VERSION ""

NS_ :

BS_:

BU_: ETH

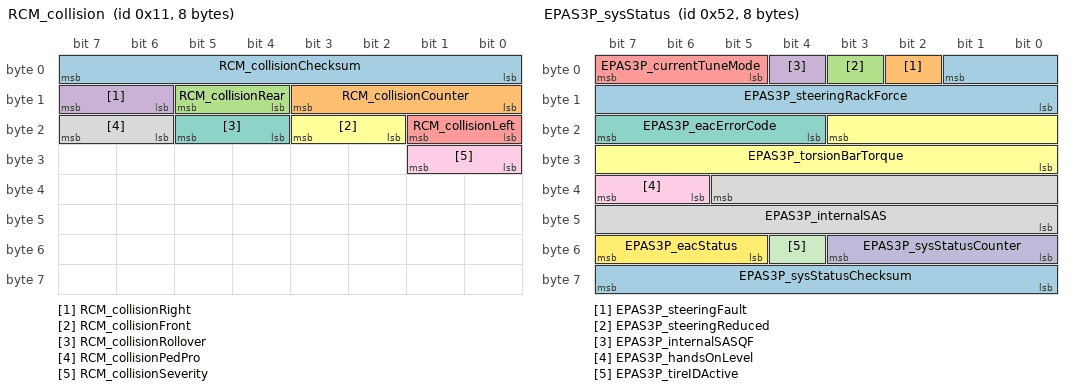
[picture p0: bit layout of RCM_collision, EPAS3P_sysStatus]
BO_ 17 RCM_collision: 8 Vector__XXX
 SG_ RCM_collisionChecksum : 0|8@1+ (1,0) [0|0] "" Vector__XXX
 SG_ RCM_collisionCounter : 8|4@1+ (1,0) [0|0] "" Vector__XXX
 SG_ RCM_collisionRear : 12|2@1+ (1,0) [0|0] "" Vector__XXX
 SG_ RCM_collisionRight : 14|2@1+ (1,0) [0|0] "" Vector__XXX
 SG_ RCM_collisionLeft : 16|2@1+ (1,0) [0|0] "" Vector__XXX
 SG_ RCM_collisionFront : 18|2@1+ (1,0) [0|0] "" Vector__XXX
 SG_ RCM_collisionRollover : 20|2@1+ (1,0) [0|0] "" Vector__XXX
 SG_ RCM_collisionPedPro : 22|2@1+ (1,0) [0|0] "" Vector__XXX
 SG_ RCM_collisionSeverity : 24|2@1+ (1,0) [0|0] "" Vector__XXX

BO_ 49 EPAS3P_status: 8 Vector__XXX
 SG_ EPAS3P_statusCrc : 0|8@1+ (1,0) [0|0] "" Vector__XXX
 SG_ EPAS3P_statusCounter : 8|4@1+ (1,0) [0|0] "" Vector__XXX
 SG_ EPAS3P_state : 12|4@1+ (1,0) [0|0] "" Vector__XXX
 SG_ EPAS3P_powerMode : 16|3@1+ (1,0) [0|0] "" Vector__XXX
 SG_ EPAS3P_role : 19|2@1+ (1,0) [0|0] "" Vector__XXX

BO_ 79 UI_locationStatus: 8 Vector__XXX
 SG_ UI_latitude : 0|28@1- (1e-06,0) [0|0] "" Vector__XXX
 SG_ UI_longitude : 28|29@1- (1e-06,0) [0|0] "" Vector__XXX
 SG_ UI_gpsAccuracy : 57|7@1+ (0.2,0) [0|0] "" Vector__XXX

BO_ 81 EPAS3S_status: 8 Vector__XXX
 SG_ EPAS3S_statusCrc : 0|8@1+ (1,0) [0|0] "" Vector__XXX
 SG_ EPAS3S_statusCounter : 8|4@1+ (1,0) [0|0] "" Vector__XXX
 SG_ EPAS3S_state : 12|4@1+ (1,0) [0|0] "" Vector__XXX
 SG_ EPAS3S_powerMode : 16|3@1+ (1,0) [0|0] "" Vector__XXX
 SG_ EPAS3S_role : 19|2@1+ (1,0) [0|0] "" Vector__XXX

BO_ 82 EPAS3P_sysStatus: 8 Vector__XXX
 SG_ EPAS3P_steeringRackForce : 1|10@0+ (50,-25575) [0|0] "" Vector__XXX
 SG_ EPAS3P_steeringFault : 2|1@0+ (1,0) [0|0] "" Vector__XXX
 SG_ EPAS3P_steeringReduced : 3|1@0+ (1,0) [0|0] "" Vector__XXX
 SG_ EPAS3P_internalSASQF : 4|1@0+ (1,0) [0|0] "" Vector__XXX
 SG_ EPAS3P_currentTuneMode : 7|3@0+ (1,0) [0|0] "" Vector__XXX
 SG_ EPAS3P_torsionBarTorque : 19|12@0+ (0.01,-20.5) [0|0] "" Vector__XXX
 SG_ EPAS3P_eacErrorCode : 23|4@0+ (1,0) [0|0] "" Vector__XXX
 SG_ EPAS3P_internalSAS : 37|14@0+ (0.1,-819.2) [0|0] "" Vector__XXX
 SG_ EPAS3P_handsOnLevel : 39|2@0+ (1,0) [0|0] "" Vector__XXX
 SG_ EPAS3P_sysStatusCounter : 51|4@0+ (1,0) [0|0] "" Vector__XXX
 SG_ EPAS3P_tireIDActive : 52|1@1+ (1,0) [0|0] "" Vector__XXX
 SG_ EPAS3P_eacStatus : 55|3@0+ (1,0) [0|0] "" Vector__XXX
 SG_ EPAS3P_sysStatusChecksum : 63|8@0+ (1,0) [0|0] "" Vector__XXX

BO_ 257 RCM_inertial1: 8 Vector__XXX
 SG_ RCM_yawRate : 0|16@1- (0.0001,0) [0|0] "" Vector__XXX
 SG_ RCM_pitchRate : 16|15@1- (0.00025,0) [0|0] "" Vector__XXX
 SG_ RCM_rollRate : 31|15@1- (0.00025,0) [0|0] "" Vector__XXX
 SG_ RCM_rollRateQF : 46|2@1+ (1,0) [0|0] "" Vector__XXX
 SG_ RCM_yawRateQF : 48|1@1+ (1,0) [0|0] "" Vector__XXX
 SG_ RCM_pitchRateQF : 50|2@1+ (1,0) [0|0] "" Vector__XXX
 SG_ RCM_inertial1Counter : 52|4@1+ (1,0) [0|0] "" Vector__XXX
 SG_ RCM_inertial1Checksum : 56|8@1+ (1,0) [0|0] "" Vector__XXX

BO_ 258 VCLEFT_doorStatus: 8 Vector__XXX
 SG_ VCLEFT_doorClosureStatusFront : 0|4@1+ (1,0) [0|0] "" Vector__XXX
 SG_ VCLEFT_doorClosureStatusRear : 4|4@1+ (1,0) [0|0] "" Vector__XXX
 SG_ VCLEFT_frontLatchSwitch : 8|1@1+ (1,0) [0|0] "" Vector__XXX
 SG_ VCLEFT_rearLatchSwitch : 9|1@1+ (1,0) [0|0] "" Vector__XXX
 SG_ VCLEFT_frontHandlePulled : 10|1@1+ (1,0) [0|0] "" Vector__XXX
 SG_ VCLEFT_rearHandlePulled : 11|1@1+ (1,0) [0|0] "" Vector__XXX
 SG_ VCLEFT_frontRelActuatorSwitch : 12|1@1+ (1,0) [0|0] "" Vector__XXX
 SG_ VCLEFT_rearRelActuatorSwitch : 13|1@1+ (1,0) [0|0] "" Vector__XXX
 SG_ VCLEFT_frontLatchStatus : 14|4@1+ (1,0) [0|0] "" Vector__XXX
 SG_ VCLEFT_rearLatchStatus : 18|4@1+ (1,0) [0|0] "" Vector__XXX
 SG_ VCLEFT_lastDoorReqSourceFront : 22|3@1+ (1,0) [0|0] "" Vector__XXX
 SG_ VCLEFT_lastDoorReqSourceRear : 25|3@1+ (1,0) [0|0] "" Vector__XXX
 SG_ VCLEFT_frontIntSwitchFaulted : 28|1@1+ (1,0) [0|0] "" Vector__XXX
 SG_ VCLEFT_rearIntSwitchFaulted : 29|1@1+ (1,0) [0|0] "" Vector__XXX
 SG_ VCLEFT_frontIntSwitchPressed : 31|1@1+ (1,0) [0|0] "" Vector__XXX
 SG_ VCLEFT_rearIntSwitchPressed : 32|1@1+ (1,0) [0|0] "" Vector__XXX
 SG_ VCLEFT_mirrorTiltXPosition : 33|8@1+ (0.02,0) [0|0] "" Vector__XXX
 SG_ VCLEFT_mirrorTiltYPosition : 41|8@1+ (0.02,0) [0|0] "" Vector__XXX
 SG_ VCLEFT_mirrorState : 49|3@1+ (1,0) [0|0] "" Vector__XXX
 SG_ VCLEFT_mirrorFoldState : 52|3@1+ (1,0) [0|0] "" Vector__XXX
 SG_ VCLEFT_mirrorRecallState : 55|3@1+ (1,0) [0|0] "" Vector__XXX
 SG_ VCLEFT_mirrorHeatState : 58|3@1+ (1,0) [0|0] "" Vector__XXX
 SG_ VCLEFT_rearHandlePulledPersist : 61|1@1+ (1,0) [0|0] "" Vector__XXX
 SG_ VCLEFT_frontHandlePulledPersist : 62|1@1+ (1,0) [0|0] "" Vector__XXX
 SG_ VCLEFT_mirrorDipped : 63|1@1+ (1,0) [0|0] "" Vector__XXX

BO_ 259 VCRIGHT_doorStatus: 8 Vector__XXX
 SG_ VCRIGHT_doorClosureStatusFront : 0|4@1+ (1,0) [0|0] "" Vector__XXX
 SG_ VCRIGHT_doorClosureStatusRear : 4|4@1+ (1,0) [0|0] "" Vector__XXX
 SG_ VCRIGHT_frontLatchSwitch : 8|1@1+ (1,0) [0|0] "" Vector__XXX
 SG_ VCRIGHT_rearLatchSwitch : 9|1@1+ (1,0) [0|0] "" Vector__XXX
 SG_ VCRIGHT_frontHandlePulled : 10|1@1+ (1,0) [0|0] "" Vector__XXX
 SG_ VCRIGHT_rearHandlePulled : 11|1@1+ (1,0) [0|0] "" Vector__XXX
 SG_ VCRIGHT_frontRelActuatorSwitch : 12|1@1+ (1,0) [0|0] "" Vector__XXX
 SG_ VCRIGHT_rearRelActuatorSwitch : 13|1@1+ (1,0) [0|0] "" Vector__XXX
 SG_ VCRIGHT_frontLatchStatus : 14|4@1+ (1,0) [0|0] "" Vector__XXX
 SG_ VCRIGHT_rearLatchStatus : 18|4@1+ (1,0) [0|0] "" Vector__XXX
 SG_ VCRIGHT_lastDoorReqSourceFront : 22|3@1+ (1,0) [0|0] "" Vector__XXX
 SG_ VCRIGHT_lastDoorReqSourceRear : 25|3@1+ (1,0) [0|0] "" Vector__XXX
 SG_ VCRIGHT_frontIntSwitchFaulted : 28|1@1+ (1,0) [0|0] "" Vector__XXX
 SG_ VCRIGHT_rearIntSwitchFaulted : 29|1@1+ (1,0) [0|0] "" Vector__XXX
 SG_ VCRIGHT_frontHandlePulledPersist : 30|1@1+ (1,0) [0|0] "" Vector__XXX
 SG_ VCRIGHT_frontIntSwitchPressed : 31|1@1+ (1,0) [0|0] "" Vector__XXX
 SG_ VCRIGHT_rearIntSwitchPressed : 32|1@1+ (1,0) [0|0] "" Vector__XXX
 SG_ VCRIGHT_mirrorTiltXPosition : 33|8@1+ (0.02,0) [0|0] "" Vector__XXX
 SG_ VCRIGHT_mirrorTiltYPosition : 41|8@1+ (0.02,0) [0|0] "" Vector__XXX
 SG_ VCRIGHT_mirrorState : 49|3@1+ (1,0) [0|0] "" Vector__XXX
 SG_ VCRIGHT_mirrorFoldState : 52|3@1+ (1,0) [0|0] "" Vector__XXX
 SG_ VCRIGHT_mirrorDipped : 55|1@1+ (1,0) [0|0] "" Vector__XXX
 SG_ VCRIGHT_trunkLatchStatus : 56|4@1+ (1,0) [0|0] "" Vector__XXX
 SG_ VCRIGHT_mirrorRecallState : 60|3@1+ (1,0) [0|0] "" Vector__XXX
 SG_ VCRIGHT_rearHandlePulledPersist : 63|1@1+ (1,0) [0|0] "" Vector__XXX

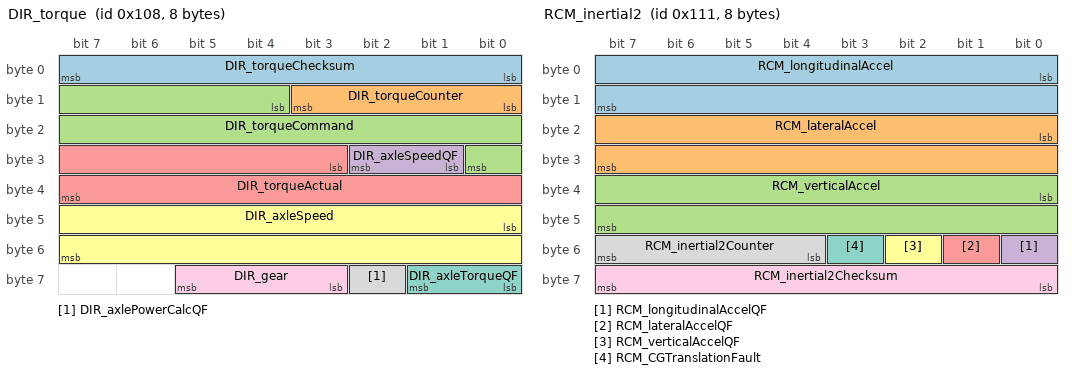
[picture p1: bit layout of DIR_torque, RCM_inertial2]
BO_ 264 DIR_torque: 8 Vector__XXX
 SG_ DIR_torqueChecksum : 0|8@1+ (1,0) [0|0] "" Vector__XXX
 SG_ DIR_torqueCounter : 8|4@1+ (1,0) [0|0] "" Vector__XXX
 SG_ DIR_torqueCommand : 12|13@1- (2,0) [0|0] "" Vector__XXX
 SG_ DIR_axleSpeedQF : 25|2@1+ (1,0) [0|0] "" Vector__XXX
 SG_ DIR_torqueActual : 27|13@1- (2,0) [0|0] "" Vector__XXX
 SG_ DIR_axleSpeed : 40|16@1- (0.1,0) [0|0] "" Vector__XXX
 SG_ DIR_axleTorqueQF : 56|2@1+ (1,0) [0|0] "" Vector__XXX
 SG_ DIR_axlePowerCalcQF : 58|1@1+ (1,0) [0|0] "" Vector__XXX
 SG_ DIR_gear : 59|3@1+ (1,0) [0|0] "" Vector__XXX

BO_ 273 RCM_inertial2: 8 Vector__XXX
 SG_ RCM_longitudinalAccel : 0|16@1- (0.00125,0) [0|0] "" Vector__XXX
 SG_ RCM_lateralAccel : 16|16@1- (0.00125,0) [0|0] "" Vector__XXX
 SG_ RCM_verticalAccel : 32|16@1- (0.00125,0) [0|0] "" Vector__XXX
 SG_ RCM_longitudinalAccelQF : 48|1@1+ (1,0) [0|0] "" Vector__XXX
 SG_ RCM_lateralAccelQF : 49|1@1+ (1,0) [0|0] "" Vector__XXX
 SG_ RCM_verticalAccelQF : 50|1@1+ (1,0) [0|0] "" Vector__XXX
 SG_ RCM_CGTranslationFault : 51|1@1+ (1,0) [0|0] "" Vector__XXX
 SG_ RCM_inertial2Counter : 52|4@1+ (1,0) [0|0] "" Vector__XXX
 SG_ RCM_inertial2Checksum : 56|8@1+ (1,0) [0|0] "" Vector__XXX

BO_ 280 DI_systemStatus: 8 Vector__XXX
 SG_ DI_systemStatusChecksum : 0|8@1+ (1,0) [0|0] "" Vector__XXX
 SG_ DI_systemStatusCounter : 8|4@1+ (1,0) [0|0] "" Vector__XXX
 SG_ DI_immobilizerState : 13|3@1+ (1,0) [0|0] "" Vector__XXX
 SG_ DI_systemState : 16|3@1+ (1,0) [0|0] "" Vector__XXX
 SG_ DI_brakePedalState : 19|2@1+ (1,0) [0|0] "" Vector__XXX
 SG_ DI_gear : 21|3@1+ (1,0) [0|0] "" Vector__XXX
 SG_ DI_driveBlocked : 24|3@1+ (1,0) [0|0] "" Vector__XXX
 SG_ DI_hvilSystemStatus : 27|2@1+ (1,0) [0|0] "" Vector__XXX
 SG_ DI_accelPedalPos : 32|8@1+ (0.4,0) [0|0] "" Vector__XXX
 SG_ DI_tractionControlMode : 40|3@1+ (1,0) [0|0] "" Vector__XXX
 SG_ DI_dynoModeAvailable : 43|1@1+ (1,0) [0|0] "" Vector__XXX
 SG_ DI_epbRequest : 44|2@1+ (1,0) [0|0] "" Vector__XXX
 SG_ DI_eepDeliveryBitStatus : 46|1@1+ (1,0) [0|0] "" Vector__XXX
 SG_ DI_keepDrivePowerStateRequest : 47|1@1+ (1,0) [0|0] "" Vector__XXX
 SG_ DI_trackModeState : 48|2@1+ (1,0) [0|0] "" Vector__XXX
 SG_ DI_manualDrivingProhibited : 50|1@1+ (1,0) [0|0] "" Vector__XXX
 SG_ DI_regenLight : 51|1@1+ (1,0) [0|0] "" Vector__XXX
 SG_ DI_vehicleAcceleration : 52|12@1- (0.01,0) [0|0] "" Vector__XXX

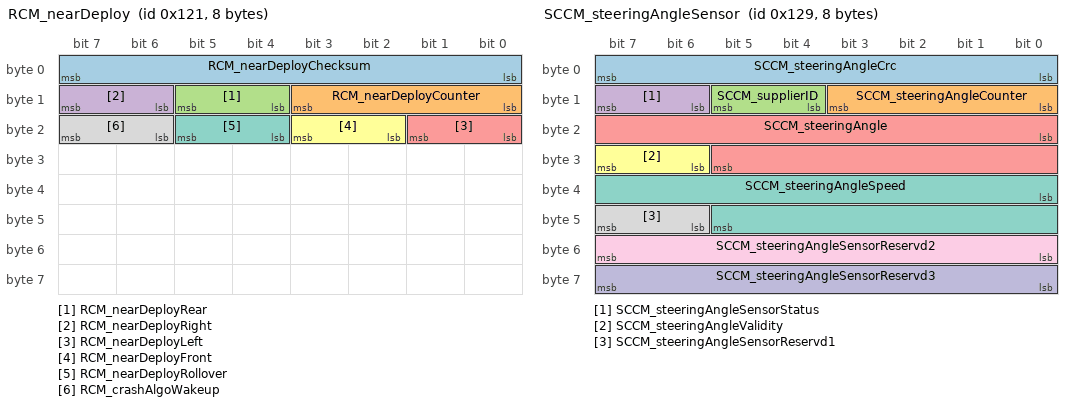
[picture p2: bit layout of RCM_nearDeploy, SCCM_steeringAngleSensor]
BO_ 289 RCM_nearDeploy: 8 Vector__XXX
 SG_ RCM_nearDeployChecksum : 0|8@1+ (1,0) [0|0] "" Vector__XXX
 SG_ RCM_nearDeployCounter : 8|4@1+ (1,0) [0|0] "" Vector__XXX
 SG_ RCM_nearDeployRear : 12|2@1+ (1,0) [0|0] "" Vector__XXX
 SG_ RCM_nearDeployRight : 14|2@1+ (1,0) [0|0] "" Vector__XXX
 SG_ RCM_nearDeployLeft : 16|2@1+ (1,0) [0|0] "" Vector__XXX
 SG_ RCM_nearDeployFront : 18|2@1+ (1,0) [0|0] "" Vector__XXX
 SG_ RCM_nearDeployRollover : 20|2@1+ (1,0) [0|0] "" Vector__XXX
 SG_ RCM_crashAlgoWakeup : 22|2@1+ (1,0) [0|0] "" Vector__XXX

BO_ 297 SCCM_steeringAngleSensor: 8 Vector__XXX
 SG_ SCCM_steeringAngleCrc : 0|8@1+ (1,0) [0|0] "" Vector__XXX
 SG_ SCCM_steeringAngleCounter : 8|4@1+ (1,0) [0|0] "" Vector__XXX
 SG_ SCCM_supplierID : 12|2@1+ (1,0) [0|0] "" Vector__XXX
 SG_ SCCM_steeringAngleSensorStatus : 14|2@1+ (1,0) [0|0] "" Vector__XXX
 SG_ SCCM_steeringAngle : 16|14@1+ (0.1,-819.2) [0|0] "" Vector__XXX
 SG_ SCCM_steeringAngleValidity : 30|2@1+ (1,0) [0|0] "" Vector__XXX
 SG_ SCCM_steeringAngleSpeed : 32|14@1+ (0.5,-4096) [0|0] "" Vector__XXX
 SG_ SCCM_steeringAngleSensorReservd1 : 46|2@1+ (1,0) [0|0] "" Vector__XXX
 SG_ SCCM_steeringAngleSensorReservd2 : 48|8@1+ (1,0) [0|0] "" Vector__XXX
 SG_ SCCM_steeringAngleSensorReservd3 : 56|8@1+ (1,0) [0|0] "" Vector__XXX

BO_ 305 RCM_inertial3: 8 Vector__XXX
 SG_ RCM_yawRateRaw : 0|16@1- (0.0001,0) [0|0] "" Vector__XXX
 SG_ RCM_pitchRateRaw : 16|15@1- (0.00025,0) [0|0] "" Vector__XXX
 SG_ RCM_rollRateRaw : 31|15@1- (0.00025,0) [0|0] "" Vector__XXX
 SG_ RCM_rollRateRawQF : 46|2@1+ (1,0) [0|0] "" Vector__XXX
 SG_ RCM_yawRateRawQF : 48|1@1+ (1,0) [0|0] "" Vector__XXX
 SG_ RCM_pitchRateRawQF : 50|2@1+ (1,0) [0|0] "" Vector__XXX
 SG_ RCM_inertial3Counter : 52|4@1+ (1,0) [0|0] "" Vector__XXX
 SG_ RCM_inertial3Checksum : 56|8@1+ (1,0) [0|0] "" Vector__XXX

BO_ 321 RCM_inertial4: 8 Vector__XXX
 SG_ RCM_longitudinalAccelRaw : 0|16@1- (0.00125,0) [0|0] "" Vector__XXX
 SG_ RCM_lateralAccelRaw : 16|16@1- (0.00125,0) [0|0] "" Vector__XXX
 SG_ RCM_verticalAccelRaw : 32|16@1- (0.00125,0) [0|0] "" Vector__XXX
 SG_ RCM_longitudinalAccelRawQF : 48|1@1+ (1,0) [0|0] "" Vector__XXX
 SG_ RCM_lateralAccelRawQF : 49|1@1+ (1,0) [0|0] "" Vector__XXX
 SG_ RCM_verticalAccelRawQF : 50|1@1+ (1,0) [0|0] "" Vector__XXX
 SG_ RCM_inertial4Counter : 52|4@1+ (1,0) [0|0] "" Vector__XXX
 SG_ RCM_inertial4Checksum : 56|8@1+ (1,0) [0|0] "" Vector__XXX

BO_ 325 ESP_status: 8 Vector__XXX
 SG_ ESP_statusChecksum : 0|8@1+ (1,0) [0|0] "" Vector__XXX
 SG_ ESP_statusCounter : 8|4@1+ (1,0) [0|0] "" Vector__XXX
 SG_ ESP_espModeActive : 12|2@1+ (1,0) [0|0] "" Vector__XXX
 SG_ ESP_stabilityControlSts2 : 14|2@1+ (1,0) [0|0] "" Vector__XXX
 SG_ ESP_ebdFaultLamp : 16|1@1+ (1,0) [0|0] "" Vector__XXX
 SG_ ESP_absFaultLamp : 17|1@1+ (1,0) [0|0] "" Vector__XXX
 SG_ ESP_espFaultLamp : 18|1@1+ (1,0) [0|0] "" Vector__XXX
 SG_ ESP_hydraulicBoostEnabled : 19|1@1+ (1,0) [0|0] "" Vector__XXX
 SG_ ESP_espLampFlash : 20|1@1+ (1,0) [0|0] "" Vector__XXX
 SG_ ESP_brakeLamp : 21|1@1+ (1,0) [0|0] "" Vector__XXX
 SG_ ESP_absBrakeEvent2 : 22|2@1+ (1,0) [0|0] "" Vector__XXX
 SG_ ESP_longitudinalAccelQF : 24|1@1+ (1,0) [0|0] "" Vector__XXX
 SG_ ESP_lateralAccelQF : 25|1@1+ (1,0) [0|0] "" Vector__XXX
 SG_ ESP_yawRateQF : 26|1@1+ (1,0) [0|0] "" Vector__XXX
 SG_ ESP_steeringAngleQF : 27|1@1+ (1,0) [0|0] "" Vector__XXX
 SG_ ESP_brakeDiscWipingActive : 28|1@1+ (1,0) [0|0] "" Vector__XXX
 SG_ ESP_driverBrakeApply : 29|2@1+ (1,0) [0|0] "" Vector__XXX
 SG_ ESP_brakeApply : 31|1@1+ (1,0) [0|0] "" Vector__XXX
 SG_ ESP_aesPrimaryActuatorStatus : 32|2@1+ (1,0) [0|0] "" Vector__XXX
 SG_ ESP_cdpStatus : 34|2@1+ (1,0) [0|0] "" Vector__XXX
 SG_ ESP_ptcTargetState : 36|2@1+ (1,0) [0|0] "" Vector__XXX
 SG_ ESP_btcTargetState : 38|2@1+ (1,0) [0|0] "" Vector__XXX
 SG_ ESP_ebrStandstillSkid : 48|1@1+ (1,0) [0|0] "" Vector__XXX
 SG_ ESP_ebrStatus : 49|2@1+ (1,0) [0|0] "" Vector__XXX
 SG_ ESP_brakeTorqueTarget : 51|13@1+ (3,0) [0|0] "" Vector__XXX

BO_ 331 APP_inertial1: 8 Vector__XXX
 SG_ APP_yawRateRaw : 0|16@1- (0.0001,0) [0|0] "" Vector__XXX
 SG_ APP_pitchRateRaw : 16|15@1- (0.00025,0) [0|0] "" Vector__XXX
 SG_ APP_rollRateRaw : 31|15@1- (0.00025,0) [0|0] "" Vector__XXX
 SG_ APP_gyroscopeBiasCompensationValid : 46|1@1+ (1,0) [0|0] "" Vector__XXX
 SG_ APP_gyroscopeScaleCompensationValid : 47|1@1+ (1,0) [0|0] "" Vector__XXX
 SG_ APP_inertial1Counter : 52|4@1+ (1,0) [0|0] "" Vector__XXX
 SG_ APP_inertial1Checksum : 56|8@1+ (1,0) [0|0] "" Vector__XXX

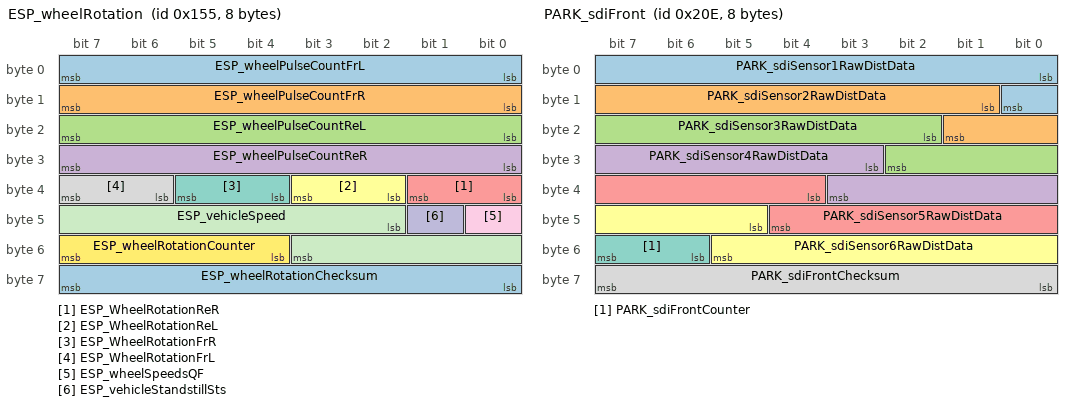
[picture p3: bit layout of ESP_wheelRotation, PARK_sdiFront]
BO_ 341 ESP_wheelRotation: 8 Vector__XXX
 SG_ ESP_wheelPulseCountFrL : 0|8@1+ (1,0) [0|0] "" Vector__XXX
 SG_ ESP_wheelPulseCountFrR : 8|8@1+ (1,0) [0|0] "" Vector__XXX
 SG_ ESP_wheelPulseCountReL : 16|8@1+ (1,0) [0|0] "" Vector__XXX
 SG_ ESP_wheelPulseCountReR : 24|8@1+ (1,0) [0|0] "" Vector__XXX
 SG_ ESP_WheelRotationReR : 32|2@1+ (1,0) [0|0] "" Vector__XXX
 SG_ ESP_WheelRotationReL : 34|2@1+ (1,0) [0|0] "" Vector__XXX
 SG_ ESP_WheelRotationFrR : 36|2@1+ (1,0) [0|0] "" Vector__XXX
 SG_ ESP_WheelRotationFrL : 38|2@1+ (1,0) [0|0] "" Vector__XXX
 SG_ ESP_wheelSpeedsQF : 40|1@1+ (1,0) [0|0] "" Vector__XXX
 SG_ ESP_vehicleStandstillSts : 41|1@1+ (1,0) [0|0] "" Vector__XXX
 SG_ ESP_vehicleSpeed : 42|10@1+ (0.5,0) [0|0] "" Vector__XXX
 SG_ ESP_wheelRotationCounter : 52|4@1+ (1,0) [0|0] "" Vector__XXX
 SG_ ESP_wheelRotationChecksum : 56|8@1+ (1,0) [0|0] "" Vector__XXX

BO_ 373 ESP_wheelSpeeds: 8 Vector__XXX
 SG_ ESP_wheelSpeedFrL : 0|13@1+ (0.042,0) [0|0] "" Vector__XXX
 SG_ ESP_wheelSpeedFrR : 13|13@1+ (0.042,0) [0|0] "" Vector__XXX
 SG_ ESP_wheelSpeedReL : 26|13@1+ (0.042,0) [0|0] "" Vector__XXX
 SG_ ESP_wheelSpeedReR : 39|13@1+ (0.042,0) [0|0] "" Vector__XXX
 SG_ ESP_wheelSpeedsCounter : 52|4@1+ (1,0) [0|0] "" Vector__XXX
 SG_ ESP_wheelSpeedsChecksum : 56|8@1+ (1,0) [0|0] "" Vector__XXX

BO_ 389 ESP_brakeTorque: 8 Vector__XXX
 SG_ ESP_brakeTorqueFrL : 0|12@1+ (3,0) [0|0] "" Vector__XXX
 SG_ ESP_brakeTorqueFrR : 12|12@1+ (3,0) [0|0] "" Vector__XXX
 SG_ ESP_brakeTorqueReL : 24|12@1+ (3,0) [0|0] "" Vector__XXX
 SG_ ESP_brakeTorqueReR : 36|12@1+ (3,0) [0|0] "" Vector__XXX
 SG_ ESP_brakeTorqueQF : 50|1@1+ (1,0) [0|0] "" Vector__XXX
 SG_ ESP_brakeTorqueCounter : 52|4@1+ (1,0) [0|0] "" Vector__XXX
 SG_ ESP_brakeTorqueChecksum : 56|8@1+ (1,0) [0|0] "" Vector__XXX

BO_ 395 APP_inertial2: 8 Vector__XXX
 SG_ APP_longitudinalAccelRaw : 0|16@1- (0.00125,0) [0|0] "" Vector__XXX
 SG_ APP_lateralAccelRaw : 16|16@1- (0.00125,0) [0|0] "" Vector__XXX
 SG_ APP_verticalAccelRaw : 32|16@1- (0.00125,0) [0|0] "" Vector__XXX
 SG_ APP_accelerometerBiasCompensationValid : 48|1@1+ (1,0) [0|0] "" Vector__XXX
 SG_ APP_accelerometerScaleCompensationValid : 49|1@1+ (1,0) [0|0] "" Vector__XXX
 SG_ APP_inertial2Counter : 52|4@1+ (1,0) [0|0] "" Vector__XXX
 SG_ APP_inertial2Checksum : 56|8@1+ (1,0) [0|0] "" Vector__XXX

BO_ 454 GTW_canErrorCounters: 8 Vector__XXX
 SG_ GTW_PARTY_canTxErrCount : 0|8@1+ (1,0) [0|0] "" Vector__XXX
 SG_ GTW_PARTY_canRxErrCount : 8|8@1+ (1,0) [0|0] "" Vector__XXX
 SG_ GTW_VEH_canTxErrCount : 16|8@1+ (1,0) [0|0] "" Vector__XXX
 SG_ GTW_VEH_canRxErrCount : 24|8@1+ (1,0) [0|0] "" Vector__XXX
 SG_ GTW_CH_canTxErrCount : 32|8@1+ (1,0) [0|0] "" Vector__XXX
 SG_ GTW_CH_canRxErrCount : 40|8@1+ (1,0) [0|0] "" Vector__XXX

BO_ 521 DAS_longControl: 8 Vector__XXX
 SG_ DAS_longControlChecksum : 0|8@1+ (1,0) [0|0] "" Vector__XXX
 SG_ DAS_longControlCounter : 8|3@1+ (1,0) [0|0] "" Vector__XXX
 SG_ DAS_gearRequest : 11|2@1+ (1,0) [0|0] "" Vector__XXX
 SG_ DAS_velocityProfile_accelFwd_t0 m3 : 13|11@1- (0.012,-0.216) [0|0] "" Vector__XXX
 SG_ DAS_torqueProfiler_accelMinPed m2 : 14|9@1+ (0.04,-15) [0|0] "" Vector__XXX
 SG_ DAS_aebControl_active m4 : 16|2@1+ (1,0) [0|0] "" Vector__XXX
 SG_ DAS_pedalControl_accelPedalPos m5 : 16|12@1+ (0.025,0) [0|0] "" Vector__XXX
 SG_ DAS_torqueControl_sysTorqueCommandFwd m6 : 16|15@1- (2,0) [0|0] "" Vector__XXX
 SG_ DAS_aebControl_targetAccelDis m4 : 18|11@1- (0.01,-7.5) [0|0] "" Vector__XXX
 SG_ DAS_torqueProfiler_accelMaxPed m2 : 23|9@1+ (0.04,-15) [0|0] "" Vector__XXX
 SG_ DAS_velocityProfile_jerkFwd_t0t1 m3 : 24|8@1- (0.12,0) [0|0] "" Vector__XXX
 SG_ DAS_pedalControl_brakeTorqueCommand m5 : 32|13@1+ (3.5,0) [0|0] "" Vector__XXX
 SG_ DAS_torqueControl_standstillRequest m6 : 32|1@1+ (1,0) [0|0] "" Vector__XXX
 SG_ DAS_torqueProfiler_targetSpeedPed m2 : 32|12@1+ (0.1,0) [0|0] "" Vector__XXX
 SG_ DAS_velocityProfile_futureTargetSpeedFwd m3 : 32|12@1- (0.08,80.08) [0|0] "" Vector__XXX
 SG_ DAS_torqueProfiler_jerkMinPed m2 : 44|9@1+ (0.03,-15.232) [0|0] "" Vector__XXX
 SG_ DAS_velocityProfile_jerkFwd_t1t2 m3 : 44|8@1- (0.12,0) [0|0] "" Vector__XXX
 SG_ DAS_velocityProfile_maxAllowedTargetErrorReg m3 : 52|6@1- (0.1,1.1) [0|0] "" Vector__XXX
 SG_ DAS_torqueProfiler_jerkMaxPed m2 : 53|8@1+ (0.059,0) [0|0] "" Vector__XXX
 SG_ DAS_velocityProfile_calcDelay m3 : 58|3@1+ (0.006666666666666667,0) [0|0] "" Vector__XXX
 SG_ DAS_longControlStack M : 61|3@1+ (1,0) [0|0] "" Vector__XXX

BO_ 522 DAS_longControlTuningParameters: 8 Vector__XXX
 SG_ DAS_longControlTuningParametersChecksum : 0|8@1+ (1,0) [0|0] "" Vector__XXX
 SG_ DAS_longControlTuningParametersCounter : 8|3@1+ (1,0) [0|0] "" Vector__XXX
 SG_ DAS_velocityProfile_delayBeforet0 : 11|7@1+ (0.01,0) [0|0] "" Vector__XXX
 SG_ DAS_velocityProfile_futureTargetSpeedFwdDt : 18|7@1+ (0.01,0) [0|0] "" Vector__XXX
 SG_ DAS_velocityProfile_Dt_t0t1 : 32|7@1+ (0.01,0) [0|0] "" Vector__XXX
 SG_ DAS_velocityProfile_Dt_t1t2 : 39|7@1+ (0.01,0) [0|0] "" Vector__XXX

BO_ 526 PARK_sdiFront: 8 Vector__XXX
 SG_ PARK_sdiSensor1RawDistData : 0|9@1+ (1,0) [0|0] "" Vector__XXX
 SG_ PARK_sdiSensor2RawDistData : 9|9@1+ (1,0) [0|0] "" Vector__XXX
 SG_ PARK_sdiSensor3RawDistData : 18|9@1+ (1,0) [0|0] "" Vector__XXX
 SG_ PARK_sdiSensor4RawDistData : 27|9@1+ (1,0) [0|0] "" Vector__XXX
 SG_ PARK_sdiSensor5RawDistData : 36|9@1+ (1,0) [0|0] "" Vector__XXX
 SG_ PARK_sdiSensor6RawDistData : 45|9@1+ (1,0) [0|0] "" Vector__XXX
 SG_ PARK_sdiFrontCounter : 54|2@1+ (1,0) [0|0] "" Vector__XXX
 SG_ PARK_sdiFrontChecksum : 56|8@1+ (1,0) [0|0] "" Vector__XXX

BO_ 529 RCM_status: 8 Vector__XXX
 SG_ RCM_statusChecksum : 0|8@1+ (1,0) [0|0] "" Vector__XXX
 SG_ RCM_statusCounter : 8|4@1+ (1,0) [0|0] "" Vector__XXX
 SG_ RCM_armStatus : 12|2@1+ (1,0) [0|0] "" Vector__XXX
 SG_ RCM_warningIndicatorState : 14|2@1+ (1,0) [0|0] "" Vector__XXX
 SG_ RCM_passAirbagIndicatorRequest : 16|2@1+ (1,0) [0|0] "" Vector__XXX
 SG_ RCM_airbagCutoffStatus : 18|2@1+ (1,0) [0|0] "" Vector__XXX
 SG_ RCM_alrSwitchStatus : 20|2@1+ (1,0) [0|0] "" Vector__XXX
 SG_ RCM_vinLearnFlag : 22|2@1+ (1,0) [0|0] "" Vector__XXX
 SG_ RCM_seatTrackPositionDrvr : 24|2@1+ (1,0) [0|0] "" Vector__XXX
 SG_ RCM_seatTrackPositionPass : 26|2@1+ (1,0) [0|0] "" Vector__XXX
 SG_ RCM_edr1State : 28|2@1+ (1,0) [0|0] "" Vector__XXX
 SG_ RCM_edr2State : 30|2@1+ (1,0) [0|0] "" Vector__XXX
 SG_ RCM_keepPowerReason : 32|4@1+ (1,0) [0|0] "" Vector__XXX
 SG_ RCM_imuOffsetLearnState : 36|2@1+ (1,0) [0|0] "" Vector__XXX
 SG_ RCM_edr3State : 38|2@1+ (1,0) [0|0] "" Vector__XXX
 SG_ RCM_driverOrientationInitStatus : 40|3@1+ (1,0) [0|0] "" Vector__XXX
 SG_ RCM_occupantClassificationSource : 43|1@1+ (1,0) [0|0] "" Vector__XXX
 SG_ RCM_pedProEDR1State : 44|2@1+ (1,0) [0|0] "" Vector__XXX
 SG_ RCM_pedProEDR2State : 46|2@1+ (1,0) [0|0] "" Vector__XXX

BO_ 536 UI_driverAssistRoadSign: 8 Vector__XXX
 SG_ UI_roadSign M : 0|8@1+ (1,0) [0|0] "" Vector__XXX
 SG_ UI_baseMapSpeedLimitMPS m3 : 8|8@1+ (0.25,0) [0|0] "" Vector__XXX
 SG_ UI_currSplineIdFull m5 : 8|32@1+ (1,0) [0|0] "" Vector__XXX
 SG_ UI_dummyData m0 : 8|1@1+ (1,0) [0|0] "" Vector__XXX
 SG_ UI_meanFleetSplineSpeedMPS m4 : 8|8@1+ (0.25,0) [0|0] "" Vector__XXX
 SG_ UI_stopSignStopLineDist m1 : 8|10@1+ (0.25,-8) [0|0] "" Vector__XXX
 SG_ UI_trafficLightStopLineDist m2 : 8|10@1+ (0.25,-8) [0|0] "" Vector__XXX
 SG_ UI_bottomQrtlFleetSpeedMPS m3 : 16|8@1+ (0.25,0) [0|0] "" Vector__XXX
 SG_ UI_medianFleetSpeedMPS m4 : 16|8@1+ (0.25,0) [0|0] "" Vector__XXX
 SG_ UI_stopSignStopLineConf m1 : 18|7@1+ (1,0) [0|0] "" Vector__XXX
 SG_ UI_trafficLightStopLineConf m2 : 18|7@1+ (1,0) [0|0] "" Vector__XXX
 SG_ UI_meanFleetSplineAccelMPS2 m4 : 24|8@1+ (0.05,-6.35) [0|0] "" Vector__XXX
 SG_ UI_topQrtlFleetSpeedMPS m3 : 24|8@1+ (0.25,0) [0|0] "" Vector__XXX
 SG_ UI_rampType m4 : 32|3@1+ (1,0) [0|0] "" Vector__XXX
 SG_ UI_valhallaRamp m4 : 35|2@1+ (1,0) [0|0] "" Vector__XXX
 SG_ UI_overrideACMFleetSpeed m4 : 38|1@1+ (1,0) [0|0] "" Vector__XXX
 SG_ UI_splineLocConfidence : 40|7@1+ (1,0) [0|0] "" Vector__XXX
 SG_ UI_splineID : 48|4@1+ (1,0) [0|0] "" Vector__XXX
 SG_ UI_roadSignCounter : 52|4@1+ (1,0) [0|0] "" Vector__XXX
 SG_ UI_roadSignChecksum : 56|8@1+ (1,0) [0|0] "" Vector__XXX

BO_ 537 DAS_pscControl: 8 Vector__XXX
 SG_ DAS_pscControlCounter : 0|4@1+ (1,0) [0|0] "" Vector__XXX
 SG_ DAS_pscParkState : 4|4@1+ (1,0) [0|0] "" Vector__XXX
 SG_ DAS_eacState : 8|3@1+ (1,0) [0|0] "" Vector__XXX
 SG_ DAS_wheelType : 11|5@1+ (1,0) [0|0] "" Vector__XXX
 SG_ DAS_pscControlChecksum : 16|8@1+ (1,0) [0|0] "" Vector__XXX

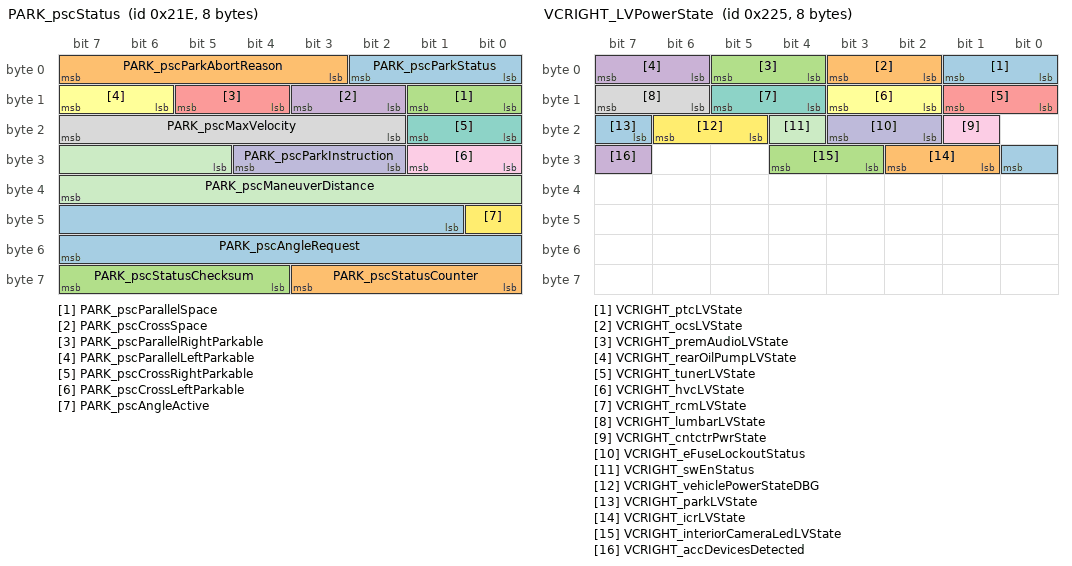
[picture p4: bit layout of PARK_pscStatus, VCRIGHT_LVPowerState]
BO_ 542 PARK_pscStatus: 8 Vector__XXX
 SG_ PARK_pscParkStatus : 0|3@1+ (1,0) [0|0] "" Vector__XXX
 SG_ PARK_pscParkAbortReason : 3|5@1+ (1,0) [0|0] "" Vector__XXX
 SG_ PARK_pscParallelSpace : 8|2@1+ (1,0) [0|0] "" Vector__XXX
 SG_ PARK_pscCrossSpace : 10|2@1+ (1,0) [0|0] "" Vector__XXX
 SG_ PARK_pscParallelRightParkable : 12|2@1+ (1,0) [0|0] "" Vector__XXX
 SG_ PARK_pscParallelLeftParkable : 14|2@1+ (1,0) [0|0] "" Vector__XXX
 SG_ PARK_pscCrossRightParkable : 16|2@1+ (1,0) [0|0] "" Vector__XXX
 SG_ PARK_pscMaxVelocity : 18|6@1+ (0.1,0) [0|0] "" Vector__XXX
 SG_ PARK_pscCrossLeftParkable : 24|2@1+ (1,0) [0|0] "" Vector__XXX
 SG_ PARK_pscParkInstruction : 26|3@1+ (1,0) [0|0] "" Vector__XXX
 SG_ PARK_pscManeuverDistance : 29|11@1+ (1,0) [0|0] "" Vector__XXX
 SG_ PARK_pscAngleActive : 40|1@1+ (1,0) [0|0] "" Vector__XXX
 SG_ PARK_pscAngleRequest : 41|15@1+ (0.1,-1638.4) [0|0] "" Vector__XXX
 SG_ PARK_pscStatusCounter : 56|4@1+ (1,0) [0|0] "" Vector__XXX
 SG_ PARK_pscStatusChecksum : 60|4@1+ (1,0) [0|0] "" Vector__XXX

BO_ 545 VCFRONT_LVPowerState: 8 Vector__XXX
 SG_ VCFRONT_LVPowerStateIndex M : 0|5@1+ (1,0) [0|0] "" Vector__XXX
 SG_ VCFRONT_vehiclePowerState : 5|2@1+ (1,0) [0|0] "" Vector__XXX
 SG_ VCFRONT_cpLVRequest m1 : 8|2@1+ (1,0) [0|0] "" Vector__XXX
 SG_ VCFRONT_parkLVState m0 : 8|2@1+ (1,0) [0|0] "" Vector__XXX
 SG_ VCFRONT_epasLVState m1 : 10|2@1+ (1,0) [0|0] "" Vector__XXX
 SG_ VCFRONT_espLVState m0 : 10|2@1+ (1,0) [0|0] "" Vector__XXX
 SG_ VCFRONT_hvcLVRequest m1 : 12|2@1+ (1,0) [0|0] "" Vector__XXX
 SG_ VCFRONT_radcLVState m0 : 12|2@1+ (1,0) [0|0] "" Vector__XXX
 SG_ VCFRONT_hvacCompLVState m0 : 14|2@1+ (1,0) [0|0] "" Vector__XXX
 SG_ VCFRONT_tasLVState m1 : 14|2@1+ (1,0) [0|0] "" Vector__XXX
 SG_ VCFRONT_pcsLVState m1 : 16|2@1+ (1,0) [0|0] "" Vector__XXX
 SG_ VCFRONT_ptcLVRequest m0 : 16|2@1+ (1,0) [0|0] "" Vector__XXX
 SG_ VCFRONT_CMPDLVState m1 : 18|2@1+ (1,0) [0|0] "" Vector__XXX
 SG_ VCFRONT_sccmLVRequest m0 : 18|2@1+ (1,0) [0|0] "" Vector__XXX
 SG_ VCFRONT_hcmlLVState m1 : 20|2@1+ (1,0) [0|0] "" Vector__XXX
 SG_ VCFRONT_tpmsLVRequest m0 : 20|2@1+ (1,0) [0|0] "" Vector__XXX
 SG_ VCFRONT_hcmrLVState m1 : 22|2@1+ (1,0) [0|0] "" Vector__XXX
 SG_ VCFRONT_rcmLVRequest m0 : 22|2@1+ (1,0) [0|0] "" Vector__XXX
 SG_ VCFRONT_MCUAudioLVState m1 : 24|2@1+ (1,0) [0|0] "" Vector__XXX
 SG_ VCFRONT_iBoosterLVState m0 : 24|2@1+ (1,0) [0|0] "" Vector__XXX
 SG_ VCFRONT_espValveLVState m1 : 26|2@1+ (1,0) [0|0] "" Vector__XXX
 SG_ VCFRONT_tunerLVRequest m0 : 26|2@1+ (1,0) [0|0] "" Vector__XXX
 SG_ VCFRONT_MCUGraphicsLVState m1 : 28|2@1+ (1,0) [0|0] "" Vector__XXX
 SG_ VCFRONT_amplifierLVRequest m0 : 28|2@1+ (1,0) [0|0] "" Vector__XXX
 SG_ VCFRONT_das1HighCurrentLVState m0 : 30|2@1+ (1,0) [0|0] "" Vector__XXX
 SG_ VC_dcdcSupportRequest m1 : 30|1@1+ (1,0) [0|0] "" Vector__XXX
 SG_ VC_hvStateRequest m1 : 31|3@1+ (1,0) [0|0] "" Vector__XXX
 SG_ VCFRONT_das2HighCurrentLVState m0 : 32|2@1+ (1,0) [0|0] "" Vector__XXX
 SG_ VCFRONT_dirLVRequest m0 : 34|2@1+ (1,0) [0|0] "" Vector__XXX
 SG_ VCFRONT_difLVState m0 : 36|2@1+ (1,0) [0|0] "" Vector__XXX
 SG_ VCFRONT_oilPumpFrontLVState m0 : 38|2@1+ (1,0) [0|0] "" Vector__XXX
 SG_ VC_persistAccPowerRequestOverridden m1 : 39|1@1+ (1,0) [0|0] "" Vector__XXX
 SG_ VCFRONT_oilPumpRearLVRequest m0 : 40|2@1+ (1,0) [0|0] "" Vector__XXX
 SG_ VC_accPortPowerRequest m1 : 40|1@1+ (1,0) [0|0] "" Vector__XXX
 SG_ VC_persistAccPortPowerState m1 : 41|3@1+ (1,0) [0|0] "" Vector__XXX
 SG_ VCFRONT_ocsLVRequest m0 : 42|2@1+ (1,0) [0|0] "" Vector__XXX
 SG_ VCFRONT_vcleftHiCurrentLVState m0 : 44|2@1+ (1,0) [0|0] "" Vector__XXX
 SG_ VCFRONT_vcrightHiCurrentLVState m0 : 46|2@1+ (1,0) [0|0] "" Vector__XXX
 SG_ VC_noAccDeviceDetectedWhileIdle m1 : 46|1@1+ (1,0) [0|0] "" Vector__XXX
 SG_ VCFRONT_uiHiCurrentLVState m0 : 48|2@1+ (1,0) [0|0] "" Vector__XXX
 SG_ VCFRONT_inAccessoryPlus : 50|1@1+ (1,0) [0|0] "" Vector__XXX
 SG_ VCFRONT_LVShuttingDown : 51|1@1+ (1,0) [0|0] "" Vector__XXX
 SG_ VCFRONT_LVPowerStateCounter : 52|4@1+ (1,0) [0|0] "" Vector__XXX
 SG_ VCFRONT_LVPowerStateChecksum : 56|8@1+ (1,0) [0|0] "" Vector__XXX

BO_ 549 VCRIGHT_LVPowerState: 8 Vector__XXX
 SG_ VCRIGHT_ptcLVState : 0|2@1+ (1,0) [0|0] "" Vector__XXX
 SG_ VCRIGHT_ocsLVState : 2|2@1+ (1,0) [0|0] "" Vector__XXX
 SG_ VCRIGHT_premAudioLVState : 4|2@1+ (1,0) [0|0] "" Vector__XXX
 SG_ VCRIGHT_rearOilPumpLVState : 6|2@1+ (1,0) [0|0] "" Vector__XXX
 SG_ VCRIGHT_tunerLVState : 8|2@1+ (1,0) [0|0] "" Vector__XXX
 SG_ VCRIGHT_hvcLVState : 10|2@1+ (1,0) [0|0] "" Vector__XXX
 SG_ VCRIGHT_rcmLVState : 12|2@1+ (1,0) [0|0] "" Vector__XXX
 SG_ VCRIGHT_lumbarLVState : 14|2@1+ (1,0) [0|0] "" Vector__XXX
 SG_ VCRIGHT_cntctrPwrState : 17|1@1+ (1,0) [0|0] "" Vector__XXX
 SG_ VCRIGHT_eFuseLockoutStatus : 18|2@1+ (1,0) [0|0] "" Vector__XXX
 SG_ VCRIGHT_swEnStatus : 20|1@1+ (1,0) [0|0] "" Vector__XXX
 SG_ VCRIGHT_vehiclePowerStateDBG : 21|2@1+ (1,0) [0|0] "" Vector__XXX
 SG_ VCRIGHT_parkLVState : 23|2@1+ (1,0) [0|0] "" Vector__XXX
 SG_ VCRIGHT_icrLVState : 25|2@1+ (1,0) [0|0] "" Vector__XXX
 SG_ VCRIGHT_interiorCameraLedLVState : 27|2@1+ (1,0) [0|0] "" Vector__XXX
 SG_ VCRIGHT_accDevicesDetected : 31|1@1+ (1,0) [0|0] "" Vector__XXX

BO_ 551 OCS1P_debugCushionMutCNT: 8 Vector__XXX
 SG_ OCS1P_cushionMutCNTFreq : 0|32@1+ (1,0) [0|0] "" Vector__XXX
 SG_ OCS1P_cushionMutCNTDuty : 32|16@1+ (1,0) [0|0] "" Vector__XXX
 SG_ OCS1P_cushionMutCNTFreqMed : 48|16@1+ (10,0) [0|0] "" Vector__XXX

BO_ 552 GTW_airbagCutoffStatus: 8 Vector__XXX
 SG_ GTW_airbagCutoffSwState : 0|2@1+ (1,0) [0|0] "" Vector__XXX
 SG_ GTW_warningIndicatorStatus : 2|2@1+ (1,0) [0|0] "" Vector__XXX
 SG_ GTW_airbagCutoffStatusCounter : 4|4@1+ (1,0) [0|0] "" Vector__XXX
 SG_ GTW_airbagCutoffStatusChecksum : 8|8@1+ (1,0) [0|0] "" Vector__XXX

BO_ 553 OCS1P_debugCushionSelfCNT: 8 Vector__XXX
 SG_ OCS1P_cushionSelfCNTFreq : 0|32@1+ (1,0) [0|0] "" Vector__XXX
 SG_ OCS1P_cushionSelfCNTDuty : 32|16@1+ (1,0) [0|0] "" Vector__XXX
 SG_ OCS1P_cushionSelfCNTFreqMed : 48|16@1+ (10,0) [0|0] "" Vector__XXX

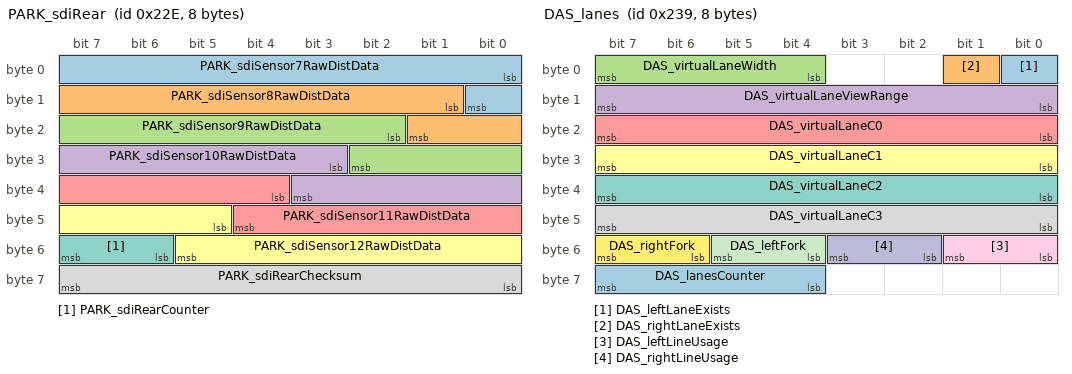
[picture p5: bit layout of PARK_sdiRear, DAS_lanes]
BO_ 558 PARK_sdiRear: 8 Vector__XXX
 SG_ PARK_sdiSensor7RawDistData : 0|9@1+ (1,0) [0|0] "" Vector__XXX
 SG_ PARK_sdiSensor8RawDistData : 9|9@1+ (1,0) [0|0] "" Vector__XXX
 SG_ PARK_sdiSensor9RawDistData : 18|9@1+ (1,0) [0|0] "" Vector__XXX
 SG_ PARK_sdiSensor10RawDistData : 27|9@1+ (1,0) [0|0] "" Vector__XXX
 SG_ PARK_sdiSensor11RawDistData : 36|9@1+ (1,0) [0|0] "" Vector__XXX
 SG_ PARK_sdiSensor12RawDistData : 45|9@1+ (1,0) [0|0] "" Vector__XXX
 SG_ PARK_sdiRearCounter : 54|2@1+ (1,0) [0|0] "" Vector__XXX
 SG_ PARK_sdiRearChecksum : 56|8@1+ (1,0) [0|0] "" Vector__XXX

BO_ 561 OCS1P_debugSeatbackSelfCNT: 8 Vector__XXX
 SG_ OCS1P_seatbackSelfCNTFreq : 0|32@1+ (1,0) [0|0] "" Vector__XXX
 SG_ OCS1P_seatbackSelfCNTDuty : 32|16@1+ (1,0) [0|0] "" Vector__XXX
 SG_ OCS1P_seatbackSelfCNTFreqMed : 48|16@1+ (10,0) [0|0] "" Vector__XXX

BO_ 564 OCS1P_debugCalibration: 8 Vector__XXX
 SG_ OCS1P_debugCalibrationIndex M : 0|2@1+ (1,0) [0|0] "" Vector__XXX
 SG_ OCS1P_cushionMutCalibEmptyFreq m1 : 8|16@1+ (1,0) [0|0] "" Vector__XXX
 SG_ OCS1P_cushionSelfCalibEmptyFreq m0 : 8|16@1+ (1,0) [0|0] "" Vector__XXX
 SG_ OCS1P_cushionSelfOffsetHCB m3 : 8|16@1- (0.005,0) [0|0] "" Vector__XXX
 SG_ OCS1P_temperatureCalib m2 : 8|16@1- (0.1,0) [0|0] "" Vector__XXX
 SG_ OCS1P_cushionMutCalibSmallFreq m1 : 24|16@1+ (1,0) [0|0] "" Vector__XXX
 SG_ OCS1P_humidityCalib m2 : 24|16@1+ (0.1,0) [0|0] "" Vector__XXX
 SG_ OCS1P_seatbackSelfCalibEmptyFreq m0 : 24|16@1+ (1,0) [0|0] "" Vector__XXX
 SG_ OCS1P_seatbackSelfOffsetHCB m3 : 24|16@1- (0.005,0) [0|0] "" Vector__XXX
 SG_ OCS1P_cushionMutCalibLargeFreq m1 : 40|16@1+ (1,0) [0|0] "" Vector__XXX

BO_ 565 OCS1P_debugTHS: 8 Vector__XXX
 SG_ OCS1P_temperature : 0|16@1- (0.1,0) [0|0] "" Vector__XXX
 SG_ OCS1P_humidity : 16|16@1+ (0.1,0) [0|0] "" Vector__XXX

BO_ 568 UI_driverAssistMapData: 8 Vector__XXX
 SG_ UI_mapSpeedLimitDependency : 0|3@1+ (1,0) [0|0] "" Vector__XXX
 SG_ UI_roadClass : 3|3@1+ (1,0) [0|0] "" Vector__XXX
 SG_ UI_inSuperchargerGeofence : 6|1@1+ (1,0) [0|0] "" Vector__XXX
 SG_ UI_mapSpeedUnits : 7|1@1+ (1,0) [0|0] "" Vector__XXX
 SG_ UI_mapSpeedLimit : 8|5@1+ (1,0) [0|0] "" Vector__XXX
 SG_ UI_mapSpeedLimitType : 13|3@1+ (1,0) [0|0] "" Vector__XXX
 SG_ UI_countryCode : 16|10@1+ (1,0) [0|0] "" Vector__XXX
 SG_ UI_streetCount : 26|2@1+ (1,0) [0|0] "" Vector__XXX
 SG_ UI_gpsRoadMatch : 28|1@1+ (1,0) [0|0] "" Vector__XXX
 SG_ UI_navRouteActive : 29|1@1+ (1,0) [0|0] "" Vector__XXX
 SG_ UI_parallelAutoparkEnabled : 30|1@1+ (1,0) [0|0] "" Vector__XXX
 SG_ UI_perpendicularAutoparkEnabled : 31|1@1+ (1,0) [0|0] "" Vector__XXX
 SG_ UI_nextBranchDist : 32|5@1+ (10,0) [0|0] "" Vector__XXX
 SG_ UI_controlledAccess : 37|1@1+ (1,0) [0|0] "" Vector__XXX
 SG_ UI_nextBranchLeftOffRamp : 38|1@1+ (1,0) [0|0] "" Vector__XXX
 SG_ UI_nextBranchRightOffRamp : 39|1@1+ (1,0) [0|0] "" Vector__XXX
 SG_ UI_rejectLeftLane : 40|1@1+ (1,0) [0|0] "" Vector__XXX
 SG_ UI_rejectRightLane : 41|1@1+ (1,0) [0|0] "" Vector__XXX
 SG_ UI_rejectHPP : 42|1@1+ (1,0) [0|0] "" Vector__XXX
 SG_ UI_rejectNav : 43|1@1+ (1,0) [0|0] "" Vector__XXX
 SG_ UI_rejectLeftFreeSpace : 44|1@1+ (1,0) [0|0] "" Vector__XXX
 SG_ UI_rejectRightFreeSpace : 45|1@1+ (1,0) [0|0] "" Vector__XXX
 SG_ UI_rejectAutosteer : 46|1@1+ (1,0) [0|0] "" Vector__XXX
 SG_ UI_rejectHandsOn : 47|1@1+ (1,0) [0|0] "" Vector__XXX
 SG_ UI_acceptBottsDots : 48|1@1+ (1,0) [0|0] "" Vector__XXX
 SG_ UI_autosteerRestricted : 49|1@1+ (1,0) [0|0] "" Vector__XXX
 SG_ UI_pmmEnabled : 50|1@1+ (1,0) [0|0] "" Vector__XXX
 SG_ UI_scaEnabled : 51|1@1+ (1,0) [0|0] "" Vector__XXX
 SG_ UI_mapDataCounter : 52|4@1+ (1,0) [0|0] "" Vector__XXX
 SG_ UI_mapDataChecksum : 56|8@1+ (1,0) [0|0] "" Vector__XXX

BO_ 569 DAS_lanes: 8 Vector__XXX
 SG_ DAS_leftLaneExists : 0|1@1+ (1,0) [0|0] "" Vector__XXX
 SG_ DAS_rightLaneExists : 1|1@1+ (1,0) [0|0] "" Vector__XXX
 SG_ DAS_virtualLaneWidth : 4|4@1+ (0.3125,2) [0|0] "" Vector__XXX
 SG_ DAS_virtualLaneViewRange : 8|8@1+ (1,0) [0|0] "" Vector__XXX
 SG_ DAS_virtualLaneC0 : 16|8@1+ (0.035,-3.5) [0|0] "" Vector__XXX
 SG_ DAS_virtualLaneC1 : 24|8@1+ (0.0016,-0.2) [0|0] "" Vector__XXX
 SG_ DAS_virtualLaneC2 : 32|8@1+ (2e-05,-0.0025) [0|0] "" Vector__XXX
 SG_ DAS_virtualLaneC3 : 40|8@1+ (2.4e-07,-3e-05) [0|0] "" Vector__XXX
 SG_ DAS_leftLineUsage : 48|2@1+ (1,0) [0|0] "" Vector__XXX
 SG_ DAS_rightLineUsage : 50|2@1+ (1,0) [0|0] "" Vector__XXX
 SG_ DAS_leftFork : 52|2@1+ (1,0) [0|0] "" Vector__XXX
 SG_ DAS_rightFork : 54|2@1+ (1,0) [0|0] "" Vector__XXX
 SG_ DAS_lanesCounter : 60|4@1+ (1,0) [0|0] "" Vector__XXX

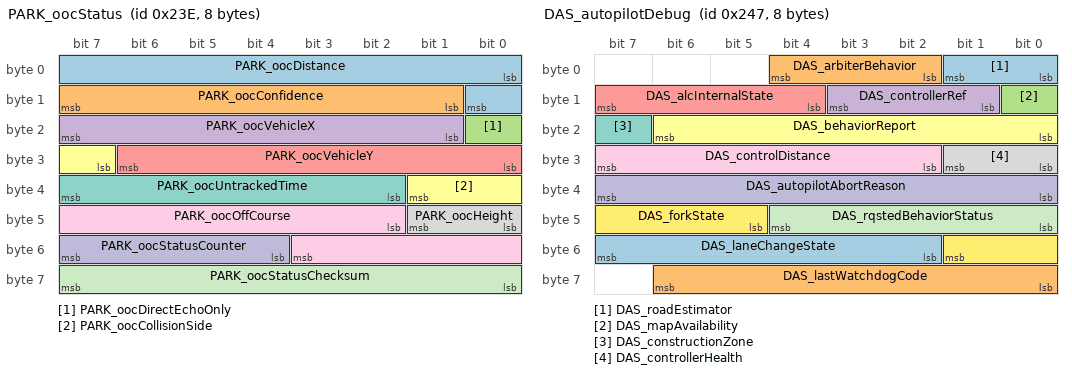
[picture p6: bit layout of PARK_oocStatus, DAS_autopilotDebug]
BO_ 574 PARK_oocStatus: 8 Vector__XXX
 SG_ PARK_oocDistance : 0|9@1+ (1,0) [0|0] "" Vector__XXX
 SG_ PARK_oocConfidence : 9|7@1+ (1,0) [0|0] "" Vector__XXX
 SG_ PARK_oocDirectEchoOnly : 16|1@1+ (1,0) [0|0] "" Vector__XXX
 SG_ PARK_oocVehicleX : 17|7@1+ (4,-114) [0|0] "" Vector__XXX
 SG_ PARK_oocVehicleY : 24|7@1+ (2,-128) [0|0] "" Vector__XXX
 SG_ PARK_oocCollisionSide : 31|3@1+ (1,0) [0|0] "" Vector__XXX
 SG_ PARK_oocUntrackedTime : 34|6@1+ (0.1,0) [0|0] "" Vector__XXX
 SG_ PARK_oocHeight : 40|2@1+ (1,0) [0|0] "" Vector__XXX
 SG_ PARK_oocOffCourse : 42|10@1+ (1,-512) [0|0] "" Vector__XXX
 SG_ PARK_oocStatusCounter : 52|4@1+ (1,0) [0|0] "" Vector__XXX
 SG_ PARK_oocStatusChecksum : 56|8@1+ (1,0) [0|0] "" Vector__XXX

BO_ 576 PM_state2: 8 Vector__XXX
 SG_ PM_state2Checksum : 0|8@1+ (1,0) [0|0] "" Vector__XXX
 SG_ PM_state2Counter : 8|4@1+ (1,0) [0|0] "" Vector__XXX
 SG_ PM_vdcCmdState : 12|1@1+ (1,0) [0|0] "" Vector__XXX
 SG_ PM_ebrCmdState : 13|1@1+ (1,0) [0|0] "" Vector__XXX
 SG_ PM_vehicleSpeedQF : 14|1@1+ (1,0) [0|0] "" Vector__XXX

BO_ 583 DAS_autopilotDebug: 8 Vector__XXX
 SG_ DAS_roadEstimator : 0|2@1+ (1,0) [0|0] "" Vector__XXX
 SG_ DAS_arbiterBehavior : 2|3@1+ (1,0) [0|0] "" Vector__XXX
 SG_ DAS_mapAvailability : 8|1@1+ (1,0) [0|0] "" Vector__XXX
 SG_ DAS_controllerRef : 9|3@1+ (1,0) [0|0] "" Vector__XXX
 SG_ DAS_alcInternalState : 12|4@1+ (1,0) [0|0] "" Vector__XXX
 SG_ DAS_behaviorReport : 16|7@1+ (1,0) [0|0] "" Vector__XXX
 SG_ DAS_constructionZone : 23|1@1+ (1,0) [0|0] "" Vector__XXX
 SG_ DAS_controllerHealth : 24|2@1+ (1,0) [0|0] "" Vector__XXX
 SG_ DAS_controlDistance : 26|6@1+ (2,0) [0|0] "" Vector__XXX
 SG_ DAS_autopilotAbortReason : 32|8@1+ (1,0) [0|0] "" Vector__XXX
 SG_ DAS_rqstedBehaviorStatus : 40|5@1+ (1,0) [0|0] "" Vector__XXX
 SG_ DAS_forkState : 45|5@1+ (1,0) [0|0] "" Vector__XXX
 SG_ DAS_laneChangeState : 50|6@1+ (1,0) [0|0] "" Vector__XXX
 SG_ DAS_lastWatchdogCode : 56|7@1+ (1,0) [0|0] "" Vector__XXX

BO_ 585 SCCM_leftStalk: 8 Vector__XXX
 SG_ SCCM_leftStalkCrc : 0|8@1+ (1,0) [0|0] "" Vector__XXX
 SG_ SCCM_leftStalkCounter : 8|4@1+ (1,0) [0|0] "" Vector__XXX
 SG_ SCCM_highBeamStalkStatus : 12|2@1+ (1,0) [0|0] "" Vector__XXX
 SG_ SCCM_washWipeButtonStatus : 14|2@1+ (1,0) [0|0] "" Vector__XXX
 SG_ SCCM_turnIndicatorStalkStatus : 16|4@1+ (1,0) [0|0] "" Vector__XXX
 SG_ SCCM_turnIndicatorStalkAngle : 20|12@1+ (0.1,-180) [0|0] "" Vector__XXX

BO_ 586 DAS_visualDebug: 8 Vector__XXX
 SG_ DAS_autosteerVehiclesUsage : 4|2@1+ (1,0) [0|0] "" Vector__XXX
 SG_ DAS_autosteerHPPUsage : 6|2@1+ (1,0) [0|0] "" Vector__XXX
 SG_ DAS_autosteerNavigationUsage : 8|2@1+ (1,0) [0|0] "" Vector__XXX
 SG_ DAS_autosteerModelUsage : 10|2@1+ (1,0) [0|0] "" Vector__XXX
 SG_ DAS_autosteerBottsDotsUsage : 12|2@1+ (1,0) [0|0] "" Vector__XXX
 SG_ DAS_offsetSide : 14|2@1+ (1,0) [0|0] "" Vector__XXX
 SG_ DAS_roadSurfaceType : 16|2@1+ (1,0) [0|0] "" Vector__XXX
 SG_ DAS_autosteerHealthAnomalyLevel : 18|3@1+ (1,0) [0|0] "" Vector__XXX
 SG_ DAS_autosteerHealthState : 21|3@1+ (1,0) [0|0] "" Vector__XXX
 SG_ DAS_lastLinePreferenceReason : 24|4@1+ (1,0) [0|0] "" Vector__XXX
 SG_ DAS_plannerState : 28|4@1+ (1,0) [0|0] "" Vector__XXX
 SG_ DAS_lastAutosteerAbortReason : 32|6@1+ (1,0) [0|0] "" Vector__XXX
 SG_ DAS_devAppInterfaceEnabled : 38|1@1+ (1,0) [0|0] "" Vector__XXX
 SG_ DAS_navAvailable : 39|1@1+ (1,0) [0|0] "" Vector__XXX
 SG_ DAS_navDistance : 40|8@1+ (100,0) [0|0] "" Vector__XXX
 SG_ DAS_accSmartSpeedActive : 48|1@1+ (1,0) [0|0] "" Vector__XXX
 SG_ DAS_accSmartSpeedState : 49|3@1+ (1,0) [0|0] "" Vector__XXX
 SG_ DAS_ulcInProgress : 52|1@1+ (1,0) [0|0] "" Vector__XXX
 SG_ DAS_trafficAwareSetSpeedInUse : 53|1@1+ (1,0) [0|0] "" Vector__XXX
 SG_ DAS_isaSystemState : 54|2@1+ (1,0) [0|0] "" Vector__XXX
 SG_ DAS_behaviorType : 56|2@1+ (1,0) [0|0] "" Vector__XXX
 SG_ DAS_ulcType : 58|2@1+ (1,0) [0|0] "" Vector__XXX
 SG_ DAS_rearVehDetectedThisCycle : 60|1@1+ (1,0) [0|0] "" Vector__XXX
 SG_ DAS_rearLeftVehDetectedCurrent : 61|1@1+ (1,0) [0|0] "" Vector__XXX
 SG_ DAS_rearRightVehDetectedTrip : 62|1@1+ (1,0) [0|0] "" Vector__XXX
 SG_ DAS_rearLeftVehDetectedTrip : 63|1@1+ (1,0) [0|0] "" Vector__XXX

BO_ 590 PARK_pscVehSlot: 8 Vector__XXX
 SG_ PARK_pscVehSlotType M : 0|2@1+ (1,0) [0|0] "" Vector__XXX
 SG_ PARK_pscLeftCrossVehX m1 : 5|11@1+ (2,-2048) [0|0] "" Vector__XXX
 SG_ PARK_pscLeftParallelVehX m0 : 5|11@1+ (2,-2048) [0|0] "" Vector__XXX
 SG_ PARK_pscRightCrossVehX m3 : 5|11@1+ (2,-2048) [0|0] "" Vector__XXX
 SG_ PARK_pscRightParallelVehX m2 : 5|11@1+ (2,-2048) [0|0] "" Vector__XXX
 SG_ PARK_pscLeftCrossVehY m1 : 16|11@1+ (2,-2048) [0|0] "" Vector__XXX
 SG_ PARK_pscLeftParallelVehY m0 : 16|11@1+ (2,-2048) [0|0] "" Vector__XXX
 SG_ PARK_pscRightCrossVehY m3 : 16|11@1+ (2,-2048) [0|0] "" Vector__XXX
 SG_ PARK_pscRightParallelVehY m2 : 16|11@1+ (2,-2048) [0|0] "" Vector__XXX
 SG_ PARK_pscLeftCrossPsi m1 : 32|13@1+ (0.0009765625,0) [0|0] "" Vector__XXX
 SG_ PARK_pscLeftParallelPsi m0 : 32|13@1+ (0.0009765625,0) [0|0] "" Vector__XXX
 SG_ PARK_pscRightCrossPsi m3 : 32|13@1+ (0.0009765625,0) [0|0] "" Vector__XXX
 SG_ PARK_pscRightParallelPsi m2 : 32|13@1+ (0.0009765625,0) [0|0] "" Vector__XXX
 SG_ PARK_pscLeftCrossSizeX m1 : 48|8@1+ (4,0) [0|0] "" Vector__XXX
 SG_ PARK_pscLeftParallelSizeX m0 : 48|8@1+ (4,0) [0|0] "" Vector__XXX
 SG_ PARK_pscRightCrossSizeX m3 : 48|8@1+ (4,0) [0|0] "" Vector__XXX
 SG_ PARK_pscRightParallelSizeX m2 : 48|8@1+ (4,0) [0|0] "" Vector__XXX
 SG_ PARK_pscLeftCrossSizeY m1 : 56|8@1+ (4,0) [0|0] "" Vector__XXX
 SG_ PARK_pscLeftParallelSizeY m0 : 56|8@1+ (4,0) [0|0] "" Vector__XXX
 SG_ PARK_pscRightCrossSizeY m3 : 56|8@1+ (4,0) [0|0] "" Vector__XXX
 SG_ PARK_pscRightParallelSizeY m2 : 56|8@1+ (4,0) [0|0] "" Vector__XXX

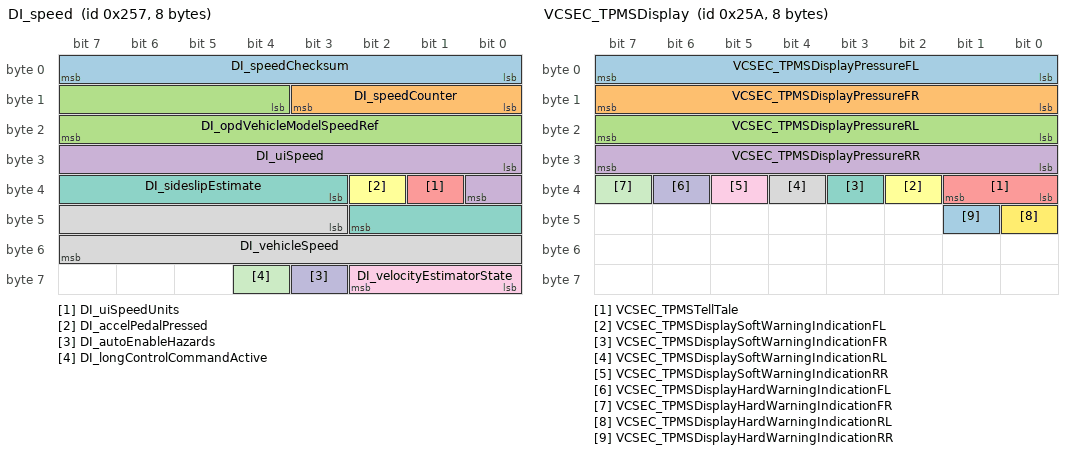
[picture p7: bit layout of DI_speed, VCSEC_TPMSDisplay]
BO_ 599 DI_speed: 8 Vector__XXX
 SG_ DI_speedChecksum : 0|8@1+ (1,0) [0|0] "" Vector__XXX
 SG_ DI_speedCounter : 8|4@1+ (1,0) [0|0] "" Vector__XXX
 SG_ DI_opdVehicleModelSpeedRef : 12|12@1+ (0.08,-40) [0|0] "" Vector__XXX
 SG_ DI_uiSpeed : 24|9@1+ (1,0) [0|0] "" Vector__XXX
 SG_ DI_uiSpeedUnits : 33|1@1+ (1,0) [0|0] "" Vector__XXX
 SG_ DI_accelPedalPressed : 34|1@1+ (1,0) [0|0] "" Vector__XXX
 SG_ DI_sideslipEstimate : 35|8@1- (0.0025,0) [0|0] "" Vector__XXX
 SG_ DI_vehicleSpeed : 43|13@1+ (0.08,-40) [0|0] "" Vector__XXX
 SG_ DI_velocityEstimatorState : 56|3@1+ (1,0) [0|0] "" Vector__XXX
 SG_ DI_autoEnableHazards : 59|1@1+ (1,0) [0|0] "" Vector__XXX
 SG_ DI_longControlCommandActive : 60|1@1+ (1,0) [0|0] "" Vector__XXX

BO_ 600 APB_status: 8 Vector__XXX
 SG_ APB_watchdogState : 0|3@1+ (1,0) [0|0] "" Vector__XXX
 SG_ APB_fusedState : 3|2@1+ (1,0) [0|0] "" Vector__XXX
 SG_ APB_cameraHeaterRequest : 5|1@1+ (1,0) [0|0] "" Vector__XXX
 SG_ APB_factorySummonStatus : 6|4@1+ (1,0) [0|0] "" Vector__XXX
 SG_ APB_clipRecordingStatus : 10|3@1+ (1,0) [0|0] "" Vector__XXX
 SG_ APB_summonUnavailableReason : 14|5@1+ (1,0) [0|0] "" Vector__XXX
 SG_ APB_fsdSuspendState : 19|2@1+ (1,0) [0|0] "" Vector__XXX
 SG_ APB_fsdRevokeStrikeoutCount : 21|3@1+ (1,0) [0|0] "" Vector__XXX
 SG_ APB_teslaVisionSupported : 24|2@1+ (1,0) [0|0] "" Vector__XXX
 SG_ APB_teslaVisionUnsupportedReason : 26|3@1+ (1,0) [0|0] "" Vector__XXX
 SG_ APB_fsdRevokeCount : 29|3@1+ (1,0) [0|0] "" Vector__XXX
 SG_ APB_excessiveAccelPedalWarning : 32|1@1+ (1,0) [0|0] "" Vector__XXX
 SG_ APB_unifiedObjectStackSupported : 33|2@1+ (1,0) [0|0] "" Vector__XXX
 SG_ APB_unifiedObjsUnsupportedReason : 35|3@1+ (1,0) [0|0] "" Vector__XXX
 SG_ APB_DDAWSystemStatus : 38|3@1+ (1,0) [0|0] "" Vector__XXX
 SG_ APB_socOperatingMode : 41|2@1+ (1,0) [0|0] "" Vector__XXX
 SG_ APB_summonVersionIdentifier : 43|1@1+ (1,0) [0|0] "" Vector__XXX
 SG_ APB_sentryState : 44|3@1+ (1,0) [0|0] "" Vector__XXX
 SG_ APB_autoparkVersionIdentifier : 47|2@1+ (1,0) [0|0] "" Vector__XXX
 SG_ APB_suspendResumeAvailable : 51|1@1+ (1,0) [0|0] "" Vector__XXX
 SG_ APB_statusCounter : 52|4@1+ (1,0) [0|0] "" Vector__XXX
 SG_ APB_statusChecksum : 56|8@1+ (1,0) [0|0] "" Vector__XXX

BO_ 601 APP_status: 8 Vector__XXX
 SG_ APP_watchdogState : 0|3@1+ (1,0) [0|0] "" Vector__XXX
 SG_ APP_fusedState : 3|2@1+ (1,0) [0|0] "" Vector__XXX
 SG_ APP_cameraHeaterRequest : 5|1@1+ (1,0) [0|0] "" Vector__XXX
 SG_ APP_factorySummonStatus : 6|4@1+ (1,0) [0|0] "" Vector__XXX
 SG_ APP_clipRecordingStatus : 10|3@1+ (1,0) [0|0] "" Vector__XXX
 SG_ APP_allowApActivationWithBrake : 13|1@1+ (1,0) [0|0] "" Vector__XXX
 SG_ APP_summonUnavailableReason : 14|5@1+ (1,0) [0|0] "" Vector__XXX
 SG_ APP_fsdSuspendState : 19|2@1+ (1,0) [0|0] "" Vector__XXX
 SG_ APP_fsdRevokeStrikeoutCount : 21|3@1+ (1,0) [0|0] "" Vector__XXX
 SG_ APP_teslaVisionSupported : 24|2@1+ (1,0) [0|0] "" Vector__XXX
 SG_ APP_teslaVisionUnsupportedReason : 26|3@1+ (1,0) [0|0] "" Vector__XXX
 SG_ APP_fsdRevokeCount : 29|3@1+ (1,0) [0|0] "" Vector__XXX
 SG_ APP_excessiveAccelPedalWarning : 32|1@1+ (1,0) [0|0] "" Vector__XXX
 SG_ APP_unifiedObjectStackSupported : 33|2@1+ (1,0) [0|0] "" Vector__XXX
 SG_ APP_unifiedObjsUnsupportedReason : 35|3@1+ (1,0) [0|0] "" Vector__XXX
 SG_ APP_DDAWSystemStatus : 38|3@1+ (1,0) [0|0] "" Vector__XXX
 SG_ APP_socOperatingMode : 41|2@1+ (1,0) [0|0] "" Vector__XXX
 SG_ APP_summonVersionIdentifier : 43|1@1+ (1,0) [0|0] "" Vector__XXX
 SG_ APP_sentryState : 44|3@1+ (1,0) [0|0] "" Vector__XXX
 SG_ APP_autoparkVersionIdentifier : 47|2@1+ (1,0) [0|0] "" Vector__XXX
 SG_ APP_setSpeedMode : 49|2@1+ (1,0) [0|0] "" Vector__XXX
 SG_ APP_suspendResumeAvailable : 51|1@1+ (1,0) [0|0] "" Vector__XXX
 SG_ APP_statusCounter : 52|4@1+ (1,0) [0|0] "" Vector__XXX
 SG_ APP_statusChecksum : 56|8@1+ (1,0) [0|0] "" Vector__XXX

BO_ 602 VCSEC_TPMSDisplay: 8 Vector__XXX
 SG_ VCSEC_TPMSDisplayPressureFL : 0|8@1+ (0.025,0) [0|0] "" Vector__XXX
 SG_ VCSEC_TPMSDisplayPressureFR : 8|8@1+ (0.025,0) [0|0] "" Vector__XXX
 SG_ VCSEC_TPMSDisplayPressureRL : 16|8@1+ (0.025,0) [0|0] "" Vector__XXX
 SG_ VCSEC_TPMSDisplayPressureRR : 24|8@1+ (0.025,0) [0|0] "" Vector__XXX
 SG_ VCSEC_TPMSTellTale : 32|2@1+ (1,0) [0|0] "" Vector__XXX
 SG_ VCSEC_TPMSDisplaySoftWarningIndicationFL : 34|1@1+ (1,0) [0|0] "" Vector__XXX
 SG_ VCSEC_TPMSDisplaySoftWarningIndicationFR : 35|1@1+ (1,0) [0|0] "" Vector__XXX
 SG_ VCSEC_TPMSDisplaySoftWarningIndicationRL : 36|1@1+ (1,0) [0|0] "" Vector__XXX
 SG_ VCSEC_TPMSDisplaySoftWarningIndicationRR : 37|1@1+ (1,0) [0|0] "" Vector__XXX
 SG_ VCSEC_TPMSDisplayHardWarningIndicationFL : 38|1@1+ (1,0) [0|0] "" Vector__XXX
 SG_ VCSEC_TPMSDisplayHardWarningIndicationFR : 39|1@1+ (1,0) [0|0] "" Vector__XXX
 SG_ VCSEC_TPMSDisplayHardWarningIndicationRL : 40|1@1+ (1,0) [0|0] "" Vector__XXX
 SG_ VCSEC_TPMSDisplayHardWarningIndicationRR : 41|1@1+ (1,0) [0|0] "" Vector__XXX

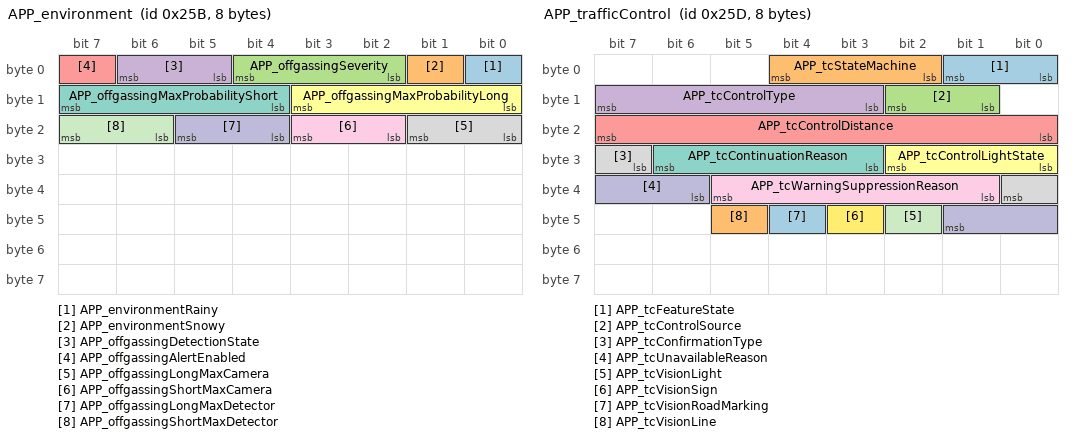
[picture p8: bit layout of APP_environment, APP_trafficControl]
BO_ 603 APP_environment: 8 Vector__XXX
 SG_ APP_environmentRainy : 0|1@1+ (1,0) [0|0] "" Vector__XXX
 SG_ APP_environmentSnowy : 1|1@1+ (1,0) [0|0] "" Vector__XXX
 SG_ APP_offgassingSeverity : 2|3@1+ (1,0) [0|0] "" Vector__XXX
 SG_ APP_offgassingDetectionState : 5|2@1+ (1,0) [0|0] "" Vector__XXX
 SG_ APP_offgassingAlertEnabled : 7|1@1+ (1,0) [0|0] "" Vector__XXX
 SG_ APP_offgassingMaxProbabilityLong : 8|4@1+ (1,0) [0|0] "" Vector__XXX
 SG_ APP_offgassingMaxProbabilityShort : 12|4@1+ (1,0) [0|0] "" Vector__XXX
 SG_ APP_offgassingLongMaxCamera : 16|2@1+ (1,0) [0|0] "" Vector__XXX
 SG_ APP_offgassingShortMaxCamera : 18|2@1+ (1,0) [0|0] "" Vector__XXX
 SG_ APP_offgassingLongMaxDetector : 20|2@1+ (1,0) [0|0] "" Vector__XXX
 SG_ APP_offgassingShortMaxDetector : 22|2@1+ (1,0) [0|0] "" Vector__XXX

BO_ 605 APP_trafficControl: 8 Vector__XXX
 SG_ APP_tcFeatureState : 0|2@1+ (1,0) [0|0] "" Vector__XXX
 SG_ APP_tcStateMachine : 2|3@1+ (1,0) [0|0] "" Vector__XXX
 SG_ APP_tcControlSource : 9|2@1+ (1,0) [0|0] "" Vector__XXX
 SG_ APP_tcControlType : 11|5@1+ (1,0) [0|0] "" Vector__XXX
 SG_ APP_tcControlDistance : 16|8@1+ (1,0) [0|0] "" Vector__XXX
 SG_ APP_tcControlLightState : 24|3@1+ (1,0) [0|0] "" Vector__XXX
 SG_ APP_tcContinuationReason : 27|4@1+ (1,0) [0|0] "" Vector__XXX
 SG_ APP_tcConfirmationType : 31|2@1+ (1,0) [0|0] "" Vector__XXX
 SG_ APP_tcWarningSuppressionReason : 33|5@1+ (1,0) [0|0] "" Vector__XXX
 SG_ APP_tcUnavailableReason : 38|4@1+ (1,0) [0|0] "" Vector__XXX
 SG_ APP_tcVisionLight : 42|1@1+ (1,0) [0|0] "" Vector__XXX
 SG_ APP_tcVisionSign : 43|1@1+ (1,0) [0|0] "" Vector__XXX
 SG_ APP_tcVisionRoadMarking : 44|1@1+ (1,0) [0|0] "" Vector__XXX
 SG_ APP_tcVisionLine : 45|1@1+ (1,0) [0|0] "" Vector__XXX

BO_ 606 PARK_pscEnvSlot: 8 Vector__XXX
 SG_ PARK_pscEnvSlotType M : 0|2@1+ (1,0) [0|0] "" Vector__XXX
 SG_ PARK_pscLeftCrossObj1X m1 : 3|11@1+ (2,-2048) [0|0] "" Vector__XXX
 SG_ PARK_pscLeftParallelObj1X m0 : 3|11@1+ (2,-2048) [0|0] "" Vector__XXX
 SG_ PARK_pscRightCrossObj1X m3 : 3|11@1+ (2,-2048) [0|0] "" Vector__XXX
 SG_ PARK_pscRightParallelObj1X m2 : 3|11@1+ (2,-2048) [0|0] "" Vector__XXX
 SG_ PARK_pscLeftCrossObj1Y m1 : 14|11@1+ (2,-2048) [0|0] "" Vector__XXX
 SG_ PARK_pscLeftParallelObj1Y m0 : 14|11@1+ (2,-2048) [0|0] "" Vector__XXX
 SG_ PARK_pscRightCrossObj1Y m3 : 14|11@1+ (2,-2048) [0|0] "" Vector__XXX
 SG_ PARK_pscRightParallelObj1Y m2 : 14|11@1+ (2,-2048) [0|0] "" Vector__XXX
 SG_ PARK_pscLeftCrossObj1Alpha m1 : 25|7@1+ (2,-128) [0|0] "" Vector__XXX
 SG_ PARK_pscLeftParallelObj1Alpha m0 : 25|7@1+ (2,-128) [0|0] "" Vector__XXX
 SG_ PARK_pscRightCrossObj1Alpha m3 : 25|7@1+ (2,-128) [0|0] "" Vector__XXX
 SG_ PARK_pscRightParallelObj1Alpha m2 : 25|7@1+ (2,-128) [0|0] "" Vector__XXX
 SG_ PARK_pscLeftCrossObj2Y m1 : 35|11@1+ (2,-2048) [0|0] "" Vector__XXX
 SG_ PARK_pscLeftParallelObj2Y m0 : 35|11@1+ (2,-2048) [0|0] "" Vector__XXX
 SG_ PARK_pscRightCrossObj2Y m3 : 35|11@1+ (2,-2048) [0|0] "" Vector__XXX
 SG_ PARK_pscRightParallelObj2Y m2 : 35|11@1+ (2,-2048) [0|0] "" Vector__XXX
 SG_ PARK_pscLeftCrossObj2X m1 : 46|11@1+ (2,-2048) [0|0] "" Vector__XXX
 SG_ PARK_pscLeftParallelObj2X m0 : 46|11@1+ (2,-2048) [0|0] "" Vector__XXX
 SG_ PARK_pscRightCrossObj2X m3 : 46|11@1+ (2,-2048) [0|0] "" Vector__XXX
 SG_ PARK_pscRightParallelObj2X m2 : 46|11@1+ (2,-2048) [0|0] "" Vector__XXX
 SG_ PARK_pscLeftCrossObj2Alpha m1 : 57|7@1+ (2,-128) [0|0] "" Vector__XXX
 SG_ PARK_pscLeftParallelObj2Alpha m0 : 57|7@1+ (2,-128) [0|0] "" Vector__XXX
 SG_ PARK_pscRightCrossObj2Alpha m3 : 57|7@1+ (2,-128) [0|0] "" Vector__XXX
 SG_ PARK_pscRightParallelObj2Alpha m2 : 57|7@1+ (2,-128) [0|0] "" Vector__XXX

BO_ 609 VCFRONT_12VBatteryStatus: 8 Vector__XXX
 SG_ VCFRONT_12VBatteryStatusIndex M : 0|3@1+ (1,0) [0|0] "" Vector__XXX
 SG_ VCFRONT_12VBatteryTargetVoltage m2 : 3|13@1+ (0.01,0) [0|0] "" Vector__XXX
 SG_ VCFRONT_IBSFault m0 : 3|1@1+ (1,0) [0|0] "" Vector__XXX
 SG_ VCFRONT_IBSVoltageFiltered m3 : 3|14@1+ (0.005443676098,0) [0|0] "" Vector__XXX
 SG_ VCFRONT_batterySupportRequest m1 : 3|1@1+ (1,0) [0|0] "" Vector__XXX
 SG_ VCFRONT_targetCurrent m5 : 3|11@1+ (0.125,-127) [0|0] "" Vector__XXX
 SG_ VCFRONT_voltageProfile m4 : 3|2@1+ (1,0) [0|0] "" Vector__XXX
 SG_ VCFRONT_12VOverchargeCounter m0 : 4|4@1+ (1,0) [0|0] "" Vector__XXX
 SG_ VCFRONT_batterySMState m1 : 4|4@1+ (1,0) [0|0] "" Vector__XXX
 SG_ VCFRONT_IBSAmpHours m4 : 5|14@1- (0.005,0) [0|0] "" Vector__XXX
 SG_ VCFRONT_eFuseRecoveryStateDBG m1 : 8|3@1+ (1,0) [0|0] "" Vector__XXX
 SG_ VCFRONT_voltageDropCounter m0 : 8|4@1+ (1,0) [0|0] "" Vector__XXX
 SG_ VCFRONT_batteryLINScheduleDBG m1 : 11|3@1+ (1,0) [0|0] "" Vector__XXX
 SG_ VCFRONT_isVehicleSupported m0 : 12|1@1+ (1,0) [0|0] "" Vector__XXX
 SG_ VCFRONT_shortedCellFaultCounter m0 : 13|3@1+ (1,0) [0|0] "" Vector__XXX
 SG_ VCFRONT_PCSMia m5 : 14|1@1+ (1,0) [0|0] "" Vector__XXX
 SG_ VCFRONT_resistanceEstimationTestCounter m1 : 14|2@1+ (1,0) [0|0] "" Vector__XXX
 SG_ VCFRONT_chargeNeeded m5 : 15|1@1+ (1,0) [0|0] "" Vector__XXX
 SG_ VCFRONT_IBSCurrent m1 : 16|16@1- (0.005,0) [0|0] "" Vector__XXX
 SG_ VCFRONT_IBSCurrentFiltered m0 : 16|16@1- (0.005,0) [0|0] "" Vector__XXX
 SG_ VCFRONT_IBSTemperature m2 : 16|11@1+ (0.1,-24) [0|0] "" Vector__XXX
 SG_ VCFRONT_voltageControlLoopIntegrationVal m5 : 16|14@1+ (0.006,0) [0|0] "" Vector__XXX
 SG_ VCFRONT_LVBMS_LVBusVoltageSourceDBG m3 : 17|2@1+ (1,0) [0|0] "" Vector__XXX
 SG_ VCFRONT_IBSVoltageRawDBG m4 : 19|14@1+ (0.005443676098,0) [0|0] "" Vector__XXX
 SG_ VCFRONT_LVBMS_LVPackCurrentSourceDBG m3 : 19|2@1+ (1,0) [0|0] "" Vector__XXX
 SG_ VCFRONT_LVBatterySupportRqrdTrigger m3 : 24|14@1+ (1,0) [0|0] "" Vector__XXX
 SG_ VCFRONT_currentSensorMismatchLeakyBktPctDBG m2 : 27|7@1+ (2,0) [0|0] "" Vector__XXX
 SG_ VCFRONT_currentControlLoopIntegrationVal m5 : 30|14@1+ (0.006,0) [0|0] "" Vector__XXX
 SG_ VCFRONT_IBSVoltage m1 : 32|14@1+ (0.005443676098,0) [0|0] "" Vector__XXX
 SG_ VCFRONT_silentWakeIBSCurrent m0 : 32|12@1+ (0.125,-511.875) [0|0] "" Vector__XXX
 SG_ VCFRONT_LVBatteryLINCommsDetectedDBG m4 : 33|1@1+ (1,0) [0|0] "" Vector__XXX
 SG_ VCFRONT_voltageSensorMismatchLeakyBktPctDBG m4 : 34|7@1+ (2,0) [0|0] "" Vector__XXX
 SG_ VCFRONT_LVBatteryEnergyRemainingPCT m2 : 37|7@1+ (1,0) [0|0] "" Vector__XXX
 SG_ VCFRONT_goodForPCSPowerCycleLeakyBktDBG m3 : 40|5@1+ (0.0005,0) [0|0] "" Vector__XXX
 SG_ VCFRONT_LVBusControlMode m4 : 41|4@1+ (1,0) [0|0] "" Vector__XXX
 SG_ VCFRONT_LVBatteryStatusForDrive m2 : 44|2@1+ (1,0) [0|0] "" Vector__XXX
 SG_ VCFRONT_firstChargeOTA m0 : 44|1@1+ (1,0) [0|0] "" Vector__XXX
 SG_ VCFRONT_LVBusControlsFutile m3 : 45|1@1+ (1,0) [0|0] "" Vector__XXX
 SG_ VCFRONT_firstChargePOR m0 : 45|1@1+ (1,0) [0|0] "" Vector__XXX
 SG_ VCFRONT_good12VforUpdate : 46|1@1+ (1,0) [0|0] "" Vector__XXX
 SG_ VCFRONT_LVLoadRequest : 47|1@1+ (1,0) [0|0] "" Vector__XXX
 SG_ VCFRONT_LVBatteryType m2 : 48|3@1+ (1,0) [0|0] "" Vector__XXX
 SG_ VCFRONT_resistanceEstimationTestValid m3 : 48|1@1+ (1,0) [0|0] "" Vector__XXX
 SG_ VCFRONT_reverseBatteryFault m1 : 48|1@1+ (1,0) [0|0] "" Vector__XXX
 SG_ VCFRONT_voltageFloorReachedCounter m0 : 48|4@1+ (1,0) [0|0] "" Vector__XXX
 SG_ VCFRONT_LVBatterySupported m1 : 49|1@1+ (1,0) [0|0] "" Vector__XXX
 SG_ VCFRONT_resistanceEstimationTestsExpended m3 : 49|1@1+ (1,0) [0|0] "" Vector__XXX
 SG_ VCFRONT_LVBatteryCannotSupportVehicle m1 : 50|1@1+ (1,0) [0|0] "" Vector__XXX
 SG_ VCFRONT_LVBatteryFctryLimOverrideOk m4 : 50|1@1+ (1,0) [0|0] "" Vector__XXX
 SG_ VCFRONT_goodLVChargeForUpdate m3 : 50|1@1+ (1,0) [0|0] "" Vector__XXX
 SG_ VCFRONT_LVBatterySPICommsDetectedDBG m4 : 51|1@1+ (1,0) [0|0] "" Vector__XXX
 SG_ VCFRONT_goodTemp12VforUpdate m1 : 51|1@1+ (1,0) [0|0] "" Vector__XXX
 SG_ VCFRONT_opportunisticDCRTestNeeded m3 : 51|1@1+ (1,0) [0|0] "" Vector__XXX
 SG_ VCFRONT_resistanceEstimationNeeded m2 : 51|1@1+ (1,0) [0|0] "" Vector__XXX
 SG_ VCFRONT_12VBatteryStatusCounter : 52|4@1+ (1,0) [0|0] "" Vector__XXX
 SG_ VCFRONT_12VBatteryStatusChecksum : 56|8@1+ (1,0) [0|0] "" Vector__XXX

BO_ 622 PARK_oloDict: 8 Vector__XXX
 SG_ PARK_objectIdx : 0|4@1+ (1,0) [0|0] "" Vector__XXX
 SG_ PARK_obj_type : 4|3@1+ (1,0) [0|0] "" Vector__XXX
 SG_ PARK_obj_pt1_x : 16|12@1+ (1,0) [0|0] "" Vector__XXX
 SG_ PARK_obj_pt1_y : 28|12@1+ (1,0) [0|0] "" Vector__XXX
 SG_ PARK_obj_pt2_x : 40|12@1+ (1,0) [0|0] "" Vector__XXX
 SG_ PARK_obj_pt2_y : 52|12@1+ (1,0) [0|0] "" Vector__XXX

BO_ 632 UI_roadCurvature: 8 Vector__XXX
 SG_ UI_roadCurvC0 : 0|11@1- (0.02,0) [0|0] "" Vector__XXX
 SG_ UI_roadCurvC1 : 11|10@1- (0.00075,0) [0|0] "" Vector__XXX
 SG_ UI_roadCurvC2 : 21|14@1- (7.5e-06,0) [0|0] "" Vector__XXX
 SG_ UI_roadCurvC3 : 35|13@1- (3e-08,0) [0|0] "" Vector__XXX
 SG_ UI_roadCurvRange : 48|6@1+ (4,0) [0|0] "" Vector__XXX
 SG_ UI_roadCurvHealth : 54|2@1+ (1,0) [0|0] "" Vector__XXX
 SG_ UI_roadCurvChecksum : 56|8@1+ (1,0) [0|0] "" Vector__XXX

BO_ 637 APS_eacMonitor: 8 Vector__XXX
 SG_ APS_eacAllow : 0|2@1+ (1,0) [0|0] "" Vector__XXX
 SG_ APS_eacMonitorCounter : 8|4@1+ (1,0) [0|0] "" Vector__XXX
 SG_ APS_eacMonitorChecksum : 16|8@1+ (1,0) [0|0] "" Vector__XXX

BO_ 644 UI_vehicleModes: 8 Vector__XXX
 SG_ UI_factoryMode : 0|1@1+ (1,0) [0|0] "" Vector__XXX
 SG_ UI_transportMode : 1|1@1+ (1,0) [0|0] "" Vector__XXX
 SG_ UI_showroomMode : 2|1@1+ (1,0) [0|0] "" Vector__XXX
 SG_ UI_serviceMode : 3|1@1+ (1,0) [0|0] "" Vector__XXX
 SG_ UI_isDelivered : 4|1@1+ (1,0) [0|0] "" Vector__XXX
 SG_ UI_hasEverBeenDelivered : 5|1@1+ (1,0) [0|0] "" Vector__XXX
 SG_ UI_homelinkV2Command0 : 8|8@1+ (1,0) [0|0] "" Vector__XXX
 SG_ UI_homelinkV2Command1 : 16|8@1+ (1,0) [0|0] "" Vector__XXX
 SG_ UI_homelinkV2Command2 : 24|8@1+ (1,0) [0|0] "" Vector__XXX
 SG_ UI_carWashMode : 32|1@1+ (1,0) [0|0] "" Vector__XXX
 SG_ UI_valetMode : 33|1@1+ (1,0) [0|0] "" Vector__XXX
 SG_ UI_gameMode : 34|1@1+ (1,0) [0|0] "" Vector__XXX
 SG_ UI_diagnosticsAllowed : 35|1@1+ (1,0) [0|0] "" Vector__XXX
 SG_ UI_serviceModePlus : 36|1@1+ (1,0) [0|0] "" Vector__XXX
 SG_ UI_premiumAmpPowerOff : 37|1@1+ (1,0) [0|0] "" Vector__XXX
 SG_ UI_signedCmdHardLocked : 38|1@1+ (1,0) [0|0] "" Vector__XXX
 SG_ UI_signedCmdServiceMode : 39|1@1+ (1,0) [0|0] "" Vector__XXX
 SG_ UI_closureEasterEggStatus : 40|2@1+ (1,0) [0|0] "" Vector__XXX
 SG_ UI_lightShowType : 42|3@1+ (1,0) [0|0] "" Vector__XXX
 SG_ UI_sohTestRequest : 45|1@1+ (1,0) [0|0] "" Vector__XXX
 SG_ UI_vehicleModesCounter : 52|4@1+ (1,0) [0|0] "" Vector__XXX
 SG_ UI_vehicleModesChecksum : 56|8@1+ (1,0) [0|0] "" Vector__XXX

BO_ 659 UI_chassisControl: 8 Vector__XXX
 SG_ UI_steeringTuneRequest : 0|2@1+ (1,0) [0|0] "" Vector__XXX
 SG_ UI_tractionControlMode : 2|3@1+ (1,0) [0|0] "" Vector__XXX
 SG_ UI_parkBrakeRequest : 5|2@1+ (1,0) [0|0] "" Vector__XXX
 SG_ UI_narrowGarages : 7|1@1+ (1,0) [0|0] "" Vector__XXX
 SG_ UI_winchModeRequest : 8|2@1+ (1,0) [0|0] "" Vector__XXX
 SG_ UI_zeroSpeedConfirmed : 10|2@1+ (1,0) [0|0] "" Vector__XXX
 SG_ UI_trailerMode : 12|1@1+ (1,0) [0|0] "" Vector__XXX
 SG_ UI_distanceUnits : 13|1@1+ (1,0) [0|0] "" Vector__XXX
 SG_ UI_dasDebugEnable : 14|1@1+ (1,0) [0|0] "" Vector__XXX
 SG_ UI_accOvertakeEnable : 16|2@1+ (1,0) [0|0] "" Vector__XXX
 SG_ UI_aebEnable : 18|2@1+ (1,0) [0|0] "" Vector__XXX
 SG_ UI_aesEnable : 20|2@1+ (1,0) [0|0] "" Vector__XXX
 SG_ UI_ahlbEnable : 22|2@1+ (1,0) [0|0] "" Vector__XXX
 SG_ UI_autoLaneChangeEnable : 24|2@1+ (1,0) [0|0] "" Vector__XXX
 SG_ UI_winchProxUserOverride : 26|1@1+ (1,0) [0|0] "" Vector__XXX
 SG_ UI_rebootAutopilot : 27|1@1+ (1,0) [0|0] "" Vector__XXX
 SG_ UI_autoParkRequest : 28|4@1+ (1,0) [0|0] "" Vector__XXX
 SG_ UI_bsdEnable : 32|2@1+ (1,0) [0|0] "" Vector__XXX
 SG_ UI_fcwEnable : 34|2@1+ (1,0) [0|0] "" Vector__XXX
 SG_ UI_fcwSensitivity : 36|2@1+ (1,0) [0|0] "" Vector__XXX
 SG_ UI_latControlEnable : 38|2@1+ (1,0) [0|0] "" Vector__XXX
 SG_ UI_ldwEnable : 40|2@1+ (1,0) [0|0] "" Vector__XXX
 SG_ UI_pedalSafetyEnable : 42|2@1+ (1,0) [0|0] "" Vector__XXX
 SG_ UI_pedalMap_epas : 44|2@1+ (1,0) [0|0] "" Vector__XXX
 SG_ UI_redLightStopSignEnable : 46|2@1+ (1,0) [0|0] "" Vector__XXX
 SG_ UI_selfParkTune : 48|4@1+ (1,0) [0|0] "" Vector__XXX
 SG_ UI_chassisControlCounter : 52|4@1+ (1,0) [0|0] "" Vector__XXX
 SG_ UI_chassisControlChecksum : 56|8@1+ (1,0) [0|0] "" Vector__XXX

BO_ 664 UI_csaOfframpCurvature: 8 Vector__XXX
 SG_ UI_csaOfframpCurvC2 : 0|16@1- (1e-06,0) [0|0] "" Vector__XXX
 SG_ UI_csaOfframpCurvC3 : 16|16@1- (4e-09,0) [0|0] "" Vector__XXX
 SG_ UI_csaOfframpCurvRange : 32|8@1+ (2,0) [0|0] "" Vector__XXX
 SG_ UI_csaOfframpCurvCounter : 40|8@1+ (1,0) [0|0] "" Vector__XXX
 SG_ UI_csaOfframpCurvUsingTspline : 48|1@1+ (1,0) [0|0] "" Vector__XXX
 SG_ UI_csaOfframpCurvReserved : 49|7@1+ (1,0) [0|0] "" Vector__XXX
 SG_ UI_csaOfframpCurvChecksum : 56|8@1+ (1,0) [0|0] "" Vector__XXX

BO_ 679 UI_csaRoadCurvature: 8 Vector__XXX
 SG_ UI_csaRoadCurvC2 : 0|16@1- (1e-06,0) [0|0] "" Vector__XXX
 SG_ UI_csaRoadCurvC3 : 16|16@1- (4e-09,0) [0|0] "" Vector__XXX
 SG_ UI_csaRoadCurvRange : 32|8@1+ (2,0) [0|0] "" Vector__XXX
 SG_ UI_csaRoadCurvCounter : 40|8@1+ (1,0) [0|0] "" Vector__XXX
 SG_ UI_csaRoadCurvUsingTspline : 48|1@1+ (1,0) [0|0] "" Vector__XXX
 SG_ UI_csaRoadCurvReserved : 49|7@1+ (1,0) [0|0] "" Vector__XXX
 SG_ UI_csaRoadCurvChecksum : 56|8@1+ (1,0) [0|0] "" Vector__XXX

BO_ 680 EPBL_status: 8 Vector__XXX
 SG_ EPBL_systemStatus : 0|4@1+ (1,0) [0|0] "" Vector__XXX
 SG_ EPBL_freeRollModeStatus : 4|2@1+ (1,0) [0|0] "" Vector__XXX
 SG_ EPBL_driverIsLeaving : 6|1@1+ (1,0) [0|0] "" Vector__XXX
 SG_ EPBL_driverIsLeavingAnySpeed : 7|1@1+ (1,0) [0|0] "" Vector__XXX
 SG_ EPBL_systemCdpAvailable : 8|1@1+ (1,0) [0|0] "" Vector__XXX
 SG_ EPBL_chimeRequest : 9|3@1+ (1,0) [0|0] "" Vector__XXX
 SG_ EPBL_telltale : 12|3@1+ (1,0) [0|0] "" Vector__XXX
 SG_ EPBL_contactorCycleNotNeededForWinchEntry : 15|1@1+ (1,0) [0|0] "" Vector__XXX
 SG_ EPBL_redundantBrakingEnabled : 16|1@1+ (1,0) [0|0] "" Vector__XXX
 SG_ EPBL_summonEnabled : 17|1@1+ (1,0) [0|0] "" Vector__XXX
 SG_ EPBL_brakeLight : 18|1@1+ (1,0) [0|0] "" Vector__XXX
 SG_ EPBL_epbConfigMismatch : 19|1@1+ (1,0) [0|0] "" Vector__XXX
 SG_ EPBL_brakeConfirmedPressed : 20|1@1+ (1,0) [0|0] "" Vector__XXX
 SG_ EPBL_requestUserConfirmation : 21|1@1+ (1,0) [0|0] "" Vector__XXX
 SG_ EPBL_uiWinchModeMiscBlocking : 22|1@1+ (1,0) [0|0] "" Vector__XXX
 SG_ EPBL_winchModeActive : 23|1@1+ (1,0) [0|0] "" Vector__XXX
 SG_ EPBL_updateMode : 24|1@1+ (1,0) [0|0] "" Vector__XXX
 SG_ EPBL_winchModePermissive : 25|1@1+ (1,0) [0|0] "" Vector__XXX
 SG_ EPBL_winchModePending : 26|1@1+ (1,0) [0|0] "" Vector__XXX
 SG_ EPBL_cdpRequest : 27|1@1+ (1,0) [0|0] "" Vector__XXX
 SG_ EPBL_uiParkAvailable : 28|2@1+ (1,0) [0|0] "" Vector__XXX
 SG_ EPBL_brakeDiscWipeRequest : 30|2@1+ (1,0) [0|0] "" Vector__XXX
 SG_ EPBL_showUiGearShifter : 32|1@1+ (1,0) [0|0] "" Vector__XXX
 SG_ EPBL_uiWinchModeLvStatus : 33|2@1+ (1,0) [0|0] "" Vector__XXX
 SG_ EPBL_showStalkFaultedOnUi : 45|1@1+ (1,0) [0|0] "" Vector__XXX
 SG_ EPBL_espPowerRequest : 46|1@1+ (1,0) [0|0] "" Vector__XXX
 SG_ EPBL_okToPark : 47|1@1+ (1,0) [0|0] "" Vector__XXX
 SG_ EPBL_hornRequest : 48|1@1+ (1,0) [0|0] "" Vector__XXX
 SG_ EPBL_winchModeAvailable : 49|1@1+ (1,0) [0|0] "" Vector__XXX
 SG_ EPBL_bothDisconnected : 50|1@1+ (1,0) [0|0] "" Vector__XXX
 SG_ EPBL_blockDrive : 51|1@1+ (1,0) [0|0] "" Vector__XXX
 SG_ EPBL_statusCounter : 52|4@1+ (1,0) [0|0] "" Vector__XXX
 SG_ EPBL_statusChecksum : 56|8@1+ (1,0) [0|0] "" Vector__XXX

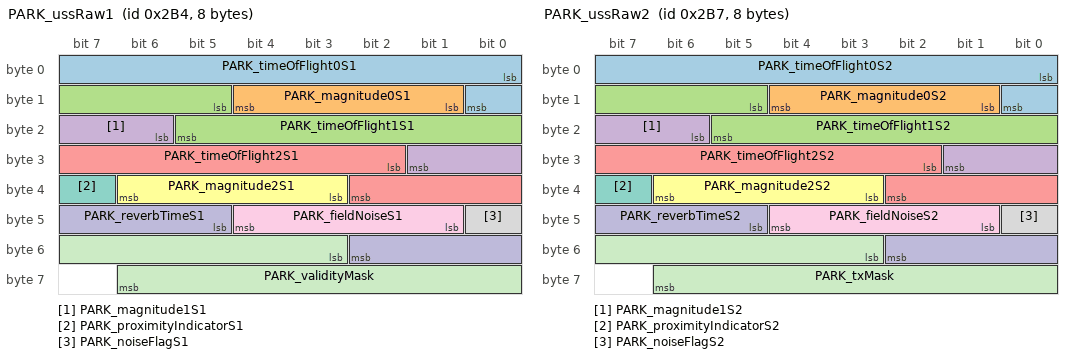
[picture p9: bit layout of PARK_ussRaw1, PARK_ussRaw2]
BO_ 692 PARK_ussRaw1: 8 Vector__XXX
 SG_ PARK_timeOfFlight0S1 : 0|9@1+ (0.0512,0) [0|0] "" Vector__XXX
 SG_ PARK_magnitude0S1 : 9|4@1+ (2,0) [0|0] "" Vector__XXX
 SG_ PARK_timeOfFlight1S1 : 13|9@1+ (0.0512,0) [0|0] "" Vector__XXX
 SG_ PARK_magnitude1S1 : 22|4@1+ (2,0) [0|0] "" Vector__XXX
 SG_ PARK_timeOfFlight2S1 : 26|9@1+ (0.0512,0) [0|0] "" Vector__XXX
 SG_ PARK_magnitude2S1 : 35|4@1+ (2,0) [0|0] "" Vector__XXX
 SG_ PARK_proximityIndicatorS1 : 39|1@1+ (1,0) [0|0] "" Vector__XXX
 SG_ PARK_noiseFlagS1 : 40|1@1+ (1,0) [0|0] "" Vector__XXX
 SG_ PARK_fieldNoiseS1 : 41|4@1+ (1,0) [0|0] "" Vector__XXX
 SG_ PARK_reverbTimeS1 : 45|6@1+ (0.0512,0) [0|0] "" Vector__XXX
 SG_ PARK_validityMask : 51|12@1+ (1,0) [0|0] "" Vector__XXX

BO_ 693 PCS_dcdcRailStatus: 8 Vector__XXX
 SG_ PCS_dcdcLvBusVolt : 0|13@1+ (0.01,0) [0|0] "" Vector__XXX
 SG_ PCS_dcdcHvBusVolt : 16|14@1+ (0.1,0) [0|0] "" Vector__XXX
 SG_ PCS_dcdcLvOutputCurrent : 32|13@1- (0.1,0) [0|0] "" Vector__XXX

BO_ 695 PARK_ussRaw2: 8 Vector__XXX
 SG_ PARK_timeOfFlight0S2 : 0|9@1+ (0.0512,0) [0|0] "" Vector__XXX
 SG_ PARK_magnitude0S2 : 9|4@1+ (2,0) [0|0] "" Vector__XXX
 SG_ PARK_timeOfFlight1S2 : 13|9@1+ (0.0512,0) [0|0] "" Vector__XXX
 SG_ PARK_magnitude1S2 : 22|4@1+ (2,0) [0|0] "" Vector__XXX
 SG_ PARK_timeOfFlight2S2 : 26|9@1+ (0.0512,0) [0|0] "" Vector__XXX
 SG_ PARK_magnitude2S2 : 35|4@1+ (2,0) [0|0] "" Vector__XXX
 SG_ PARK_proximityIndicatorS2 : 39|1@1+ (1,0) [0|0] "" Vector__XXX
 SG_ PARK_noiseFlagS2 : 40|1@1+ (1,0) [0|0] "" Vector__XXX
 SG_ PARK_fieldNoiseS2 : 41|4@1+ (1,0) [0|0] "" Vector__XXX
 SG_ PARK_reverbTimeS2 : 45|6@1+ (0.0512,0) [0|0] "" Vector__XXX
 SG_ PARK_txMask : 51|12@1+ (1,0) [0|0] "" Vector__XXX

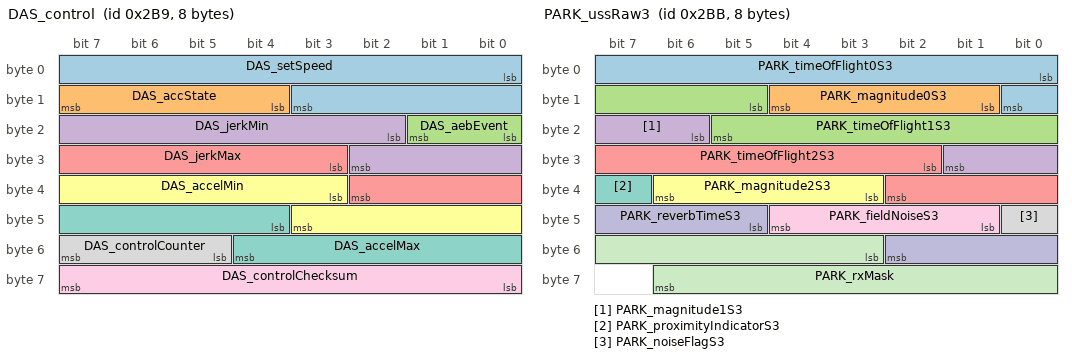
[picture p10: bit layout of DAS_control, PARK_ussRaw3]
BO_ 697 DAS_control: 8 Vector__XXX
 SG_ DAS_setSpeed : 0|12@1+ (0.1,0) [0|0] "" Vector__XXX
 SG_ DAS_accState : 12|4@1+ (1,0) [0|0] "" Vector__XXX
 SG_ DAS_aebEvent : 16|2@1+ (1,0) [0|0] "" Vector__XXX
 SG_ DAS_jerkMin : 18|9@1+ (0.03,-15.232) [0|0] "" Vector__XXX
 SG_ DAS_jerkMax : 27|8@1+ (0.059,0) [0|0] "" Vector__XXX
 SG_ DAS_accelMin : 35|9@1+ (0.04,-15) [0|0] "" Vector__XXX
 SG_ DAS_accelMax : 44|9@1+ (0.04,-15) [0|0] "" Vector__XXX
 SG_ DAS_controlCounter : 53|3@1+ (1,0) [0|0] "" Vector__XXX
 SG_ DAS_controlChecksum : 56|8@1+ (1,0) [0|0] "" Vector__XXX

BO_ 698 UI_radarMapData: 8 Vector__XXX
 SG_ UI_radarTargetDx : 0|8@1+ (1,-95) [0|0] "" Vector__XXX
 SG_ UI_radarTargetDxEnd : 8|8@1+ (1,0) [0|0] "" Vector__XXX
 SG_ UI_radarTargetTrustMap : 16|1@1+ (1,0) [0|0] "" Vector__XXX
 SG_ UI_radarEnableBraking : 17|1@1+ (1,0) [0|0] "" Vector__XXX
 SG_ UI_radarMapDataCounter : 52|4@1+ (1,0) [0|0] "" Vector__XXX
 SG_ UI_radarMapDataChecksum : 56|8@1+ (1,0) [0|0] "" Vector__XXX

BO_ 699 PARK_ussRaw3: 8 Vector__XXX
 SG_ PARK_timeOfFlight0S3 : 0|9@1+ (0.0512,0) [0|0] "" Vector__XXX
 SG_ PARK_magnitude0S3 : 9|4@1+ (2,0) [0|0] "" Vector__XXX
 SG_ PARK_timeOfFlight1S3 : 13|9@1+ (0.0512,0) [0|0] "" Vector__XXX
 SG_ PARK_magnitude1S3 : 22|4@1+ (2,0) [0|0] "" Vector__XXX
 SG_ PARK_timeOfFlight2S3 : 26|9@1+ (0.0512,0) [0|0] "" Vector__XXX
 SG_ PARK_magnitude2S3 : 35|4@1+ (2,0) [0|0] "" Vector__XXX
 SG_ PARK_proximityIndicatorS3 : 39|1@1+ (1,0) [0|0] "" Vector__XXX
 SG_ PARK_noiseFlagS3 : 40|1@1+ (1,0) [0|0] "" Vector__XXX
 SG_ PARK_fieldNoiseS3 : 41|4@1+ (1,0) [0|0] "" Vector__XXX
 SG_ PARK_reverbTimeS3 : 45|6@1+ (0.0512,0) [0|0] "" Vector__XXX
 SG_ PARK_rxMask : 51|12@1+ (1,0) [0|0] "" Vector__XXX

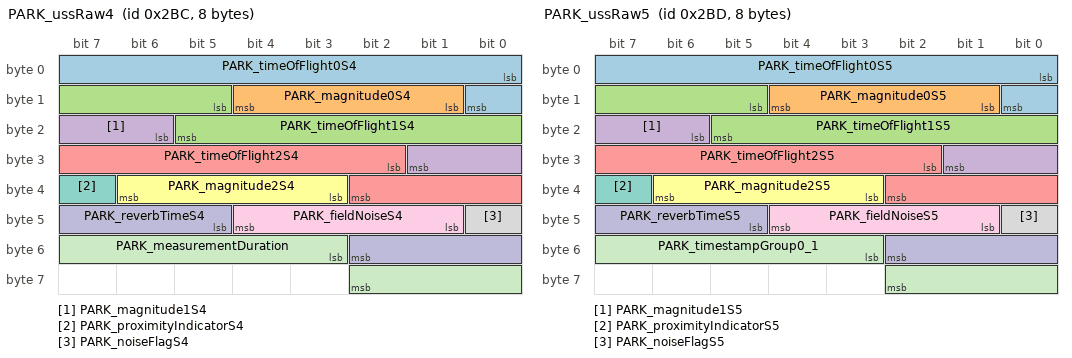
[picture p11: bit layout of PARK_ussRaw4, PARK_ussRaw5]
BO_ 700 PARK_ussRaw4: 8 Vector__XXX
 SG_ PARK_timeOfFlight0S4 : 0|9@1+ (0.0512,0) [0|0] "" Vector__XXX
 SG_ PARK_magnitude0S4 : 9|4@1+ (2,0) [0|0] "" Vector__XXX
 SG_ PARK_timeOfFlight1S4 : 13|9@1+ (0.0512,0) [0|0] "" Vector__XXX
 SG_ PARK_magnitude1S4 : 22|4@1+ (2,0) [0|0] "" Vector__XXX
 SG_ PARK_timeOfFlight2S4 : 26|9@1+ (0.0512,0) [0|0] "" Vector__XXX
 SG_ PARK_magnitude2S4 : 35|4@1+ (2,0) [0|0] "" Vector__XXX
 SG_ PARK_proximityIndicatorS4 : 39|1@1+ (1,0) [0|0] "" Vector__XXX
 SG_ PARK_noiseFlagS4 : 40|1@1+ (1,0) [0|0] "" Vector__XXX
 SG_ PARK_fieldNoiseS4 : 41|4@1+ (1,0) [0|0] "" Vector__XXX
 SG_ PARK_reverbTimeS4 : 45|6@1+ (0.0512,0) [0|0] "" Vector__XXX
 SG_ PARK_measurementDuration : 51|8@1+ (0.0512,0) [0|0] "" Vector__XXX

BO_ 701 PARK_ussRaw5: 8 Vector__XXX
 SG_ PARK_timeOfFlight0S5 : 0|9@1+ (0.0512,0) [0|0] "" Vector__XXX
 SG_ PARK_magnitude0S5 : 9|4@1+ (2,0) [0|0] "" Vector__XXX
 SG_ PARK_timeOfFlight1S5 : 13|9@1+ (0.0512,0) [0|0] "" Vector__XXX
 SG_ PARK_magnitude1S5 : 22|4@1+ (2,0) [0|0] "" Vector__XXX
 SG_ PARK_timeOfFlight2S5 : 26|9@1+ (0.0512,0) [0|0] "" Vector__XXX
 SG_ PARK_magnitude2S5 : 35|4@1+ (2,0) [0|0] "" Vector__XXX
 SG_ PARK_proximityIndicatorS5 : 39|1@1+ (1,0) [0|0] "" Vector__XXX
 SG_ PARK_noiseFlagS5 : 40|1@1+ (1,0) [0|0] "" Vector__XXX
 SG_ PARK_fieldNoiseS5 : 41|4@1+ (1,0) [0|0] "" Vector__XXX
 SG_ PARK_reverbTimeS5 : 45|6@1+ (0.0512,0) [0|0] "" Vector__XXX
 SG_ PARK_timestampGroup0_1 : 51|8@1+ (1,0) [0|0] "" Vector__XXX

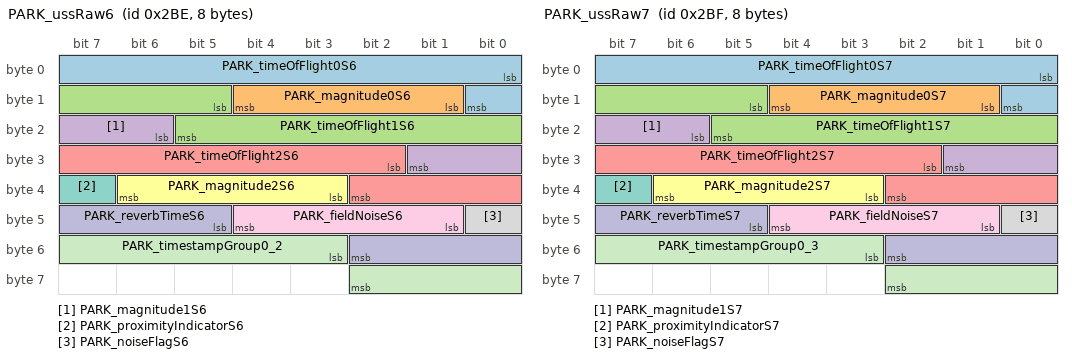
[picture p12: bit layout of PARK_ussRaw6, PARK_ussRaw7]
BO_ 702 PARK_ussRaw6: 8 Vector__XXX
 SG_ PARK_timeOfFlight0S6 : 0|9@1+ (0.0512,0) [0|0] "" Vector__XXX
 SG_ PARK_magnitude0S6 : 9|4@1+ (2,0) [0|0] "" Vector__XXX
 SG_ PARK_timeOfFlight1S6 : 13|9@1+ (0.0512,0) [0|0] "" Vector__XXX
 SG_ PARK_magnitude1S6 : 22|4@1+ (2,0) [0|0] "" Vector__XXX
 SG_ PARK_timeOfFlight2S6 : 26|9@1+ (0.0512,0) [0|0] "" Vector__XXX
 SG_ PARK_magnitude2S6 : 35|4@1+ (2,0) [0|0] "" Vector__XXX
 SG_ PARK_proximityIndicatorS6 : 39|1@1+ (1,0) [0|0] "" Vector__XXX
 SG_ PARK_noiseFlagS6 : 40|1@1+ (1,0) [0|0] "" Vector__XXX
 SG_ PARK_fieldNoiseS6 : 41|4@1+ (1,0) [0|0] "" Vector__XXX
 SG_ PARK_reverbTimeS6 : 45|6@1+ (0.0512,0) [0|0] "" Vector__XXX
 SG_ PARK_timestampGroup0_2 : 51|8@1+ (1,0) [0|0] "" Vector__XXX

BO_ 703 PARK_ussRaw7: 8 Vector__XXX
 SG_ PARK_timeOfFlight0S7 : 0|9@1+ (0.0512,0) [0|0] "" Vector__XXX
 SG_ PARK_magnitude0S7 : 9|4@1+ (2,0) [0|0] "" Vector__XXX
 SG_ PARK_timeOfFlight1S7 : 13|9@1+ (0.0512,0) [0|0] "" Vector__XXX
 SG_ PARK_magnitude1S7 : 22|4@1+ (2,0) [0|0] "" Vector__XXX
 SG_ PARK_timeOfFlight2S7 : 26|9@1+ (0.0512,0) [0|0] "" Vector__XXX
 SG_ PARK_magnitude2S7 : 35|4@1+ (2,0) [0|0] "" Vector__XXX
 SG_ PARK_proximityIndicatorS7 : 39|1@1+ (1,0) [0|0] "" Vector__XXX
 SG_ PARK_noiseFlagS7 : 40|1@1+ (1,0) [0|0] "" Vector__XXX
 SG_ PARK_fieldNoiseS7 : 41|4@1+ (1,0) [0|0] "" Vector__XXX
 SG_ PARK_reverbTimeS7 : 45|6@1+ (0.0512,0) [0|0] "" Vector__XXX
 SG_ PARK_timestampGroup0_3 : 51|8@1+ (1,0) [0|0] "" Vector__XXX

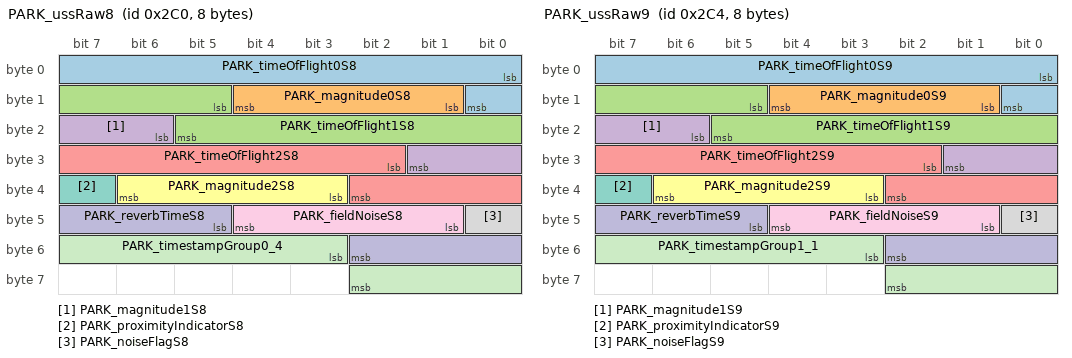
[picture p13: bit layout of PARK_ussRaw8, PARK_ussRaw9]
BO_ 704 PARK_ussRaw8: 8 Vector__XXX
 SG_ PARK_timeOfFlight0S8 : 0|9@1+ (0.0512,0) [0|0] "" Vector__XXX
 SG_ PARK_magnitude0S8 : 9|4@1+ (2,0) [0|0] "" Vector__XXX
 SG_ PARK_timeOfFlight1S8 : 13|9@1+ (0.0512,0) [0|0] "" Vector__XXX
 SG_ PARK_magnitude1S8 : 22|4@1+ (2,0) [0|0] "" Vector__XXX
 SG_ PARK_timeOfFlight2S8 : 26|9@1+ (0.0512,0) [0|0] "" Vector__XXX
 SG_ PARK_magnitude2S8 : 35|4@1+ (2,0) [0|0] "" Vector__XXX
 SG_ PARK_proximityIndicatorS8 : 39|1@1+ (1,0) [0|0] "" Vector__XXX
 SG_ PARK_noiseFlagS8 : 40|1@1+ (1,0) [0|0] "" Vector__XXX
 SG_ PARK_fieldNoiseS8 : 41|4@1+ (1,0) [0|0] "" Vector__XXX
 SG_ PARK_reverbTimeS8 : 45|6@1+ (0.0512,0) [0|0] "" Vector__XXX
 SG_ PARK_timestampGroup0_4 : 51|8@1+ (1,0) [0|0] "" Vector__XXX

BO_ 708 PARK_ussRaw9: 8 Vector__XXX
 SG_ PARK_timeOfFlight0S9 : 0|9@1+ (0.0512,0) [0|0] "" Vector__XXX
 SG_ PARK_magnitude0S9 : 9|4@1+ (2,0) [0|0] "" Vector__XXX
 SG_ PARK_timeOfFlight1S9 : 13|9@1+ (0.0512,0) [0|0] "" Vector__XXX
 SG_ PARK_magnitude1S9 : 22|4@1+ (2,0) [0|0] "" Vector__XXX
 SG_ PARK_timeOfFlight2S9 : 26|9@1+ (0.0512,0) [0|0] "" Vector__XXX
 SG_ PARK_magnitude2S9 : 35|4@1+ (2,0) [0|0] "" Vector__XXX
 SG_ PARK_proximityIndicatorS9 : 39|1@1+ (1,0) [0|0] "" Vector__XXX
 SG_ PARK_noiseFlagS9 : 40|1@1+ (1,0) [0|0] "" Vector__XXX
 SG_ PARK_fieldNoiseS9 : 41|4@1+ (1,0) [0|0] "" Vector__XXX
 SG_ PARK_reverbTimeS9 : 45|6@1+ (0.0512,0) [0|0] "" Vector__XXX
 SG_ PARK_timestampGroup1_1 : 51|8@1+ (1,0) [0|0] "" Vector__XXX

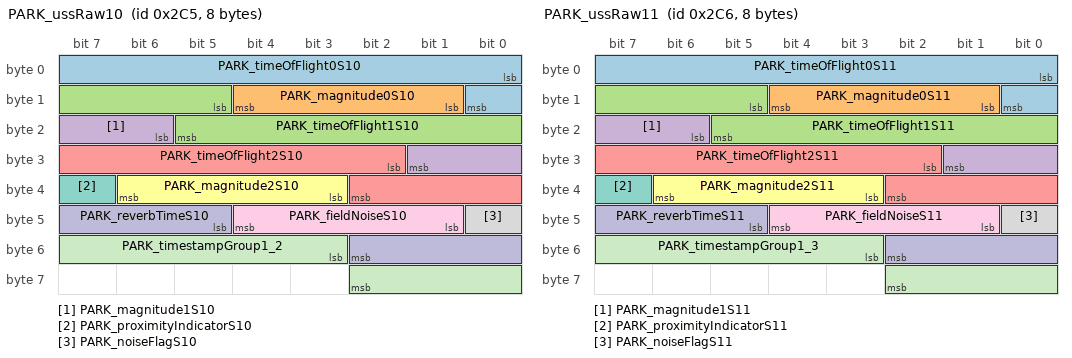
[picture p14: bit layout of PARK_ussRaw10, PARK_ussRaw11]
BO_ 709 PARK_ussRaw10: 8 Vector__XXX
 SG_ PARK_timeOfFlight0S10 : 0|9@1+ (0.0512,0) [0|0] "" Vector__XXX
 SG_ PARK_magnitude0S10 : 9|4@1+ (2,0) [0|0] "" Vector__XXX
 SG_ PARK_timeOfFlight1S10 : 13|9@1+ (0.0512,0) [0|0] "" Vector__XXX
 SG_ PARK_magnitude1S10 : 22|4@1+ (2,0) [0|0] "" Vector__XXX
 SG_ PARK_timeOfFlight2S10 : 26|9@1+ (0.0512,0) [0|0] "" Vector__XXX
 SG_ PARK_magnitude2S10 : 35|4@1+ (2,0) [0|0] "" Vector__XXX
 SG_ PARK_proximityIndicatorS10 : 39|1@1+ (1,0) [0|0] "" Vector__XXX
 SG_ PARK_noiseFlagS10 : 40|1@1+ (1,0) [0|0] "" Vector__XXX
 SG_ PARK_fieldNoiseS10 : 41|4@1+ (1,0) [0|0] "" Vector__XXX
 SG_ PARK_reverbTimeS10 : 45|6@1+ (0.0512,0) [0|0] "" Vector__XXX
 SG_ PARK_timestampGroup1_2 : 51|8@1+ (1,0) [0|0] "" Vector__XXX

BO_ 710 PARK_ussRaw11: 8 Vector__XXX
 SG_ PARK_timeOfFlight0S11 : 0|9@1+ (0.0512,0) [0|0] "" Vector__XXX
 SG_ PARK_magnitude0S11 : 9|4@1+ (2,0) [0|0] "" Vector__XXX
 SG_ PARK_timeOfFlight1S11 : 13|9@1+ (0.0512,0) [0|0] "" Vector__XXX
 SG_ PARK_magnitude1S11 : 22|4@1+ (2,0) [0|0] "" Vector__XXX
 SG_ PARK_timeOfFlight2S11 : 26|9@1+ (0.0512,0) [0|0] "" Vector__XXX
 SG_ PARK_magnitude2S11 : 35|4@1+ (2,0) [0|0] "" Vector__XXX
 SG_ PARK_proximityIndicatorS11 : 39|1@1+ (1,0) [0|0] "" Vector__XXX
 SG_ PARK_noiseFlagS11 : 40|1@1+ (1,0) [0|0] "" Vector__XXX
 SG_ PARK_fieldNoiseS11 : 41|4@1+ (1,0) [0|0] "" Vector__XXX
 SG_ PARK_reverbTimeS11 : 45|6@1+ (0.0512,0) [0|0] "" Vector__XXX
 SG_ PARK_timestampGroup1_3 : 51|8@1+ (1,0) [0|0] "" Vector__XXX

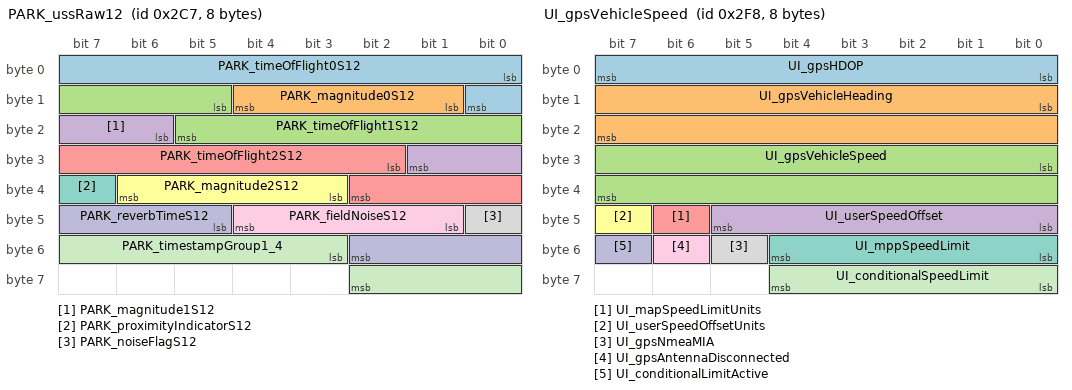
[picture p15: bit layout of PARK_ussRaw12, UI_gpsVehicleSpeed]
BO_ 711 PARK_ussRaw12: 8 Vector__XXX
 SG_ PARK_timeOfFlight0S12 : 0|9@1+ (0.0512,0) [0|0] "" Vector__XXX
 SG_ PARK_magnitude0S12 : 9|4@1+ (2,0) [0|0] "" Vector__XXX
 SG_ PARK_timeOfFlight1S12 : 13|9@1+ (0.0512,0) [0|0] "" Vector__XXX
 SG_ PARK_magnitude1S12 : 22|4@1+ (2,0) [0|0] "" Vector__XXX
 SG_ PARK_timeOfFlight2S12 : 26|9@1+ (0.0512,0) [0|0] "" Vector__XXX
 SG_ PARK_magnitude2S12 : 35|4@1+ (2,0) [0|0] "" Vector__XXX
 SG_ PARK_proximityIndicatorS12 : 39|1@1+ (1,0) [0|0] "" Vector__XXX
 SG_ PARK_noiseFlagS12 : 40|1@1+ (1,0) [0|0] "" Vector__XXX
 SG_ PARK_fieldNoiseS12 : 41|4@1+ (1,0) [0|0] "" Vector__XXX
 SG_ PARK_reverbTimeS12 : 45|6@1+ (0.0512,0) [0|0] "" Vector__XXX
 SG_ PARK_timestampGroup1_4 : 51|8@1+ (1,0) [0|0] "" Vector__XXX

BO_ 723 UI_solarData: 8 Vector__XXX
 SG_ UI_solarAzimuthAngle : 0|16@1- (1,0) [0|0] "" Vector__XXX
 SG_ UI_solarAzimuthAngleCarRef : 16|9@1- (1,0) [0|0] "" Vector__XXX
 SG_ UI_isSunUp : 25|2@1+ (1,0) [0|0] "" Vector__XXX
 SG_ UI_solarElevationAngle : 32|8@1- (1,0) [0|0] "" Vector__XXX
 SG_ UI_screenPCBTemperature : 40|8@1- (0.5,40) [0|0] "" Vector__XXX
 SG_ UI_minsToSunset : 48|8@1+ (10,0) [0|0] "" Vector__XXX
 SG_ UI_minsToSunrise : 56|8@1+ (10,0) [0|0] "" Vector__XXX

BO_ 737 VCFRONT_status: 8 Vector__XXX
 SG_ VCFRONT_statusIndex M : 0|3@1+ (1,0) [0|0] "" Vector__XXX
 SG_ VCFRONT_5VARailStable m3 : 3|1@1+ (1,0) [0|0] "" Vector__XXX
 SG_ VCFRONT_frunkLatchStatus m0 : 3|4@1+ (1,0) [0|0] "" Vector__XXX
 SG_ VCFRONT_iBoosterWakeLine m1 : 3|1@1+ (1,0) [0|0] "" Vector__XXX
 SG_ VCFRONT_5VBRailStable m3 : 4|1@1+ (1,0) [0|0] "" Vector__XXX
 SG_ VCFRONT_epasWakeLine m1 : 4|1@1+ (1,0) [0|0] "" Vector__XXX
 SG_ VCFRONT_12VARailStable m3 : 5|1@1+ (1,0) [0|0] "" Vector__XXX
 SG_ VCFRONT_UP_inDriveState m5 : 5|1@1+ (1,0) [0|0] "" Vector__XXX
 SG_ VCFRONT_iBoosterStateDBG m1 : 5|3@1+ (1,0) [0|0] "" Vector__XXX
 SG_ VCFRONT_12VBRailStable m3 : 6|1@1+ (1,0) [0|0] "" Vector__XXX
 SG_ VCFRONT_UP_UIDisplayOnForUser m5 : 6|1@1+ (1,0) [0|0] "" Vector__XXX
 SG_ VCFRONT_cabinCoolingCapacityLimited m4 : 6|1@1+ (1,0) [0|0] "" Vector__XXX
 SG_ VCFRONT_UP_steeringWheelButtonInteraction m5 : 7|1@1+ (1,0) [0|0] "" Vector__XXX
 SG_ VCFRONT_cabinHeatingCapacityLimited m4 : 7|1@1+ (1,0) [0|0] "" Vector__XXX
 SG_ VCFRONT_railAState m3 : 7|1@1+ (1,0) [0|0] "" Vector__XXX
 SG_ VCFRONT_UP_frontDriverDoorOpen m5 : 8|1@1+ (1,0) [0|0] "" Vector__XXX
 SG_ VCFRONT_compPowerSupportingHvac m4 : 8|11@1+ (10,0) [0|0] "" Vector__XXX
 SG_ VCFRONT_maxEvapHeatRejection m2 : 8|8@1+ (65,0) [0|0] "" Vector__XXX
 SG_ VCFRONT_railBState m3 : 8|1@1+ (1,0) [0|0] "" Vector__XXX
 SG_ VCFRONT_vehicleStatusDBG m1 : 8|5@1+ (1,0) [0|0] "" Vector__XXX
 SG_ VCFRONT_wiperSpeed m0 : 8|4@1+ (1,0) [0|0] "" Vector__XXX
 SG_ VCFRONT_ChargePumpVoltageStable m3 : 9|1@1+ (1,0) [0|0] "" Vector__XXX
 SG_ VCFRONT_UP_frontPassengerDoorOpen m5 : 9|1@1+ (1,0) [0|0] "" Vector__XXX
 SG_ VCFRONT_PEResetLineState m3 : 10|1@1+ (1,0) [0|0] "" Vector__XXX
 SG_ VCFRONT_UP_rearDriverDoorOpen m5 : 10|1@1+ (1,0) [0|0] "" Vector__XXX
 SG_ VCFRONT_HSDInitCompleteU13 m3 : 11|1@1+ (1,0) [0|0] "" Vector__XXX
 SG_ VCFRONT_UP_rearPassengerDoorOpen m5 : 11|1@1+ (1,0) [0|0] "" Vector__XXX
 SG_ VCFRONT_HSDInitCompleteU16 m3 : 12|1@1+ (1,0) [0|0] "" Vector__XXX
 SG_ VCFRONT_UP_trunkOpen m5 : 12|1@1+ (1,0) [0|0] "" Vector__XXX
 SG_ VCFRONT_wiperPosition m0 : 12|3@1+ (1,0) [0|0] "" Vector__XXX
 SG_ VCFRONT_UP_inTransportMode m5 : 13|1@1+ (1,0) [0|0] "" Vector__XXX
 SG_ VCFRONT_timeSpentSleeping m1 : 13|10@1+ (1,0) [0|0] "" Vector__XXX
 SG_ VCFRONT_UP_anyClosureIsOpen m5 : 14|1@1+ (1,0) [0|0] "" Vector__XXX
 SG_ VCFRONT_UP_driverPresent m5 : 15|1@1+ (1,0) [0|0] "" Vector__XXX
 SG_ VCFRONT_wiperBlocked m0 : 15|1@1+ (1,0) [0|0] "" Vector__XXX
 SG_ VCFRONT_UP_brakePressed m5 : 16|1@1+ (1,0) [0|0] "" Vector__XXX
 SG_ VCFRONT_minEvapHeatRejection m2 : 16|8@1+ (15,0) [0|0] "" Vector__XXX
 SG_ VCFRONT_vbatMonitorVoltage m3 : 16|12@1+ (0.005443676098,0) [0|0] "" Vector__XXX
 SG_ VCFRONT_wiperState m0 : 16|4@1+ (1,0) [0|0] "" Vector__XXX
 SG_ VCFRONT_UP_chargePortDoorOpen m5 : 17|1@1+ (1,0) [0|0] "" Vector__XXX
 SG_ VCFRONT_UP_UIChargePortDoorRequest m5 : 18|1@1+ (1,0) [0|0] "" Vector__XXX
 SG_ VCFRONT_UP_UIUserActivity m5 : 19|1@1+ (1,0) [0|0] "" Vector__XXX
 SG_ VCFRONT_compPowerSupportingPT m4 : 19|11@1+ (10,0) [0|0] "" Vector__XXX
 SG_ VCFRONT_UP_passengerPresent m5 : 20|1@1+ (1,0) [0|0] "" Vector__XXX
 SG_ VCFRONT_crashDetectedType m0 : 20|2@1+ (1,0) [0|0] "" Vector__XXX
 SG_ VCFRONT_UP_chargeStateTransitioned m5 : 21|1@1+ (1,0) [0|0] "" Vector__XXX
 SG_ VCFRONT_crashState m0 : 22|2@1+ (1,0) [0|0] "" Vector__XXX
 SG_ VCFRONT_crashUnlockOverrideSet m0 : 24|1@1+ (1,0) [0|0] "" Vector__XXX
 SG_ VCFRONT_freezeEvapITerm m2 : 24|1@1+ (1,0) [0|0] "" Vector__XXX
 SG_ VCFRONT_sleepCurrent m1 : 24|12@1+ (0.125,-511.875) [0|0] "" Vector__XXX
 SG_ VCFRONT_isEvapOperationAllowed m2 : 25|1@1+ (1,0) [0|0] "" Vector__XXX
 SG_ VCFRONT_chillerDemandActive m2 : 26|1@1+ (1,0) [0|0] "" Vector__XXX
 SG_ VCFRONT_compPerfRecoveryLimited m2 : 27|1@1+ (1,0) [0|0] "" Vector__XXX
 SG_ VCFRONT_AS8510Voltage m3 : 28|12@1+ (0.005443676098,0) [0|0] "" Vector__XXX
 SG_ VCFRONT_hvacModeNotAttainable m2 : 28|1@1+ (1,0) [0|0] "" Vector__XXX
 SG_ VCFRONT_hasLowRefrigerant m2 : 29|1@1+ (1,0) [0|0] "" Vector__XXX
 SG_ VCFRONT_isColdStartRunning m2 : 30|1@1+ (1,0) [0|0] "" Vector__XXX
 SG_ VCFRONT_maxHeatingPowerLeftCC m4 : 30|7@1+ (100,0) [0|0] "" Vector__XXX
 SG_ VCFRONT_isHeatPumpOilPurgeActive m2 : 31|1@1+ (1,0) [0|0] "" Vector__XXX
 SG_ VCFRONT_lastUserPresenceUpdateEpochTime m5 : 32|32@1+ (1,0) [0|0] "" Vector__XXX
 SG_ VCFRONT_pressureRefrigSuction m2 : 32|7@1+ (0.125,0) [0|0] "" Vector__XXX
 SG_ VCFRONT_wiperHealth m0 : 32|3@1+ (1,0) [0|0] "" Vector__XXX
 SG_ VCFRONT_wiperLINHealth m0 : 35|3@1+ (1,0) [0|0] "" Vector__XXX
 SG_ VCFRONT_hibernationState m1 : 36|3@1+ (1,0) [0|0] "" Vector__XXX
 SG_ VCFRONT_maxHeatingPowerRightCC m4 : 37|7@1+ (100,0) [0|0] "" Vector__XXX
 SG_ VCFRONT_frunkLatchCurrent m0 : 40|8@1- (0.15748031496062992,0) [0|0] "" Vector__XXX
 SG_ VCFRONT_pressureRefrigDischarge m2 : 40|9@1+ (0.08,0) [0|0] "" Vector__XXX
 SG_ VCFRONT_vbatProt m3 : 40|12@1+ (0.005443676098,0) [0|0] "" Vector__XXX
 SG_ VCFRONT_wiperECUType m1 : 40|2@1+ (1,0) [0|0] "" Vector__XXX
 SG_ VCFRONT_wiperHeaterState m1 : 42|3@1+ (1,0) [0|0] "" Vector__XXX
 SG_ VCFRONT_activeLouverOpenPos m4 : 44|7@1+ (1,0) [0|0] "" Vector__XXX
 SG_ VCFRONT_occupantCount m1 : 45|3@1+ (1,0) [0|0] "" Vector__XXX
 SG_ VCFRONT_closureEasterEggState m1 : 48|3@1+ (1,0) [0|0] "" Vector__XXX
 SG_ VCFRONT_frunkInteriorRelSwitch m0 : 48|1@1+ (1,0) [0|0] "" Vector__XXX
 SG_ VCFRONT_anyClosureOpen m0 : 49|1@1+ (1,0) [0|0] "" Vector__XXX
 SG_ VCFRONT_hvacPerfTestCommand m2 : 49|3@1+ (1,0) [0|0] "" Vector__XXX
 SG_ VCFRONT_anyDoorOpen m0 : 50|1@1+ (1,0) [0|0] "" Vector__XXX
 SG_ VCFRONT_activeLouverState m4 : 51|5@1+ (1,0) [0|0] "" Vector__XXX
 SG_ VCFRONT_espWakeLine m1 : 51|1@1+ (1,0) [0|0] "" Vector__XXX
 SG_ VCFRONT_hornOn m0 : 51|1@1+ (1,0) [0|0] "" Vector__XXX
 SG_ VCFRONT_allowEvapInLowAmbient m1 : 52|1@1+ (1,0) [0|0] "" Vector__XXX
 SG_ VCFRONT_coolantFillRoutineStatus m2 : 52|2@1+ (1,0) [0|0] "" Vector__XXX
 SG_ VCFRONT_logVerbosity m3 : 52|3@1+ (1,0) [0|0] "" Vector__XXX
 SG_ VCFRONT_radarHeaterState m0 : 52|3@1+ (1,0) [0|0] "" Vector__XXX
 SG_ VCFRONT_potentialRadiatorSteam m1 : 53|1@1+ (1,0) [0|0] "" Vector__XXX
 SG_ VCFRONT_potentialRadiatorSteamUI m1 : 54|1@1+ (1,0) [0|0] "" Vector__XXX
 SG_ VCFRONT_refrigFillRoutineStatus m2 : 54|2@1+ (1,0) [0|0] "" Vector__XXX
 SG_ VCFRONT_hvacReqOffForFasterCharge m1 : 55|1@1+ (1,0) [0|0] "" Vector__XXX
 SG_ VCFRONT_trunkExteriorWakeSwitch m0 : 55|1@1+ (1,0) [0|0] "" Vector__XXX
 SG_ VCFRONT_isCOP1Running m2 : 56|1@1+ (1,0) [0|0] "" Vector__XXX
 SG_ VCFRONT_limitedSplitTempDeltaEnforced m1 : 56|1@1+ (1,0) [0|0] "" Vector__XXX
 SG_ VCFRONT_windshieldCameraHeaterPower m4 : 56|6@1+ (2.5,0) [0|0] "" Vector__XXX
 SG_ VCFRONT_closeValvesRoutineStatus m2 : 57|2@1+ (1,0) [0|0] "" Vector__XXX
 SG_ VCFRONT_passengerBuckleStatus m0 : 57|1@1+ (1,0) [0|0] "" Vector__XXX
 SG_ VCFRONT_frunkLatchType m0 : 58|2@1+ (1,0) [0|0] "" Vector__XXX
 SG_ VCFRONT_thermalPerfTestRunning m2 : 59|1@1+ (1,0) [0|0] "" Vector__XXX
 SG_ VCFRONT_headlampLeftFanStatus m0 : 60|1@1+ (1,0) [0|0] "" Vector__XXX
 SG_ VCFRONT_headlampRightFanStatus m0 : 61|1@1+ (1,0) [0|0] "" Vector__XXX
 SG_ VCFRONT_frunkAccessPost m0 : 62|1@1+ (1,0) [0|0] "" Vector__XXX
 SG_ VCFRONT_isActiveHeatingBattery m0 : 63|1@1+ (1,0) [0|0] "" Vector__XXX

BO_ 744 EPBR_status: 8 Vector__XXX
 SG_ EPBR_systemStatus : 0|4@1+ (1,0) [0|0] "" Vector__XXX
 SG_ EPBR_freeRollModeStatus : 4|2@1+ (1,0) [0|0] "" Vector__XXX
 SG_ EPBR_driverIsLeaving : 6|1@1+ (1,0) [0|0] "" Vector__XXX
 SG_ EPBR_driverIsLeavingAnySpeed : 7|1@1+ (1,0) [0|0] "" Vector__XXX
 SG_ EPBR_systemCdpAvailable : 8|1@1+ (1,0) [0|0] "" Vector__XXX
 SG_ EPBR_chimeRequest : 9|3@1+ (1,0) [0|0] "" Vector__XXX
 SG_ EPBR_telltale : 12|3@1+ (1,0) [0|0] "" Vector__XXX
 SG_ EPBR_audioCurrentSpikeDetected : 15|1@1+ (1,0) [0|0] "" Vector__XXX
 SG_ EPBR_redundantBrakingEnabled : 16|1@1+ (1,0) [0|0] "" Vector__XXX
 SG_ EPBR_summonEnabled : 17|1@1+ (1,0) [0|0] "" Vector__XXX
 SG_ EPBR_brakeLight : 18|1@1+ (1,0) [0|0] "" Vector__XXX
 SG_ EPBR_epbConfigMismatch : 19|1@1+ (1,0) [0|0] "" Vector__XXX
 SG_ EPBR_brakeConfirmedPressed : 20|1@1+ (1,0) [0|0] "" Vector__XXX
 SG_ EPBR_requestUserConfirmation : 21|1@1+ (1,0) [0|0] "" Vector__XXX
 SG_ EPBR_uiWinchModeMiscBlocking : 22|1@1+ (1,0) [0|0] "" Vector__XXX
 SG_ EPBR_winchModeActive : 23|1@1+ (1,0) [0|0] "" Vector__XXX
 SG_ EPBR_updateMode : 24|1@1+ (1,0) [0|0] "" Vector__XXX
 SG_ EPBR_winchModePermissive : 25|1@1+ (1,0) [0|0] "" Vector__XXX
 SG_ EPBR_winchModePending : 26|1@1+ (1,0) [0|0] "" Vector__XXX
 SG_ EPBR_cdpRequest : 27|1@1+ (1,0) [0|0] "" Vector__XXX
 SG_ EPBR_uiParkAvailable : 28|2@1+ (1,0) [0|0] "" Vector__XXX
 SG_ EPBR_brakeDiscWipeRequest : 30|2@1+ (1,0) [0|0] "" Vector__XXX
 SG_ EPBR_showUiGearShifter : 32|1@1+ (1,0) [0|0] "" Vector__XXX
 SG_ EPBR_uiWinchModeLvStatus : 33|2@1+ (1,0) [0|0] "" Vector__XXX
 SG_ EPBR_contactorCycleNotNeededForWinchEntry : 35|1@1+ (1,0) [0|0] "" Vector__XXX
 SG_ EPBR_showStalkFaultedOnUi : 45|1@1+ (1,0) [0|0] "" Vector__XXX
 SG_ EPBR_espPowerRequest : 46|1@1+ (1,0) [0|0] "" Vector__XXX
 SG_ EPBR_okToPark : 47|1@1+ (1,0) [0|0] "" Vector__XXX
 SG_ EPBR_hornRequest : 48|1@1+ (1,0) [0|0] "" Vector__XXX
 SG_ EPBR_winchModeAvailable : 49|1@1+ (1,0) [0|0] "" Vector__XXX
 SG_ EPBR_bothDisconnected : 50|1@1+ (1,0) [0|0] "" Vector__XXX
 SG_ EPBR_blockDrive : 51|1@1+ (1,0) [0|0] "" Vector__XXX
 SG_ EPBR_statusCounter : 52|4@1+ (1,0) [0|0] "" Vector__XXX
 SG_ EPBR_statusChecksum : 56|8@1+ (1,0) [0|0] "" Vector__XXX

BO_ 760 UI_gpsVehicleSpeed: 8 Vector__XXX
 SG_ UI_gpsHDOP : 0|8@1+ (0.1,0) [0|0] "" Vector__XXX
 SG_ UI_gpsVehicleHeading : 8|16@1+ (0.0078125,0) [0|0] "" Vector__XXX
 SG_ UI_gpsVehicleSpeed : 24|16@1+ (0.00390625,0) [0|0] "" Vector__XXX
 SG_ UI_userSpeedOffset : 40|6@1+ (1,-30) [0|0] "" Vector__XXX
 SG_ UI_mapSpeedLimitUnits : 46|1@1+ (1,0) [0|0] "" Vector__XXX
 SG_ UI_userSpeedOffsetUnits : 47|1@1+ (1,0) [0|0] "" Vector__XXX
 SG_ UI_mppSpeedLimit : 48|5@1+ (5,0) [0|0] "" Vector__XXX
 SG_ UI_gpsNmeaMIA : 53|1@1+ (1,0) [0|0] "" Vector__XXX
 SG_ UI_gpsAntennaDisconnected : 54|1@1+ (1,0) [0|0] "" Vector__XXX
 SG_ UI_conditionalLimitActive : 55|1@1+ (1,0) [0|0] "" Vector__XXX
 SG_ UI_conditionalSpeedLimit : 56|5@1+ (5,0) [0|0] "" Vector__XXX

BO_ 771 OCS1P_status: 8 Vector__XXX
 SG_ OCS1P_occupantClassification : 0|8@1+ (1,0) [0|0] "" Vector__XXX
 SG_ OCS1P_occupantClassificationQF : 8|1@1+ (1,0) [0|0] "" Vector__XXX
 SG_ OCS1P_occupiedState : 9|2@1+ (1,0) [0|0] "" Vector__XXX
 SG_ OCS1P_triggerSnapshot : 11|5@1+ (1,0) [0|0] "" Vector__XXX
 SG_ OCS1P_occupantClassificationRaw : 16|3@1+ (1,0) [0|0] "" Vector__XXX
 SG_ OCS1P_occupantClassificationSelf : 19|3@1+ (1,0) [0|0] "" Vector__XXX
 SG_ OCS1P_occupantClassificationRawCap : 22|3@1+ (1,0) [0|0] "" Vector__XXX
 SG_ OCS1P_occupantClassificationCap : 25|3@1+ (1,0) [0|0] "" Vector__XXX
 SG_ OCS1P_classificationHeld : 30|1@1+ (1,0) [0|0] "" Vector__XXX
 SG_ OCS1P_cushionStable : 31|1@1+ (1,0) [0|0] "" Vector__XXX
 SG_ OCS1P_classificationExtHold : 32|1@1+ (1,0) [0|0] "" Vector__XXX
 SG_ OCS1P_classificationHoldState : 33|3@1+ (1,0) [0|0] "" Vector__XXX
 SG_ OCS1P_classificationVariant : 36|3@1+ (1,0) [0|0] "" Vector__XXX
 SG_ OCS1P_sandwichDisabled : 39|1@1+ (1,0) [0|0] "" Vector__XXX
 SG_ OCS1P_noSandwichType : 40|2@1+ (1,0) [0|0] "" Vector__XXX
 SG_ OCS1P_sandwichBoundaryType : 42|1@1+ (1,0) [0|0] "" Vector__XXX
 SG_ OCS1P_sbrBoundaryType : 43|1@1+ (1,0) [0|0] "" Vector__XXX
 SG_ OCS1P_occupiedStateCap : 45|2@1+ (1,0) [0|0] "" Vector__XXX
 SG_ OCS1P_seatbackStable : 47|1@1+ (1,0) [0|0] "" Vector__XXX
 SG_ OCS1P_sandwichStable : 48|1@1+ (1,0) [0|0] "" Vector__XXX
 SG_ OCS1P_cushionStableCap : 49|1@1+ (1,0) [0|0] "" Vector__XXX
 SG_ OCS1P_seatbackStableCap : 50|1@1+ (1,0) [0|0] "" Vector__XXX
 SG_ OCS1P_classificationHeldCap : 51|1@1+ (1,0) [0|0] "" Vector__XXX
 SG_ OCS1P_statusCounter : 52|4@1+ (1,0) [0|0] "" Vector__XXX
 SG_ OCS1P_statusChecksum : 56|8@1+ (1,0) [0|0] "" Vector__XXX

BO_ 778 DAS_object: 8 Vector__XXX
 SG_ DAS_objectId M : 0|3@1+ (1,0) [0|0] "" Vector__XXX
 SG_ DAS_cutinVehType m3 : 3|3@1+ (1,0) [0|0] "" Vector__XXX
 SG_ DAS_leadVehType m0 : 3|3@1+ (1,0) [0|0] "" Vector__XXX
 SG_ DAS_leftVehType m1 : 3|3@1+ (1,0) [0|0] "" Vector__XXX
 SG_ DAS_rightVehType m2 : 3|3@1+ (1,0) [0|0] "" Vector__XXX
 SG_ DAS_roadSignColor m4 : 3|3@1+ (1,0) [0|0] "" Vector__XXX
 SG_ DAS_roadSignId m4 : 6|8@1+ (1,0) [0|0] "" Vector__XXX
 SG_ DAS_cutinVehRelevantForControl m3 : 7|1@1+ (1,0) [0|0] "" Vector__XXX
 SG_ DAS_leadVehRelevantForControl m0 : 7|1@1+ (1,0) [0|0] "" Vector__XXX
 SG_ DAS_leftVehRelevantForControl m1 : 7|1@1+ (1,0) [0|0] "" Vector__XXX
 SG_ DAS_rightVehRelevantForControl m2 : 7|1@1+ (1,0) [0|0] "" Vector__XXX
 SG_ DAS_cutinVehDx m3 : 8|8@1+ (0.5,0) [0|0] "" Vector__XXX
 SG_ DAS_leadVehDx m0 : 8|8@1+ (0.5,0) [0|0] "" Vector__XXX
 SG_ DAS_leadVehHeading m5 : 8|8@1+ (0.0245437,-3.1415936) [0|0] "" Vector__XXX
 SG_ DAS_leftVehDx m1 : 8|8@1+ (0.5,0) [0|0] "" Vector__XXX
 SG_ DAS_rightVehDx m2 : 8|8@1+ (0.5,0) [0|0] "" Vector__XXX
 SG_ DAS_roadSignStopLineDist m4 : 14|10@1+ (0.2,-20) [0|0] "" Vector__XXX
 SG_ DAS_cutinVehVxRel m3 : 16|4@1+ (4,-30) [0|0] "" Vector__XXX
 SG_ DAS_leadVeh2Heading m5 : 16|8@1+ (0.0245437,-3.1415936) [0|0] "" Vector__XXX
 SG_ DAS_leadVehVxRel m0 : 16|4@1+ (4,-30) [0|0] "" Vector__XXX
 SG_ DAS_leftVehVxRel m1 : 16|4@1+ (4,-30) [0|0] "" Vector__XXX
 SG_ DAS_rightVehVxRel m2 : 16|4@1+ (4,-30) [0|0] "" Vector__XXX
 SG_ DAS_cutinVehDy m3 : 20|7@1+ (0.35,-22.05) [0|0] "" Vector__XXX
 SG_ DAS_leadVehDy m0 : 20|7@1+ (0.35,-22.05) [0|0] "" Vector__XXX
 SG_ DAS_leftVehDy m1 : 20|7@1+ (0.35,-22.05) [0|0] "" Vector__XXX
 SG_ DAS_rightVehDy m2 : 20|7@1+ (0.35,-22.05) [0|0] "" Vector__XXX
 SG_ DAS_leftVehHeading m5 : 24|8@1+ (0.0245437,-3.1415936) [0|0] "" Vector__XXX
 SG_ DAS_roadSignControlActive m4 : 24|1@1+ (1,0) [0|0] "" Vector__XXX
 SG_ DAS_roadSignSource m4 : 25|2@1+ (1,0) [0|0] "" Vector__XXX
 SG_ DAS_cutinVehId m3 : 27|7@1+ (1,0) [0|0] "" Vector__XXX
 SG_ DAS_leadVehId m0 : 27|7@1+ (1,0) [0|0] "" Vector__XXX
 SG_ DAS_leftVehId m1 : 27|7@1+ (1,0) [0|0] "" Vector__XXX
 SG_ DAS_rightVehId m2 : 27|7@1+ (1,0) [0|0] "" Vector__XXX
 SG_ DAS_roadSignArrow m4 : 27|3@1+ (1,0) [0|0] "" Vector__XXX
 SG_ DAS_roadSignOrientation m4 : 30|2@1+ (1,0) [0|0] "" Vector__XXX
 SG_ DAS_leftVeh2Heading m5 : 32|8@1+ (0.0245437,-3.1415936) [0|0] "" Vector__XXX
 SG_ DAS_leadVeh2Type m0 : 34|3@1+ (1,0) [0|0] "" Vector__XXX
 SG_ DAS_leftVeh2Type m1 : 34|3@1+ (1,0) [0|0] "" Vector__XXX
 SG_ DAS_rightVeh2Type m2 : 34|3@1+ (1,0) [0|0] "" Vector__XXX
 SG_ DAS_leadVeh2RelevantForControl m0 : 38|1@1+ (1,0) [0|0] "" Vector__XXX
 SG_ DAS_leftVeh2RelevantForControl m1 : 38|1@1+ (1,0) [0|0] "" Vector__XXX
 SG_ DAS_rightVeh2RelevantForControl m2 : 38|1@1+ (1,0) [0|0] "" Vector__XXX
 SG_ DAS_leadVeh2Dx m0 : 39|8@1+ (0.5,0) [0|0] "" Vector__XXX
 SG_ DAS_leftVeh2Dx m1 : 39|8@1+ (0.5,0) [0|0] "" Vector__XXX
 SG_ DAS_rightVeh2Dx m2 : 39|8@1+ (0.5,0) [0|0] "" Vector__XXX
 SG_ DAS_rightVehHeading m5 : 40|8@1+ (0.0245437,-3.1415936) [0|0] "" Vector__XXX
 SG_ DAS_leadVeh2VxRel m0 : 47|4@1+ (4,-30) [0|0] "" Vector__XXX
 SG_ DAS_leftVeh2VxRel m1 : 47|4@1+ (4,-30) [0|0] "" Vector__XXX
 SG_ DAS_rightVeh2VxRel m2 : 47|4@1+ (4,-30) [0|0] "" Vector__XXX
 SG_ DAS_rightVeh2Heading m5 : 48|8@1+ (0.0245437,-3.1415936) [0|0] "" Vector__XXX
 SG_ DAS_leadVeh2Dy m0 : 51|7@1+ (0.35,-22.05) [0|0] "" Vector__XXX
 SG_ DAS_leftVeh2Dy m1 : 51|7@1+ (0.35,-22.05) [0|0] "" Vector__XXX
 SG_ DAS_rightVeh2Dy m2 : 51|7@1+ (0.35,-22.05) [0|0] "" Vector__XXX
 SG_ DAS_cutinVehHeading m5 : 56|8@1+ (0.0245437,-3.1415936) [0|0] "" Vector__XXX
 SG_ DAS_leadVeh2Id m0 : 58|6@1+ (1,0) [0|0] "" Vector__XXX
 SG_ DAS_leftVeh2Id m1 : 58|6@1+ (1,0) [0|0] "" Vector__XXX
 SG_ DAS_rightVeh2Id m2 : 58|6@1+ (1,0) [0|0] "" Vector__XXX

BO_ 781 DAS_positioningEngineStatus: 8 Vector__XXX
 SG_ DAS_positioningEngineStatusMultiplexer M : 0|4@1+ (1,0) [0|0] "" Vector__XXX
 SG_ DAS_meoSolverNumRuns m2 : 4|2@1+ (1,0) [0|0] "" Vector__XXX
 SG_ DAS_meoVersion m1 : 4|5@1+ (1,0) [0|0] "" Vector__XXX
 SG_ DAS_positioningEngineTimesyncSource m0 : 4|2@1+ (1,0) [0|0] "" Vector__XXX
 SG_ DAS_vioMultiGpsSelectedSource m3 : 4|3@1+ (1,0) [0|0] "" Vector__XXX
 SG_ DAS_hasParsedEphemerides m0 : 6|1@1+ (1,0) [0|0] "" Vector__XXX
 SG_ DAS_meoSolverReportTerminationType m2 : 6|3@1+ (1,0) [0|0] "" Vector__XXX
 SG_ DAS_numParsedObservations m0 : 7|2@1+ (1,0) [0|0] "" Vector__XXX
 SG_ DAS_vioMultiGpsPeCooldownActive m3 : 7|1@1+ (1,0) [0|0] "" Vector__XXX
 SG_ DAS_vioMultiGpsPeSppTdcpConsistentWithRawGps m3 : 8|1@1+ (1,0) [0|0] "" Vector__XXX
 SG_ DAS_meoSolutionStatus m1 : 9|5@1+ (1,0) [0|0] "" Vector__XXX
 SG_ DAS_meoSolverReportTotalTimeS m2 : 9|3@1+ (1,0) [0|0] "" Vector__XXX
 SG_ DAS_sppSolutionStatus m0 : 9|4@1+ (1,0) [0|0] "" Vector__XXX
 SG_ DAS_vioMultiGpsPeMeoConsistentWithRawGps m3 : 9|1@1+ (1,0) [0|0] "" Vector__XXX
 SG_ DAS_vioMultiGpsPeSppTdcpVsRawGpsTransDiscrepM m3 : 10|4@1+ (1,0) [0|0] "" Vector__XXX
 SG_ DAS_meoHorizontalAccuracyM m2 : 12|6@1+ (1,0) [0|0] "" Vector__XXX
 SG_ DAS_sppPdopM m0 : 13|3@1+ (1,0) [0|0] "" Vector__XXX
 SG_ DAS_meoNodesSize m1 : 14|4@1+ (1,0) [0|0] "" Vector__XXX
 SG_ DAS_vioMultiGpsPeMeoVsRawGpsTransDiscrepM m3 : 14|4@1+ (1,0) [0|0] "" Vector__XXX
 SG_ DAS_sppNumSatellitesUsed m0 : 16|5@1+ (1,0) [0|0] "" Vector__XXX
 SG_ DAS_meoNumSdprConstraints0 m1 : 18|2@1+ (1,0) [0|0] "" Vector__XXX
 SG_ DAS_meoVerticalAccuracyM m2 : 18|6@1+ (1,0) [0|0] "" Vector__XXX
 SG_ DAS_vioMultiGpsPeSppTdcpVsRawGpsRotDiscrepDeg m3 : 18|3@1+ (1,0) [0|0] "" Vector__XXX
 SG_ DAS_meoNumSdprConstraints1 m1 : 20|2@1+ (1,0) [0|0] "" Vector__XXX
 SG_ DAS_tdcpSolutionStatus m0 : 21|5@1+ (1,0) [0|0] "" Vector__XXX
 SG_ DAS_vioMultiGpsPeMeoVsRawGpsRotDiscrepDeg m3 : 21|3@1+ (1,0) [0|0] "" Vector__XXX
 SG_ DAS_meoNumSdprConstraints2 m1 : 22|2@1+ (1,0) [0|0] "" Vector__XXX
 SG_ DAS_meoHeadingAccuracyDeg m2 : 24|3@1+ (1,0) [0|0] "" Vector__XXX
 SG_ DAS_meoNumSdprConstraints3 m1 : 24|2@1+ (1,0) [0|0] "" Vector__XXX
 SG_ DAS_publishedGpsSource m3 : 24|2@1+ (1,0) [0|0] "" Vector__XXX
 SG_ DAS_bluefinEnabled m3 : 26|1@1+ (1,0) [0|0] "" Vector__XXX
 SG_ DAS_meoNumSdprConstraints4 m1 : 26|2@1+ (1,0) [0|0] "" Vector__XXX
 SG_ DAS_tdcpNumSatellitesUsed m0 : 26|5@1+ (1,0) [0|0] "" Vector__XXX
 SG_ DAS_meoHeadingValid m2 : 27|1@1+ (1,0) [0|0] "" Vector__XXX
 SG_ DAS_orioleDisabled m3 : 27|1@1+ (1,0) [0|0] "" Vector__XXX
 SG_ DAS_meoNumSatellitesUsed m2 : 28|5@1+ (1,0) [0|0] "" Vector__XXX
 SG_ DAS_meoNumSdprConstraints5 m1 : 28|2@1+ (1,0) [0|0] "" Vector__XXX
 SG_ DAS_meoNumSdprConstraints6 m1 : 30|2@1+ (1,0) [0|0] "" Vector__XXX
 SG_ DAS_meoNumSdprConstraints7 m1 : 32|2@1+ (1,0) [0|0] "" Vector__XXX
 SG_ DAS_meoGpsQualityLevel m2 : 33|3@1+ (1,0) [0|0] "" Vector__XXX
 SG_ DAS_meoNumSdprConstraints8 m1 : 34|2@1+ (1,0) [0|0] "" Vector__XXX
 SG_ DAS_meoFixType m2 : 36|3@1+ (1,0) [0|0] "" Vector__XXX
 SG_ DAS_meoNumSdprConstraints9 m1 : 36|2@1+ (1,0) [0|0] "" Vector__XXX
 SG_ DAS_meoNumDdcpConstraints0 m1 : 38|2@1+ (1,0) [0|0] "" Vector__XXX
 SG_ DAS_meoResetCount m2 : 39|3@1+ (1,0) [0|0] "" Vector__XXX
 SG_ DAS_meoNumDdcpConstraints1 m1 : 40|2@1+ (1,0) [0|0] "" Vector__XXX
 SG_ DAS_lastMeoResetReason m2 : 42|2@1+ (1,0) [0|0] "" Vector__XXX
 SG_ DAS_meoNumDdcpConstraints2 m1 : 42|2@1+ (1,0) [0|0] "" Vector__XXX
 SG_ DAS_meoNumDdcpConstraints3 m1 : 44|2@1+ (1,0) [0|0] "" Vector__XXX
 SG_ DAS_meoNumDdcpConstraints4 m1 : 46|2@1+ (1,0) [0|0] "" Vector__XXX
 SG_ DAS_meoNumDdcpConstraints5 m1 : 48|2@1+ (1,0) [0|0] "" Vector__XXX
 SG_ DAS_meoNumDdcpConstraints6 m1 : 50|2@1+ (1,0) [0|0] "" Vector__XXX
 SG_ DAS_meoNumDdcpConstraints7 m1 : 52|2@1+ (1,0) [0|0] "" Vector__XXX
 SG_ DAS_meoNumDdcpConstraints8 m1 : 54|2@1+ (1,0) [0|0] "" Vector__XXX
 SG_ DAS_meoNumDdcpConstraints9 m1 : 56|2@1+ (1,0) [0|0] "" Vector__XXX

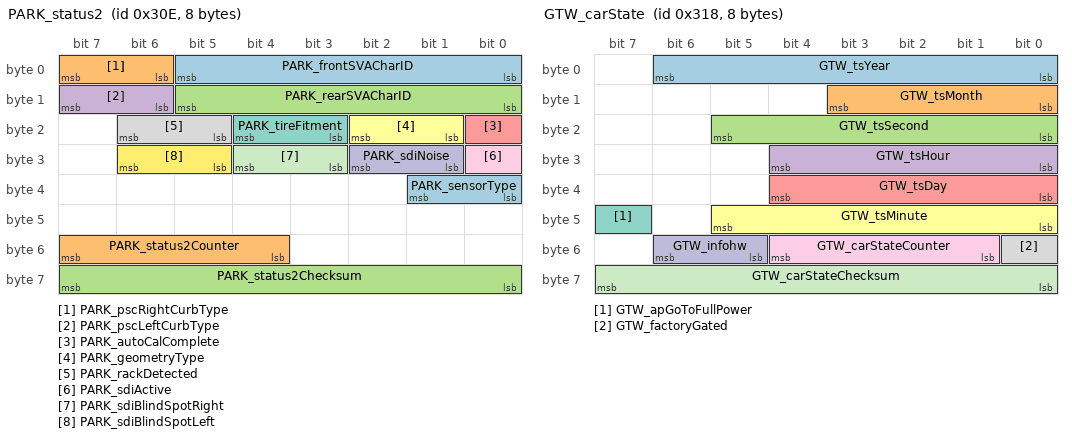
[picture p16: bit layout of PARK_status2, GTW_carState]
BO_ 782 PARK_status2: 8 Vector__XXX
 SG_ PARK_frontSVACharID : 0|6@1+ (1,0) [0|0] "" Vector__XXX
 SG_ PARK_pscRightCurbType : 6|2@1+ (1,0) [0|0] "" Vector__XXX
 SG_ PARK_rearSVACharID : 8|6@1+ (1,0) [0|0] "" Vector__XXX
 SG_ PARK_pscLeftCurbType : 14|2@1+ (1,0) [0|0] "" Vector__XXX
 SG_ PARK_autoCalComplete : 16|1@1+ (1,0) [0|0] "" Vector__XXX
 SG_ PARK_geometryType : 17|2@1+ (1,0) [0|0] "" Vector__XXX
 SG_ PARK_tireFitment : 19|2@1+ (1,0) [0|0] "" Vector__XXX
 SG_ PARK_rackDetected : 21|2@1+ (1,0) [0|0] "" Vector__XXX
 SG_ PARK_sdiActive : 24|1@1+ (1,0) [0|0] "" Vector__XXX
 SG_ PARK_sdiNoise : 25|2@1+ (1,0) [0|0] "" Vector__XXX
 SG_ PARK_sdiBlindSpotRight : 27|2@1+ (1,0) [0|0] "" Vector__XXX
 SG_ PARK_sdiBlindSpotLeft : 29|2@1+ (1,0) [0|0] "" Vector__XXX
 SG_ PARK_sensorType : 32|2@1+ (1,0) [0|0] "" Vector__XXX
 SG_ PARK_status2Counter : 52|4@1+ (1,0) [0|0] "" Vector__XXX
 SG_ PARK_status2Checksum : 56|8@1+ (1,0) [0|0] "" Vector__XXX

BO_ 783 OCS1P_debugCushionMutCNTComp: 8 Vector__XXX
 SG_ OCS1P_cushionMutCNTFreqComp : 0|16@1+ (1,0) [0|0] "" Vector__XXX
 SG_ OCS1P_deltaFreqCushionMut : 32|16@1- (1,0) [0|0] "" Vector__XXX

BO_ 784 APS_warningMatrix4: 8 Vector__XXX
 SG_ APS_w257_assertFailure : 0|1@1+ (1,0) [0|0] "" Vector__XXX
 SG_ APS_w258_qspiFlashSectorChecksumMismatch : 1|1@1+ (1,0) [0|0] "" Vector__XXX
 SG_ APS_w259_qspiFailure : 2|1@1+ (1,0) [0|0] "" Vector__XXX
 SG_ APS_w260_pgoodFailure : 3|1@1+ (1,0) [0|0] "" Vector__XXX
 SG_ APS_w261_vrmFaultGrpA : 4|1@1+ (1,0) [0|0] "" Vector__XXX
 SG_ APS_w262_vrmFaultGrpB : 5|1@1+ (1,0) [0|0] "" Vector__XXX
 SG_ APS_w263_vrmFaultGrpC : 6|1@1+ (1,0) [0|0] "" Vector__XXX
 SG_ APS_w264_ddrPhy0Failures : 7|1@1+ (1,0) [0|0] "" Vector__XXX
 SG_ APS_w265_ddrPhy1Failures : 8|1@1+ (1,0) [0|0] "" Vector__XXX
 SG_ APS_w266_ddrPhy2Failures : 9|1@1+ (1,0) [0|0] "" Vector__XXX
 SG_ APS_w267_ddrPhy3Failures : 10|1@1+ (1,0) [0|0] "" Vector__XXX
 SG_ APS_w268_ddrControllerFailures : 11|1@1+ (1,0) [0|0] "" Vector__XXX
 SG_ APS_w269_ethSwitchRxPageCountTooHighPort0_3 : 12|1@1+ (1,0) [0|0] "" Vector__XXX
 SG_ APS_w270_ethSwitchRxPageCountTooHighPort4_7 : 13|1@1+ (1,0) [0|0] "" Vector__XXX
 SG_ APS_w271_ddrScheduler0EccErrors : 14|1@1+ (1,0) [0|0] "" Vector__XXX
 SG_ APS_w272_ddrScheduler1EccErrors : 15|1@1+ (1,0) [0|0] "" Vector__XXX
 SG_ APS_w273_ddrScheduler2EccErrors : 16|1@1+ (1,0) [0|0] "" Vector__XXX
 SG_ APS_w274_ddrScheduler3EccErrors : 17|1@1+ (1,0) [0|0] "" Vector__XXX
 SG_ APS_w275_ddrScheduler4EccErrors : 18|1@1+ (1,0) [0|0] "" Vector__XXX
 SG_ APS_w276_ddrScheduler5EccErrors : 19|1@1+ (1,0) [0|0] "" Vector__XXX
 SG_ APS_w277_ddrScheduler6EccErrors : 20|1@1+ (1,0) [0|0] "" Vector__XXX
 SG_ APS_w278_ddrScheduler7EccErrors : 21|1@1+ (1,0) [0|0] "" Vector__XXX
 SG_ APS_w279_ufsPartitionError : 22|1@1+ (1,0) [0|0] "" Vector__XXX
 SG_ APS_w280_pepsMia : 23|1@1+ (1,0) [0|0] "" Vector__XXX
 SG_ APS_w281_rsaMia : 24|1@1+ (1,0) [0|0] "" Vector__XXX
 SG_ APS_w282_smmuError : 25|1@1+ (1,0) [0|0] "" Vector__XXX
 SG_ APS_w283_psfaMia : 26|1@1+ (1,0) [0|0] "" Vector__XXX
 SG_ APS_w284_cam12VBuckBoostAPwrIssue : 27|1@1+ (1,0) [0|0] "" Vector__XXX
 SG_ APS_w285_cam12VBuckBoostBPwrIssue : 28|1@1+ (1,0) [0|0] "" Vector__XXX
 SG_ APS_w286_cam12VEFuseAPrimaryIssue : 29|1@1+ (1,0) [0|0] "" Vector__XXX
 SG_ APS_w287_cam12VEFuseASecondaryIssue : 30|1@1+ (1,0) [0|0] "" Vector__XXX
 SG_ APS_w288_brakeboosterMia : 31|1@1+ (1,0) [0|0] "" Vector__XXX
 SG_ APS_w289_turboTemperatureWarning : 32|1@1+ (1,0) [0|0] "" Vector__XXX
 SG_ APS_w290_cam12VBuckBoostBPwrRinging : 33|1@1+ (1,0) [0|0] "" Vector__XXX
 SG_ APS_w291_dataAbort : 34|1@1+ (1,0) [0|0] "" Vector__XXX
 SG_ APS_w292_epas3pMiaBdyBus : 35|1@1+ (1,0) [0|0] "" Vector__XXX

BO_ 785 EPAS3S_info: 8 Vector__XXX
 SG_ EPAS3S_infoIndex M : 0|8@1+ (1,0) [0|0] "" Vector__XXX
 SG_ EPAS3S_infoBootUdsProtoVersion m20 : 8|8@1+ (1,0) [0|0] "" Vector__XXX
 SG_ EPAS3S_infoBuildType m10 : 8|8@1+ (1,0) [0|0] "" Vector__XXX
 SG_ EPAS3S_infoPcbaID m11 : 16|8@1+ (1,0) [0|0] "" Vector__XXX
 SG_ EPAS3S_infoAssemblyID m11 : 24|8@1+ (1,0) [0|0] "" Vector__XXX
 SG_ EPAS3S_infoApplicationCRC m13 : 32|32@1+ (1,0) [0|0] "" Vector__XXX
 SG_ EPAS3S_infoBootloaderCRC m20 : 32|32@1+ (1,0) [0|0] "" Vector__XXX
 SG_ EPAS3S_infoSubcomponent2 m23 : 32|32@1+ (1,0) [0|0] "" Vector__XXX
 SG_ EPAS3S_infoUsageID m11 : 32|16@1+ (1,0) [0|0] "" Vector__XXX
 SG_ EPAS3S_infoComponentID m10 : 48|16@1+ (1,0) [0|0] "" Vector__XXX

BO_ 789 OCS1P_info: 8 Vector__XXX
 SG_ OCS1P_infoIndex M : 0|8@1+ (1,0) [0|0] "" Vector__XXX
 SG_ OCS1P_infoAppGitHashBytes m17 : 8|56@1+ (1,0) [0|0] "" Vector__XXX
 SG_ OCS1P_infoBootGitHashBytes m18 : 8|56@1+ (1,0) [0|0] "" Vector__XXX
 SG_ OCS1P_infoBootSvnRev m14 : 8|24@1+ (1,0) [0|0] "" Vector__XXX
 SG_ OCS1P_infoBootUdsProtoVersion m20 : 8|8@1+ (1,0) [0|0] "" Vector__XXX
 SG_ OCS1P_infoBuildType m10 : 8|8@1+ (1,0) [0|0] "" Vector__XXX
 SG_ OCS1P_infoPlatformType m19 : 8|8@1+ (1,0) [0|0] "" Vector__XXX
 SG_ OCS1P_infoBuildConfigID m10 : 16|16@1+ (1,0) [0|0] "" Vector__XXX
 SG_ OCS1P_infoPcbaID m11 : 16|8@1+ (1,0) [0|0] "" Vector__XXX
 SG_ OCS1P_infoAssemblyID m11 : 24|8@1+ (1,0) [0|0] "" Vector__XXX
 SG_ OCS1P_infoApplicationCRC m13 : 32|32@1+ (1,0) [0|0] "" Vector__XXX
 SG_ OCS1P_infoBootloaderCRC m20 : 32|32@1+ (1,0) [0|0] "" Vector__XXX
 SG_ OCS1P_infoHardwareID m10 : 32|16@1+ (1,0) [0|0] "" Vector__XXX
 SG_ OCS1P_infoUsageID m11 : 32|16@1+ (1,0) [0|0] "" Vector__XXX
 SG_ OCS1P_infoComponentID m10 : 48|16@1+ (1,0) [0|0] "" Vector__XXX
 SG_ OCS1P_infoSubUsageID m11 : 48|16@1+ (1,0) [0|0] "" Vector__XXX

BO_ 792 GTW_carState: 8 Vector__XXX
 SG_ GTW_tsYear : 0|7@1+ (1,2000) [0|0] "" Vector__XXX
 SG_ GTW_tsMonth : 8|4@1+ (1,0) [0|0] "" Vector__XXX
 SG_ GTW_tsSecond : 16|6@1+ (1,0) [0|0] "" Vector__XXX
 SG_ GTW_tsHour : 24|5@1+ (1,0) [0|0] "" Vector__XXX
 SG_ GTW_tsDay : 32|5@1+ (1,0) [0|0] "" Vector__XXX
 SG_ GTW_tsMinute : 40|6@1+ (1,0) [0|0] "" Vector__XXX
 SG_ GTW_apGoToFullPower : 47|1@1+ (1,0) [0|0] "" Vector__XXX
 SG_ GTW_factoryGated : 48|1@1+ (1,0) [0|0] "" Vector__XXX
 SG_ GTW_carStateCounter : 49|4@1+ (1,0) [0|0] "" Vector__XXX
 SG_ GTW_infohw : 53|2@1+ (1,0) [0|0] "" Vector__XXX
 SG_ GTW_carStateChecksum : 56|8@1+ (1,0) [0|0] "" Vector__XXX

BO_ 798 PARK_status: 8 Vector__XXX
 SG_ PARK_status : 0|2@1+ (1,0) [0|0] "" Vector__XXX
 SG_ PARK_serviceRequest : 2|2@1+ (1,0) [0|0] "" Vector__XXX
 SG_ PARK_systemDtcPresent : 4|2@1+ (1,0) [0|0] "" Vector__XXX
 SG_ PARK_statusCounter : 12|4@1+ (1,0) [0|0] "" Vector__XXX
 SG_ PARK_statusChecksum : 16|8@1+ (1,0) [0|0] "" Vector__XXX
 SG_ PARK_majorVersion : 24|8@1+ (1,0) [0|0] "" Vector__XXX
 SG_ PARK_minorVersion : 32|8@1+ (1,0) [0|0] "" Vector__XXX
 SG_ PARK_subMinorVersion : 40|8@1+ (1,0) [0|0] "" Vector__XXX

BO_ 799 TPMS_data: 8 Vector__XXX
 SG_ TPMS_pressureFL : 0|8@1+ (0.025,0) [0|0] "" Vector__XXX
 SG_ TPMS_temperatureFL : 8|8@1+ (1,-40) [0|0] "" Vector__XXX
 SG_ TPMS_pressureFR : 16|8@1+ (0.025,0) [0|0] "" Vector__XXX
 SG_ TPMS_temperatureFR : 24|8@1+ (1,-40) [0|0] "" Vector__XXX
 SG_ TPMS_pressureRL : 32|8@1+ (0.025,0) [0|0] "" Vector__XXX
 SG_ TPMS_temperatureRL : 40|8@1+ (1,-40) [0|0] "" Vector__XXX
 SG_ TPMS_pressureRR : 48|8@1+ (0.025,0) [0|0] "" Vector__XXX
 SG_ TPMS_temperatureRR : 56|8@1+ (1,-40) [0|0] "" Vector__XXX

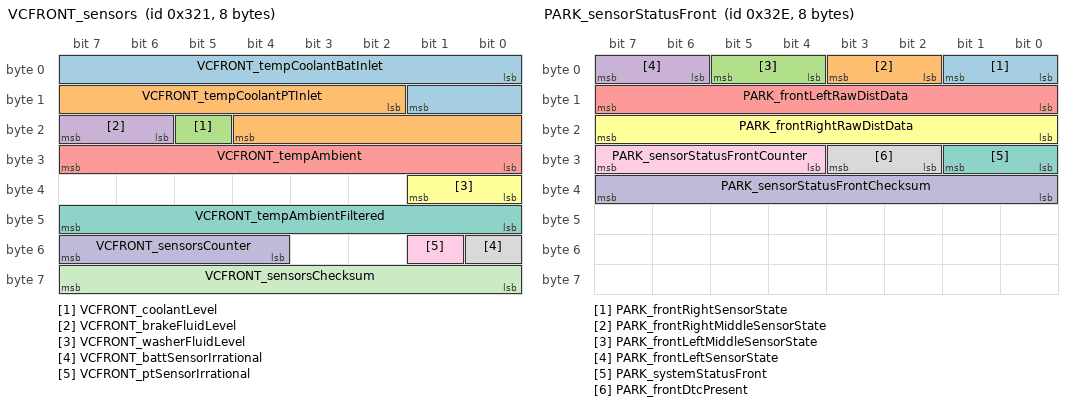
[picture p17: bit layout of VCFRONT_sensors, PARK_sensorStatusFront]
BO_ 801 VCFRONT_sensors: 8 Vector__XXX
 SG_ VCFRONT_tempCoolantBatInlet : 0|10@1+ (0.125,-40) [0|0] "" Vector__XXX
 SG_ VCFRONT_tempCoolantPTInlet : 10|11@1+ (0.125,-40) [0|0] "" Vector__XXX
 SG_ VCFRONT_coolantLevel : 21|1@1+ (1,0) [0|0] "" Vector__XXX
 SG_ VCFRONT_brakeFluidLevel : 22|2@1+ (1,0) [0|0] "" Vector__XXX
 SG_ VCFRONT_tempAmbient : 24|8@1+ (0.5,-40) [0|0] "" Vector__XXX
 SG_ VCFRONT_washerFluidLevel : 32|2@1+ (1,0) [0|0] "" Vector__XXX
 SG_ VCFRONT_tempAmbientFiltered : 40|8@1+ (0.5,-40) [0|0] "" Vector__XXX
 SG_ VCFRONT_battSensorIrrational : 48|1@1+ (1,0) [0|0] "" Vector__XXX
 SG_ VCFRONT_ptSensorIrrational : 49|1@1+ (1,0) [0|0] "" Vector__XXX
 SG_ VCFRONT_sensorsCounter : 52|4@1+ (1,0) [0|0] "" Vector__XXX
 SG_ VCFRONT_sensorsChecksum : 56|8@1+ (1,0) [0|0] "" Vector__XXX

BO_ 803 USM_CPULoad: 8 Vector__XXX
 SG_ USM_CPULoadTotal : 0|8@1+ (1,0) [0|0] "" Vector__XXX
 SG_ USM_CPULoad1msTask : 8|8@1+ (1,0) [0|0] "" Vector__XXX
 SG_ USM_CPULoad10msTask : 16|8@1+ (1,0) [0|0] "" Vector__XXX
 SG_ USM_CPULoad100msTask : 24|8@1+ (1,0) [0|0] "" Vector__XXX
 SG_ USM_CPULoad1000msTask : 32|8@1+ (1,0) [0|0] "" Vector__XXX

BO_ 805 ESP_info: 8 Vector__XXX
 SG_ ESP_infoIndex M : 0|8@1+ (1,0) [0|0] "" Vector__XXX
 SG_ ESP_infoBootUdsProtoVersion m20 : 8|8@1+ (1,0) [0|0] "" Vector__XXX
 SG_ ESP_infoBuildType m10 : 8|8@1+ (1,0) [0|0] "" Vector__XXX
 SG_ ESP_infoPcbaID m11 : 16|8@1+ (1,0) [0|0] "" Vector__XXX
 SG_ ESP_infoVehicleVariant m16 : 16|8@1+ (1,0) [0|0] "" Vector__XXX
 SG_ ESP_infoAssemblyID m11 : 24|8@1+ (1,0) [0|0] "" Vector__XXX
 SG_ ESP_vehFlashMode m10 : 24|1@1+ (1,0) [0|0] "" Vector__XXX
 SG_ ESP_infoBootloaderCRC m20 : 32|32@1+ (1,0) [0|0] "" Vector__XXX
 SG_ ESP_infoSubcomponent1 m16 : 32|32@1+ (1,0) [0|0] "" Vector__XXX
 SG_ ESP_infoUsageID m11 : 32|16@1+ (1,0) [0|0] "" Vector__XXX
 SG_ ESP_infoApplicationCRC m13 : 39|32@0+ (1,0) [0|0] "" Vector__XXX
 SG_ ESP_infoVariantCRC m22 : 39|32@0+ (1,0) [0|0] "" Vector__XXX
 SG_ ESP_infoComponentID m10 : 48|16@1+ (1,0) [0|0] "" Vector__XXX
 SG_ ESP_infoSubUsageID m11 : 48|16@1+ (1,0) [0|0] "" Vector__XXX

BO_ 806 PARK_info: 8 Vector__XXX
 SG_ PARK_infoIndex M : 0|8@1+ (1,0) [0|0] "" Vector__XXX
 SG_ PARK_infoBootUdsProtoVersion m20 : 8|8@1+ (1,0) [0|0] "" Vector__XXX
 SG_ PARK_infoBuildType m10 : 8|8@1+ (1,0) [0|0] "" Vector__XXX
 SG_ PARK_infoPcbaID m11 : 16|8@1+ (1,0) [0|0] "" Vector__XXX
 SG_ PARK_infoAssemblyID m11 : 24|8@1+ (1,0) [0|0] "" Vector__XXX
 SG_ PARK_infoApplicationCRC m13 : 32|32@1+ (1,0) [0|0] "" Vector__XXX
 SG_ PARK_infoBootloaderCRC m20 : 32|32@1+ (1,0) [0|0] "" Vector__XXX
 SG_ PARK_infoUsageID m11 : 32|16@1+ (1,0) [0|0] "" Vector__XXX
 SG_ PARK_infoComponentID m10 : 48|16@1+ (1,0) [0|0] "" Vector__XXX

BO_ 807 USM_info: 8 Vector__XXX
 SG_ USM_infoIndex M : 0|8@1+ (1,0) [0|0] "" Vector__XXX
 SG_ USM_infoAppCrc m13 : 8|32@1+ (1,0) [0|0] "" Vector__XXX
 SG_ USM_infoAppGitHash m17 : 8|56@1+ (1,0) [0|0] "" Vector__XXX
 SG_ USM_infoBootGitHash m18 : 8|56@1+ (1,0) [0|0] "" Vector__XXX
 SG_ USM_infoBootUdsProtoVersion m20 : 8|16@1+ (1,0) [0|0] "" Vector__XXX
 SG_ USM_infoBuildType m10 : 8|3@1+ (1,0) [0|0] "" Vector__XXX
 SG_ USM_infoPcbaId m11 : 8|8@1+ (1,0) [0|0] "" Vector__XXX
 SG_ USM_infoPlatformType m19 : 8|8@1+ (1,0) [0|0] "" Vector__XXX
 SG_ USM_infoAssemblyId m11 : 16|8@1+ (1,0) [0|0] "" Vector__XXX
 SG_ USM_infoBuildConfigId m10 : 16|16@1+ (1,0) [0|0] "" Vector__XXX
 SG_ USM_infoBootCrc m20 : 24|32@1+ (1,0) [0|0] "" Vector__XXX
 SG_ USM_infoUsageId m11 : 24|16@1+ (1,0) [0|0] "" Vector__XXX
 SG_ USM_infoHardwareId m10 : 32|16@1+ (1,0) [0|0] "" Vector__XXX
 SG_ USM_infoSubcomponent1 m16 : 32|32@1+ (1,0) [0|0] "" Vector__XXX
 SG_ USM_infoSubUsageId m11 : 40|16@1+ (1,0) [0|0] "" Vector__XXX
 SG_ USM_infoComponentId m10 : 48|16@1+ (1,0) [0|0] "" Vector__XXX

BO_ 809 APP_warningMatrix0: 8 Vector__XXX
 SG_ APP_w001_DEPRECATED : 0|1@1+ (1,0) [0|0] "" Vector__XXX
 SG_ APP_w002_ldwDisabled : 1|1@1+ (1,0) [0|0] "" Vector__XXX
 SG_ APP_w003_isaDisabled : 2|1@1+ (1,0) [0|0] "" Vector__XXX
 SG_ APP_w004_accDisabled : 3|1@1+ (1,0) [0|0] "" Vector__XXX
 SG_ APP_w005_fcwCancelled : 4|1@1+ (1,0) [0|0] "" Vector__XXX
 SG_ APP_w006_aebCancelled : 5|1@1+ (1,0) [0|0] "" Vector__XXX
 SG_ APP_w007_ahlbDisabled : 6|1@1+ (1,0) [0|0] "" Vector__XXX
 SG_ APP_w008_parkDisabled : 7|1@1+ (1,0) [0|0] "" Vector__XXX
 SG_ APP_w009_aebFault : 8|1@1+ (1,0) [0|0] "" Vector__XXX
 SG_ APP_w010_radcCalibIssue : 9|1@1+ (1,0) [0|0] "" Vector__XXX
 SG_ APP_w011_scaEvent : 10|1@1+ (1,0) [0|0] "" Vector__XXX
 SG_ APP_w012_Cam_BootFailure : 11|1@1+ (1,0) [0|0] "" Vector__XXX
 SG_ APP_w013_Cam_Watchdog : 12|1@1+ (1,0) [0|0] "" Vector__XXX
 SG_ APP_w014_swAssert : 13|1@1+ (1,0) [0|0] "" Vector__XXX
 SG_ APP_w015_Camera_Failsafes : 14|1@1+ (1,0) [0|0] "" Vector__XXX
 SG_ APP_w016_aeb_e_event : 15|1@1+ (1,0) [0|0] "" Vector__XXX
 SG_ APP_w017_Cam_Msg_MIA : 16|1@1+ (1,0) [0|0] "" Vector__XXX
 SG_ APP_w018_ECU_Power_Issue : 17|1@1+ (1,0) [0|0] "" Vector__XXX
 SG_ APP_w019_ECU_Stack_Overflow : 18|1@1+ (1,0) [0|0] "" Vector__XXX
 SG_ APP_w020_ECU_checkstopError : 19|1@1+ (1,0) [0|0] "" Vector__XXX
 SG_ APP_w021_ECU_Temperature_Issue : 20|1@1+ (1,0) [0|0] "" Vector__XXX
 SG_ APP_w022_ECU_EEPROM_Failure : 21|1@1+ (1,0) [0|0] "" Vector__XXX
 SG_ APP_w023_ECU_Cam_Statemismatc : 22|1@1+ (1,0) [0|0] "" Vector__XXX
 SG_ APP_w024_ECU_Watchdog_Reset : 23|1@1+ (1,0) [0|0] "" Vector__XXX
 SG_ APP_w025_LC_Steering_Override : 24|1@1+ (1,0) [0|0] "" Vector__XXX
 SG_ APP_w026_ECU_timingIssue : 25|1@1+ (1,0) [0|0] "" Vector__XXX
 SG_ APP_w027_ECU_Reset_Fault : 26|1@1+ (1,0) [0|0] "" Vector__XXX
 SG_ APP_w028_spi_rx_error : 27|1@1+ (1,0) [0|0] "" Vector__XXX
 SG_ APP_w029_spi_tx_error : 28|1@1+ (1,0) [0|0] "" Vector__XXX
 SG_ APP_w030_Heater_Issue : 29|1@1+ (1,0) [0|0] "" Vector__XXX
 SG_ APP_w031_canRxError : 30|1@1+ (1,0) [0|0] "" Vector__XXX
 SG_ APP_w032_canTxError : 31|1@1+ (1,0) [0|0] "" Vector__XXX
 SG_ APP_w033_gtwMia : 32|1@1+ (1,0) [0|0] "" Vector__XXX
 SG_ APP_w034_sccmMia : 33|1@1+ (1,0) [0|0] "" Vector__XXX
 SG_ APP_w035_espMia : 34|1@1+ (1,0) [0|0] "" Vector__XXX
 SG_ APP_w036_bdyMia : 35|1@1+ (1,0) [0|0] "" Vector__XXX
 SG_ APP_w037_camTacIssue : 36|1@1+ (1,0) [0|0] "" Vector__XXX
 SG_ APP_w038_camFailure : 37|1@1+ (1,0) [0|0] "" Vector__XXX
 SG_ APP_w039_sdm_rcm_Mia : 38|1@1+ (1,0) [0|0] "" Vector__XXX
 SG_ APP_w040_autopilotAngleSaturated : 39|1@1+ (1,0) [0|0] "" Vector__XXX
 SG_ APP_w041_autopilotRateSaturated : 40|1@1+ (1,0) [0|0] "" Vector__XXX
 SG_ APP_w042_autopilotAborting : 41|1@1+ (1,0) [0|0] "" Vector__XXX
 SG_ APP_w043_camLongRunTime : 42|1@1+ (1,0) [0|0] "" Vector__XXX
 SG_ APP_w044_appMobileyeFailure : 43|1@1+ (1,0) [0|0] "" Vector__XXX
 SG_ APP_w045_radMia : 44|1@1+ (1,0) [0|0] "" Vector__XXX
 SG_ APP_w046_eepromRecordAbsent : 45|1@1+ (1,0) [0|0] "" Vector__XXX
 SG_ APP_w047_edrEvent : 46|1@1+ (1,0) [0|0] "" Vector__XXX
 SG_ APP_w048_APP_Features_Disabled : 47|1@1+ (1,0) [0|0] "" Vector__XXX
 SG_ APP_w049_eyeqVersionMismatch : 48|1@1+ (1,0) [0|0] "" Vector__XXX
 SG_ APP_w050_aeb_event : 49|1@1+ (1,0) [0|0] "" Vector__XXX
 SG_ APP_w051_radcEcuIssue : 50|1@1+ (1,0) [0|0] "" Vector__XXX
 SG_ APP_w052_radcSensorIssue : 51|1@1+ (1,0) [0|0] "" Vector__XXX
 SG_ APP_w053_radcCommIssue : 52|1@1+ (1,0) [0|0] "" Vector__XXX
 SG_ APP_w054_camAutofix : 53|1@1+ (1,0) [0|0] "" Vector__XXX
 SG_ APP_w055_radcVersionMismatch : 54|1@1+ (1,0) [0|0] "" Vector__XXX
 SG_ APP_w056_diMia : 55|1@1+ (1,0) [0|0] "" Vector__XXX
 SG_ APP_w057_mcuMia : 56|1@1+ (1,0) [0|0] "" Vector__XXX
 SG_ APP_w058_epbMia : 57|1@1+ (1,0) [0|0] "" Vector__XXX
 SG_ APP_w059_parkMia : 58|1@1+ (1,0) [0|0] "" Vector__XXX
 SG_ APP_w060_fcw_event : 59|1@1+ (1,0) [0|0] "" Vector__XXX
 SG_ APP_w061_airSuspensionMia : 60|1@1+ (1,0) [0|0] "" Vector__XXX
 SG_ APP_w062_radcAlignment : 61|1@1+ (1,0) [0|0] "" Vector__XXX
 SG_ APP_w063_parkVersionMismatch : 62|1@1+ (1,0) [0|0] "" Vector__XXX
 SG_ APP_w064_epasMia : 63|1@1+ (1,0) [0|0] "" Vector__XXX

BO_ 810 DAS_warningMatrix0: 8 Vector__XXX
 SG_ DAS_w002_ldwDisabled : 1|1@1+ (1,0) [0|0] "" Vector__XXX
 SG_ DAS_w003_isaDisabled : 2|1@1+ (1,0) [0|0] "" Vector__XXX
 SG_ DAS_w004_accDisabled : 3|1@1+ (1,0) [0|0] "" Vector__XXX
 SG_ DAS_w005_fcwCancelled : 4|1@1+ (1,0) [0|0] "" Vector__XXX
 SG_ DAS_w006_aebCancelled : 5|1@1+ (1,0) [0|0] "" Vector__XXX
 SG_ DAS_w007_ahlbDisabled : 6|1@1+ (1,0) [0|0] "" Vector__XXX
 SG_ DAS_w008_parkDisabled : 7|1@1+ (1,0) [0|0] "" Vector__XXX
 SG_ DAS_w009_aebFault : 8|1@1+ (1,0) [0|0] "" Vector__XXX
 SG_ DAS_w010_radcCalibIssue : 9|1@1+ (1,0) [0|0] "" Vector__XXX
 SG_ DAS_w011_scaEvent : 10|1@1+ (1,0) [0|0] "" Vector__XXX
 SG_ DAS_w012_Cam_BootFailure : 11|1@1+ (1,0) [0|0] "" Vector__XXX
 SG_ DAS_w013_Cam_Watchdog : 12|1@1+ (1,0) [0|0] "" Vector__XXX
 SG_ DAS_w014_swAssert : 13|1@1+ (1,0) [0|0] "" Vector__XXX
 SG_ DAS_w015_Camera_Failsafes : 14|1@1+ (1,0) [0|0] "" Vector__XXX
 SG_ DAS_w016_aeb_e_event : 15|1@1+ (1,0) [0|0] "" Vector__XXX
 SG_ DAS_w017_Cam_Msg_MIA : 16|1@1+ (1,0) [0|0] "" Vector__XXX
 SG_ DAS_w018_ECU_Power_Issue : 17|1@1+ (1,0) [0|0] "" Vector__XXX
 SG_ DAS_w019_ECU_Stack_Overflow : 18|1@1+ (1,0) [0|0] "" Vector__XXX
 SG_ DAS_w020_ECU_checkstopError : 19|1@1+ (1,0) [0|0] "" Vector__XXX
 SG_ DAS_w021_ECU_Temperature_Issue : 20|1@1+ (1,0) [0|0] "" Vector__XXX
 SG_ DAS_w022_ECU_EEPROM_Failure : 21|1@1+ (1,0) [0|0] "" Vector__XXX
 SG_ DAS_w023_ECU_Cam_Statemismatc : 22|1@1+ (1,0) [0|0] "" Vector__XXX
 SG_ DAS_w024_ECU_Watchdog_Reset : 23|1@1+ (1,0) [0|0] "" Vector__XXX
 SG_ DAS_w025_LC_Steering_Override : 24|1@1+ (1,0) [0|0] "" Vector__XXX
 SG_ DAS_w026_ECU_timingIssue : 25|1@1+ (1,0) [0|0] "" Vector__XXX
 SG_ DAS_w027_ECU_Reset_Fault : 26|1@1+ (1,0) [0|0] "" Vector__XXX
 SG_ DAS_w028_spi_rx_error : 27|1@1+ (1,0) [0|0] "" Vector__XXX
 SG_ DAS_w029_spi_tx_error : 28|1@1+ (1,0) [0|0] "" Vector__XXX
 SG_ DAS_w030_Heater_Issue : 29|1@1+ (1,0) [0|0] "" Vector__XXX
 SG_ DAS_w031_canRxError : 30|1@1+ (1,0) [0|0] "" Vector__XXX
 SG_ DAS_w032_canTxError : 31|1@1+ (1,0) [0|0] "" Vector__XXX
 SG_ DAS_w033_gtwMia : 32|1@1+ (1,0) [0|0] "" Vector__XXX
 SG_ DAS_w034_sccmMia : 33|1@1+ (1,0) [0|0] "" Vector__XXX
 SG_ DAS_w035_espMia : 34|1@1+ (1,0) [0|0] "" Vector__XXX
 SG_ DAS_w036_bdyMia : 35|1@1+ (1,0) [0|0] "" Vector__XXX
 SG_ DAS_w037_camTacIssue : 36|1@1+ (1,0) [0|0] "" Vector__XXX
 SG_ DAS_w038_camFailure : 37|1@1+ (1,0) [0|0] "" Vector__XXX
 SG_ DAS_w039_sdm_rcm_Mia : 38|1@1+ (1,0) [0|0] "" Vector__XXX
 SG_ DAS_w040_autopilotAngleSaturated : 39|1@1+ (1,0) [0|0] "" Vector__XXX
 SG_ DAS_w041_autopilotRateSaturated : 40|1@1+ (1,0) [0|0] "" Vector__XXX
 SG_ DAS_w042_autopilotAborting : 41|1@1+ (1,0) [0|0] "" Vector__XXX
 SG_ DAS_w043_camLongRunTime : 42|1@1+ (1,0) [0|0] "" Vector__XXX
 SG_ DAS_w044_appMobileyeFailure : 43|1@1+ (1,0) [0|0] "" Vector__XXX
 SG_ DAS_w045_radMia : 44|1@1+ (1,0) [0|0] "" Vector__XXX
 SG_ DAS_w046_eepromRecordAbsent : 45|1@1+ (1,0) [0|0] "" Vector__XXX
 SG_ DAS_w047_edrEvent : 46|1@1+ (1,0) [0|0] "" Vector__XXX
 SG_ DAS_w048_DAS_Features_Disabled : 47|1@1+ (1,0) [0|0] "" Vector__XXX
 SG_ DAS_w049_eyeqVersionMismatch : 48|1@1+ (1,0) [0|0] "" Vector__XXX
 SG_ DAS_w050_aeb_event : 49|1@1+ (1,0) [0|0] "" Vector__XXX
 SG_ DAS_w051_radcEcuIssue : 50|1@1+ (1,0) [0|0] "" Vector__XXX
 SG_ DAS_w052_radcSensorIssue : 51|1@1+ (1,0) [0|0] "" Vector__XXX
 SG_ DAS_w053_radcCommIssue : 52|1@1+ (1,0) [0|0] "" Vector__XXX
 SG_ DAS_w054_camAutofix : 53|1@1+ (1,0) [0|0] "" Vector__XXX
 SG_ DAS_w055_radcVersionMismatch : 54|1@1+ (1,0) [0|0] "" Vector__XXX
 SG_ DAS_w056_diMia : 55|1@1+ (1,0) [0|0] "" Vector__XXX
 SG_ DAS_w057_mcuMia : 56|1@1+ (1,0) [0|0] "" Vector__XXX
 SG_ DAS_w058_epbMia : 57|1@1+ (1,0) [0|0] "" Vector__XXX
 SG_ DAS_w059_parkMia : 58|1@1+ (1,0) [0|0] "" Vector__XXX
 SG_ DAS_w060_fcw_event : 59|1@1+ (1,0) [0|0] "" Vector__XXX
 SG_ DAS_w061_airSuspensionMia : 60|1@1+ (1,0) [0|0] "" Vector__XXX
 SG_ DAS_w062_radcAlignment : 61|1@1+ (1,0) [0|0] "" Vector__XXX
 SG_ DAS_w063_parkVersionMismatch : 62|1@1+ (1,0) [0|0] "" Vector__XXX
 SG_ DAS_w064_epasMia : 63|1@1+ (1,0) [0|0] "" Vector__XXX

BO_ 811 APS_warningMatrix0: 8 Vector__XXX
 SG_ APS_w001_DEPRECATED : 0|1@1+ (1,0) [0|0] "" Vector__XXX
 SG_ APS_w002_ldwDisabled : 1|1@1+ (1,0) [0|0] "" Vector__XXX
 SG_ APS_w003_isaDisabled : 2|1@1+ (1,0) [0|0] "" Vector__XXX
 SG_ APS_w004_accDisabled : 3|1@1+ (1,0) [0|0] "" Vector__XXX
 SG_ APS_w005_fcwCancelled : 4|1@1+ (1,0) [0|0] "" Vector__XXX
 SG_ APS_w006_aebCancelled : 5|1@1+ (1,0) [0|0] "" Vector__XXX
 SG_ APS_w007_ahlbDisabled : 6|1@1+ (1,0) [0|0] "" Vector__XXX
 SG_ APS_w008_parkDisabled : 7|1@1+ (1,0) [0|0] "" Vector__XXX
 SG_ APS_w009_aebFault : 8|1@1+ (1,0) [0|0] "" Vector__XXX
 SG_ APS_w010_radcCalibIssue : 9|1@1+ (1,0) [0|0] "" Vector__XXX
 SG_ APS_w011_scaEvent : 10|1@1+ (1,0) [0|0] "" Vector__XXX
 SG_ APS_w012_Cam_BootFailure : 11|1@1+ (1,0) [0|0] "" Vector__XXX
 SG_ APS_w013_Cam_Watchdog : 12|1@1+ (1,0) [0|0] "" Vector__XXX
 SG_ APS_w014_swAssert : 13|1@1+ (1,0) [0|0] "" Vector__XXX
 SG_ APS_w015_Camera_Failsafes : 14|1@1+ (1,0) [0|0] "" Vector__XXX
 SG_ APS_w016_aeb_e_event : 15|1@1+ (1,0) [0|0] "" Vector__XXX
 SG_ APS_w017_Cam_Msg_MIA : 16|1@1+ (1,0) [0|0] "" Vector__XXX
 SG_ APS_w018_ECU_Power_Issue : 17|1@1+ (1,0) [0|0] "" Vector__XXX
 SG_ APS_w019_ECU_Stack_Overflow : 18|1@1+ (1,0) [0|0] "" Vector__XXX
 SG_ APS_w020_ECU_checkstopError : 19|1@1+ (1,0) [0|0] "" Vector__XXX
 SG_ APS_w021_ECU_Temperature_Issue : 20|1@1+ (1,0) [0|0] "" Vector__XXX
 SG_ APS_w022_ECU_EEPROM_Failure : 21|1@1+ (1,0) [0|0] "" Vector__XXX
 SG_ APS_w023_ECU_Cam_Statemismatc : 22|1@1+ (1,0) [0|0] "" Vector__XXX
 SG_ APS_w024_ECU_Watchdog_Reset : 23|1@1+ (1,0) [0|0] "" Vector__XXX
 SG_ APS_w025_LC_Steering_Override : 24|1@1+ (1,0) [0|0] "" Vector__XXX
 SG_ APS_w026_ECU_timingIssue : 25|1@1+ (1,0) [0|0] "" Vector__XXX
 SG_ APS_w027_ECU_Reset_Fault : 26|1@1+ (1,0) [0|0] "" Vector__XXX
 SG_ APS_w028_spi_rx_error : 27|1@1+ (1,0) [0|0] "" Vector__XXX
 SG_ APS_w029_spi_tx_error : 28|1@1+ (1,0) [0|0] "" Vector__XXX
 SG_ APS_w030_Heater_Issue : 29|1@1+ (1,0) [0|0] "" Vector__XXX
 SG_ APS_w031_canRxError : 30|1@1+ (1,0) [0|0] "" Vector__XXX
 SG_ APS_w032_canTxError : 31|1@1+ (1,0) [0|0] "" Vector__XXX
 SG_ APS_w033_gtwMia : 32|1@1+ (1,0) [0|0] "" Vector__XXX
 SG_ APS_w034_sccmMia : 33|1@1+ (1,0) [0|0] "" Vector__XXX
 SG_ APS_w035_espMia : 34|1@1+ (1,0) [0|0] "" Vector__XXX
 SG_ APS_w036_bdyMia : 35|1@1+ (1,0) [0|0] "" Vector__XXX
 SG_ APS_w037_camTacIssue : 36|1@1+ (1,0) [0|0] "" Vector__XXX
 SG_ APS_w038_camFailure : 37|1@1+ (1,0) [0|0] "" Vector__XXX
 SG_ APS_w039_sdm_rcm_Mia : 38|1@1+ (1,0) [0|0] "" Vector__XXX
 SG_ APS_w040_autopilotAngleSaturated : 39|1@1+ (1,0) [0|0] "" Vector__XXX
 SG_ APS_w041_autopilotRateSaturated : 40|1@1+ (1,0) [0|0] "" Vector__XXX
 SG_ APS_w042_autopilotAborting : 41|1@1+ (1,0) [0|0] "" Vector__XXX
 SG_ APS_w043_camLongRunTime : 42|1@1+ (1,0) [0|0] "" Vector__XXX
 SG_ APS_w044_appMobileyeFailure : 43|1@1+ (1,0) [0|0] "" Vector__XXX
 SG_ APS_w045_radMia : 44|1@1+ (1,0) [0|0] "" Vector__XXX
 SG_ APS_w046_eepromRecordAbsent : 45|1@1+ (1,0) [0|0] "" Vector__XXX
 SG_ APS_w047_edrEvent : 46|1@1+ (1,0) [0|0] "" Vector__XXX
 SG_ APS_w048_DAS_Features_Disabled : 47|1@1+ (1,0) [0|0] "" Vector__XXX
 SG_ APS_w049_eyeqVersionMismatch : 48|1@1+ (1,0) [0|0] "" Vector__XXX
 SG_ APS_w050_aeb_event : 49|1@1+ (1,0) [0|0] "" Vector__XXX
 SG_ APS_w051_radcEcuIssue : 50|1@1+ (1,0) [0|0] "" Vector__XXX
 SG_ APS_w052_radcSensorIssue : 51|1@1+ (1,0) [0|0] "" Vector__XXX
 SG_ APS_w053_radcCommIssue : 52|1@1+ (1,0) [0|0] "" Vector__XXX
 SG_ APS_w054_camAutofix : 53|1@1+ (1,0) [0|0] "" Vector__XXX
 SG_ APS_w055_radcVersionMismatch : 54|1@1+ (1,0) [0|0] "" Vector__XXX
 SG_ APS_w056_diMia : 55|1@1+ (1,0) [0|0] "" Vector__XXX
 SG_ APS_w057_mcuMia : 56|1@1+ (1,0) [0|0] "" Vector__XXX
 SG_ APS_w058_epbMia : 57|1@1+ (1,0) [0|0] "" Vector__XXX
 SG_ APS_w059_parkMia : 58|1@1+ (1,0) [0|0] "" Vector__XXX
 SG_ APS_w060_fcw_event : 59|1@1+ (1,0) [0|0] "" Vector__XXX
 SG_ APS_w061_tasMia : 60|1@1+ (1,0) [0|0] "" Vector__XXX
 SG_ APS_w062_radcAlignment : 61|1@1+ (1,0) [0|0] "" Vector__XXX
 SG_ APS_w063_parkVersionMismatch : 62|1@1+ (1,0) [0|0] "" Vector__XXX
 SG_ APS_w064_epasMia : 63|1@1+ (1,0) [0|0] "" Vector__XXX

BO_ 813 IBST_info: 8 Vector__XXX
 SG_ IBST_infoIndex M : 0|8@1+ (1,0) [0|0] "" Vector__XXX
 SG_ IBST_infoBootUdsProtoVersion m20 : 8|8@1+ (1,0) [0|0] "" Vector__XXX
 SG_ IBST_infoBuildType m10 : 8|8@1+ (1,0) [0|0] "" Vector__XXX
 SG_ IBST_infoPcbaID m11 : 16|8@1+ (1,0) [0|0] "" Vector__XXX
 SG_ IBST_infoAssemblyID m11 : 24|8@1+ (1,0) [0|0] "" Vector__XXX
 SG_ IBST_infoApplicationCRC m13 : 32|32@1+ (1,0) [0|0] "" Vector__XXX
 SG_ IBST_infoBootloaderCRC m20 : 32|32@1+ (1,0) [0|0] "" Vector__XXX
 SG_ IBST_infoSubcomponent1 m16 : 32|32@1+ (1,0) [0|0] "" Vector__XXX
 SG_ IBST_infoUsageID m11 : 32|16@1+ (1,0) [0|0] "" Vector__XXX
 SG_ IBST_infoVariantCRC m22 : 32|32@1+ (1,0) [0|0] "" Vector__XXX
 SG_ IBST_infoSubUsageID m11 : 48|16@1+ (1,0) [0|0] "" Vector__XXX
 SG_ IBST_infoComponentID m10 : 55|16@0+ (1,0) [0|0] "" Vector__XXX

BO_ 814 PARK_sensorStatusFront: 8 Vector__XXX
 SG_ PARK_frontRightSensorState : 0|2@1+ (1,0) [0|0] "" Vector__XXX
 SG_ PARK_frontRightMiddleSensorState : 2|2@1+ (1,0) [0|0] "" Vector__XXX
 SG_ PARK_frontLeftMiddleSensorState : 4|2@1+ (1,0) [0|0] "" Vector__XXX
 SG_ PARK_frontLeftSensorState : 6|2@1+ (1,0) [0|0] "" Vector__XXX
 SG_ PARK_frontLeftRawDistData : 8|8@1+ (1,0) [0|0] "" Vector__XXX
 SG_ PARK_frontRightRawDistData : 16|8@1+ (1,0) [0|0] "" Vector__XXX
 SG_ PARK_systemStatusFront : 24|2@1+ (1,0) [0|0] "" Vector__XXX
 SG_ PARK_frontDtcPresent : 26|2@1+ (1,0) [0|0] "" Vector__XXX
 SG_ PARK_sensorStatusFrontCounter : 28|4@1+ (1,0) [0|0] "" Vector__XXX
 SG_ PARK_sensorStatusFrontChecksum : 32|8@1+ (1,0) [0|0] "" Vector__XXX

BO_ 815 OCS1P_debugSelfDuty: 8 Vector__XXX
 SG_ OCS1P_cushionSelfDutyMean : 0|10@1+ (0.09775171065493646,0) [0|0] "" Vector__XXX
 SG_ OCS1P_cushionSelfDutyMin : 10|10@1+ (0.09775171065493646,0) [0|0] "" Vector__XXX
 SG_ OCS1P_cushionSelfDutyMax : 20|10@1+ (0.09775171065493646,0) [0|0] "" Vector__XXX
 SG_ OCS1P_seatbackSelfDutyMean : 30|10@1+ (0.09775171065493646,0) [0|0] "" Vector__XXX
 SG_ OCS1P_seatbackSelfDutyMin : 40|10@1+ (0.09775171065493646,0) [0|0] "" Vector__XXX
 SG_ OCS1P_seatbackSelfDutyMax : 50|10@1+ (0.09775171065493646,0) [0|0] "" Vector__XXX

BO_ 817 DAS_autopilotConfig: 8 Vector__XXX
 SG_ DAS_autopilot : 0|3@1+ (1,0) [0|0] "" Vector__XXX
 SG_ DAS_autopilotBase : 3|3@1+ (1,0) [0|0] "" Vector__XXX
 SG_ DAS_autopilotOverrideState : 8|4@1+ (1,0) [0|0] "" Vector__XXX
 SG_ DAS_autopilotOverride : 12|3@1+ (1,0) [0|0] "" Vector__XXX
 SG_ DAS_autopilotOverrideExpireTime : 16|32@1+ (1,0) [0|0] "" Vector__XXX

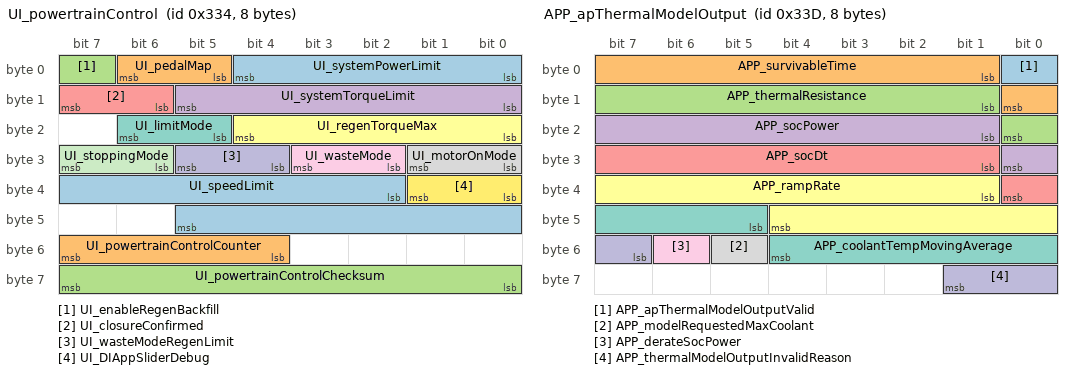
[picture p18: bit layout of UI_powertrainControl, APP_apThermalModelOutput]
BO_ 820 UI_powertrainControl: 8 Vector__XXX
 SG_ UI_systemPowerLimit : 0|5@1+ (20,20) [0|0] "" Vector__XXX
 SG_ UI_pedalMap : 5|2@1+ (1,0) [0|0] "" Vector__XXX
 SG_ UI_enableRegenBackfill : 7|1@1+ (1,0) [0|0] "" Vector__XXX
 SG_ UI_systemTorqueLimit : 8|6@1+ (150,1000) [0|0] "" Vector__XXX
 SG_ UI_closureConfirmed : 14|2@1+ (1,0) [0|0] "" Vector__XXX
 SG_ UI_regenTorqueMax : 16|5@1+ (5,0) [0|0] "" Vector__XXX
 SG_ UI_limitMode : 21|2@1+ (1,0) [0|0] "" Vector__XXX
 SG_ UI_motorOnMode : 24|2@1+ (1,0) [0|0] "" Vector__XXX
 SG_ UI_wasteMode : 26|2@1+ (1,0) [0|0] "" Vector__XXX
 SG_ UI_wasteModeRegenLimit : 28|2@1+ (1,0) [0|0] "" Vector__XXX
 SG_ UI_stoppingMode : 30|2@1+ (1,0) [0|0] "" Vector__XXX
 SG_ UI_DIAppSliderDebug : 32|2@1+ (1,0) [0|0] "" Vector__XXX
 SG_ UI_speedLimit : 34|12@1+ (0.1,0) [0|0] "" Vector__XXX
 SG_ UI_powertrainControlCounter : 52|4@1+ (1,0) [0|0] "" Vector__XXX
 SG_ UI_powertrainControlChecksum : 56|8@1+ (1,0) [0|0] "" Vector__XXX

BO_ 829 APP_apThermalModelOutput: 8 Vector__XXX
 SG_ APP_apThermalModelOutputValid : 0|1@1+ (1,0) [0|0] "" Vector__XXX
 SG_ APP_survivableTime : 1|8@1+ (0.1,0) [0|0] "" Vector__XXX
 SG_ APP_thermalResistance : 9|8@1+ (0.04,0) [0|0] "" Vector__XXX
 SG_ APP_socPower : 17|8@1+ (0.4,0) [0|0] "" Vector__XXX
 SG_ APP_socDt : 25|8@1+ (0.3,0) [0|0] "" Vector__XXX
 SG_ APP_rampRate : 33|12@1- (0.01,0) [0|0] "" Vector__XXX
 SG_ APP_coolantTempMovingAverage : 45|8@1- (0.5,30) [0|0] "" Vector__XXX
 SG_ APP_modelRequestedMaxCoolant : 53|1@1+ (1,0) [0|0] "" Vector__XXX
 SG_ APP_derateSocPower : 54|1@1+ (1,0) [0|0] "" Vector__XXX
 SG_ APP_thermalModelOutputInvalidReason : 55|3@1+ (1,0) [0|0] "" Vector__XXX

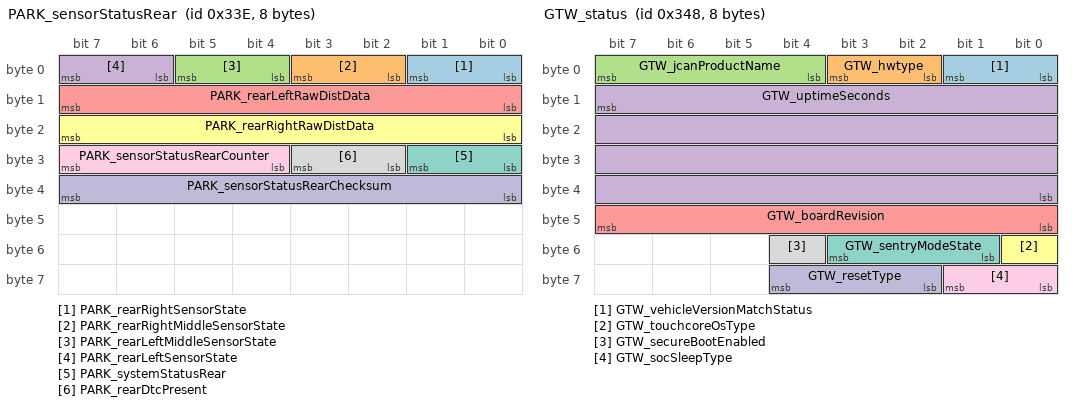
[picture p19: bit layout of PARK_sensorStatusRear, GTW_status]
BO_ 830 PARK_sensorStatusRear: 8 Vector__XXX
 SG_ PARK_rearRightSensorState : 0|2@1+ (1,0) [0|0] "" Vector__XXX
 SG_ PARK_rearRightMiddleSensorState : 2|2@1+ (1,0) [0|0] "" Vector__XXX
 SG_ PARK_rearLeftMiddleSensorState : 4|2@1+ (1,0) [0|0] "" Vector__XXX
 SG_ PARK_rearLeftSensorState : 6|2@1+ (1,0) [0|0] "" Vector__XXX
 SG_ PARK_rearLeftRawDistData : 8|8@1+ (1,0) [0|0] "" Vector__XXX
 SG_ PARK_rearRightRawDistData : 16|8@1+ (1,0) [0|0] "" Vector__XXX
 SG_ PARK_systemStatusRear : 24|2@1+ (1,0) [0|0] "" Vector__XXX
 SG_ PARK_rearDtcPresent : 26|2@1+ (1,0) [0|0] "" Vector__XXX
 SG_ PARK_sensorStatusRearCounter : 28|4@1+ (1,0) [0|0] "" Vector__XXX
 SG_ PARK_sensorStatusRearChecksum : 32|8@1+ (1,0) [0|0] "" Vector__XXX

BO_ 832 VCFRONT_alertMatrix: 8 Vector__XXX
 SG_ VCFRONT_matrixIndex M : 0|4@1+ (1,0) [0|0] "" Vector__XXX
 SG_ VCFRONT_a001_WatchdogReset m0 : 4|1@1+ (1,0) [0|0] "" Vector__XXX
 SG_ VCFRONT_a061_XCPConnected m1 : 4|1@1+ (1,0) [0|0] "" Vector__XXX
 SG_ VCFRONT_a121_pumpBatICLatchFault m2 : 4|1@1+ (1,0) [0|0] "" Vector__XXX
 SG_ VCFRONT_a181_homelinkMIA m3 : 4|1@1+ (1,0) [0|0] "" Vector__XXX
 SG_ VCFRONT_a301_wipersFactoryDisabled m5 : 4|1@1+ (1,0) [0|0] "" Vector__XXX
 SG_ VCFRONT_a361_washerFluidLowMomentary m6 : 4|1@1+ (1,0) [0|0] "" Vector__XXX
 SG_ VCFRONT_a421_leftHeadlampUartCondition m7 : 4|1@1+ (1,0) [0|0] "" Vector__XXX
 SG_ VCFRONT_a481_vnf1048SelfTestFailure m8 : 4|1@1+ (1,0) [0|0] "" Vector__XXX
 SG_ VCFRONT_a541_LVBatteryChargeOCLevel1 m9 : 4|1@1+ (1,0) [0|0] "" Vector__XXX
 SG_ VCFRONT_a601_autopilotAirPurgeLimitReached m10 : 4|1@1+ (1,0) [0|0] "" Vector__XXX
 SG_ VCFRONT_a661_mculessLeftHeadlampCurrentAlertDbg m11 : 4|1@1+ (1,0) [0|0] "" Vector__XXX
 SG_ VCFRONT_a002_PowerLossReset m0 : 5|1@1+ (1,0) [0|0] "" Vector__XXX
 SG_ VCFRONT_a062_XCPWasConnected m1 : 5|1@1+ (1,0) [0|0] "" Vector__XXX
 SG_ VCFRONT_a122_pumpBatICWarning m2 : 5|1@1+ (1,0) [0|0] "" Vector__XXX
 SG_ VCFRONT_a182_replaceLVBattery m3 : 5|1@1+ (1,0) [0|0] "" Vector__XXX
 SG_ VCFRONT_a242_drveBlckdVltgeTooLow m4 : 5|1@1+ (1,0) [0|0] "" Vector__XXX
 SG_ VCFRONT_a302_wiperCommError m5 : 5|1@1+ (1,0) [0|0] "" Vector__XXX
 SG_ VCFRONT_a362_TLVBMS_AllSocCorrectionTimeout m6 : 5|1@1+ (1,0) [0|0] "" Vector__XXX
 SG_ VCFRONT_a482_rightHeadlampMigrationDebug m8 : 5|1@1+ (1,0) [0|0] "" Vector__XXX
 SG_ VCFRONT_a542_refrigerantReclaim m9 : 5|1@1+ (1,0) [0|0] "" Vector__XXX
 SG_ VCFRONT_a662_mculessRightHeadlampCurrentAlertDbg m11 : 5|1@1+ (1,0) [0|0] "" Vector__XXX
 SG_ VCFRONT_a003_SWAssertion m0 : 6|1@1+ (1,0) [0|0] "" Vector__XXX
 SG_ VCFRONT_a063_SwitchFault m1 : 6|1@1+ (1,0) [0|0] "" Vector__XXX
 SG_ VCFRONT_a123_pumpPtICLatchFault m2 : 6|1@1+ (1,0) [0|0] "" Vector__XXX
 SG_ VCFRONT_a183_replaceLVBattery2 m3 : 6|1@1+ (1,0) [0|0] "" Vector__XXX
 SG_ VCFRONT_a243_LVOverchargeInstc m4 : 6|1@1+ (1,0) [0|0] "" Vector__XXX
 SG_ VCFRONT_a303_frunkAccessPostActive m5 : 6|1@1+ (1,0) [0|0] "" Vector__XXX
 SG_ VCFRONT_a363_TLVBMS_BleedBasedWeakShort m6 : 6|1@1+ (1,0) [0|0] "" Vector__XXX
 SG_ VCFRONT_a423_TLVBMS_BrickUnderVoltageFault m7 : 6|1@1+ (1,0) [0|0] "" Vector__XXX
 SG_ VCFRONT_a483_leftHeadlampStepperMotorFault m8 : 6|1@1+ (1,0) [0|0] "" Vector__XXX
 SG_ VCFRONT_a543_compressorLowFlowDeliveryDetected m9 : 6|1@1+ (1,0) [0|0] "" Vector__XXX
 SG_ VCFRONT_a663_leftHeadlampUartWaterMarkWarning m11 : 6|1@1+ (1,0) [0|0] "" Vector__XXX
 SG_ VCFRONT_a004_adaptiveHeadlightsUnavailable m0 : 7|1@1+ (1,0) [0|0] "" Vector__XXX
 SG_ VCFRONT_a064_busSleepReqTimeout m1 : 7|1@1+ (1,0) [0|0] "" Vector__XXX
 SG_ VCFRONT_a124_pumpPtICWarning m2 : 7|1@1+ (1,0) [0|0] "" Vector__XXX
 SG_ VCFRONT_a184_cabinCoolingPerformanceAbnormal m3 : 7|1@1+ (1,0) [0|0] "" Vector__XXX
 SG_ VCFRONT_a244_sleepBypassFault m4 : 7|1@1+ (1,0) [0|0] "" Vector__XXX
 SG_ VCFRONT_a304_frunkReleaseFailed m5 : 7|1@1+ (1,0) [0|0] "" Vector__XXX
 SG_ VCFRONT_a364_heaterTypeEstimationChanged m6 : 7|1@1+ (1,0) [0|0] "" Vector__XXX
 SG_ VCFRONT_a424_TLVBMS_BrickUnderVoltageOcv m7 : 7|1@1+ (1,0) [0|0] "" Vector__XXX
 SG_ VCFRONT_a484_headlampLevelingRideHeightDebug m8 : 7|1@1+ (1,0) [0|0] "" Vector__XXX
 SG_ VCFRONT_a544_LVBatteryCommsBusTurnedOff m9 : 7|1@1+ (1,0) [0|0] "" Vector__XXX
 SG_ VCFRONT_a664_rightHeadlampUartWaterMarkWarning m11 : 7|1@1+ (1,0) [0|0] "" Vector__XXX
 SG_ VCFRONT_a005_CANTXError m0 : 8|1@1+ (1,0) [0|0] "" Vector__XXX
 SG_ VCFRONT_a125_thmlFanICLatchFault m2 : 8|1@1+ (1,0) [0|0] "" Vector__XXX
 SG_ VCFRONT_a185_washerFluidLow m3 : 8|1@1+ (1,0) [0|0] "" Vector__XXX
 SG_ VCFRONT_a245_pump1EFuseFault m4 : 8|1@1+ (1,0) [0|0] "" Vector__XXX
 SG_ VCFRONT_a305_frunkPriOverCurrent m5 : 8|1@1+ (1,0) [0|0] "" Vector__XXX
 SG_ VCFRONT_a365_burnInRoutineEntered m6 : 8|1@1+ (1,0) [0|0] "" Vector__XXX
 SG_ VCFRONT_a425_TLVBMS_BusVoltageTooHigh m7 : 8|1@1+ (1,0) [0|0] "" Vector__XXX
 SG_ VCFRONT_a485_leftHeadlampMigrationDebug m8 : 8|1@1+ (1,0) [0|0] "" Vector__XXX
 SG_ VCFRONT_a545_LVBatteryTypeUnknown m9 : 8|1@1+ (1,0) [0|0] "" Vector__XXX
 SG_ VCFRONT_a605_sleepBypassPowerOff m10 : 8|1@1+ (1,0) [0|0] "" Vector__XXX
 SG_ VCFRONT_a665_leftHeadlampRetryInfo m11 : 8|1@1+ (1,0) [0|0] "" Vector__XXX
 SG_ VCFRONT_a006_CANTX_cyclicError m0 : 9|1@1+ (1,0) [0|0] "" Vector__XXX
 SG_ VCFRONT_a126_thmlFanICWarning m2 : 9|1@1+ (1,0) [0|0] "" Vector__XXX
 SG_ VCFRONT_a186_noDriveChgCableCon m3 : 9|1@1+ (1,0) [0|0] "" Vector__XXX
 SG_ VCFRONT_a246_pump2EFuseFault m4 : 9|1@1+ (1,0) [0|0] "" Vector__XXX
 SG_ VCFRONT_a306_frunkPriUnderCurrent m5 : 9|1@1+ (1,0) [0|0] "" Vector__XXX
 SG_ VCFRONT_a366_burnInRoutineExited m6 : 9|1@1+ (1,0) [0|0] "" Vector__XXX
 SG_ VCFRONT_a426_TLVBMS_BusVoltageTooLow m7 : 9|1@1+ (1,0) [0|0] "" Vector__XXX
 SG_ VCFRONT_a486_mcuGraphicsEFuseFault m8 : 9|1@1+ (1,0) [0|0] "" Vector__XXX
 SG_ VCFRONT_a546_leftLowOrHighBeamLightCondition m9 : 9|1@1+ (1,0) [0|0] "" Vector__XXX
 SG_ VCFRONT_a606_chillerBattHeatingExit m10 : 9|1@1+ (1,0) [0|0] "" Vector__XXX
 SG_ VCFRONT_a666_rightHeadlampRetryInfo m11 : 9|1@1+ (1,0) [0|0] "" Vector__XXX
 SG_ VCFRONT_a127_vcleftEFuseTrip m2 : 10|1@1+ (1,0) [0|0] "" Vector__XXX
 SG_ VCFRONT_a187_busesNotSleeping m3 : 10|1@1+ (1,0) [0|0] "" Vector__XXX
 SG_ VCFRONT_a247_evapSolenoidFault m4 : 10|1@1+ (1,0) [0|0] "" Vector__XXX
 SG_ VCFRONT_a307_frunkSecOverCurrent m5 : 10|1@1+ (1,0) [0|0] "" Vector__XXX
 SG_ VCFRONT_a367_dischargeRoutineEntered m6 : 10|1@1+ (1,0) [0|0] "" Vector__XXX
 SG_ VCFRONT_a427_TLVBMS_CacChange m7 : 10|1@1+ (1,0) [0|0] "" Vector__XXX
 SG_ VCFRONT_a487_leftHeadlampLastPositionUpdate m8 : 10|1@1+ (1,0) [0|0] "" Vector__XXX
 SG_ VCFRONT_a547_postCrashLoadShed m9 : 10|1@1+ (1,0) [0|0] "" Vector__XXX
 SG_ VCFRONT_a607_sleepPowerDebug m10 : 10|1@1+ (1,0) [0|0] "" Vector__XXX
 SG_ VCFRONT_a667_leftHeadlampRegionOrSideMismatch m11 : 10|1@1+ (1,0) [0|0] "" Vector__XXX
 SG_ VCFRONT_a008_adaptiveHeadlightsUnavailableStalk m0 : 11|1@1+ (1,0) [0|0] "" Vector__XXX
 SG_ VCFRONT_a128_vcrightEFuseTrip m2 : 11|1@1+ (1,0) [0|0] "" Vector__XXX
 SG_ VCFRONT_a188_sleepFailed m3 : 11|1@1+ (1,0) [0|0] "" Vector__XXX
 SG_ VCFRONT_a248_voltageOutOfSpec m4 : 11|1@1+ (1,0) [0|0] "" Vector__XXX
 SG_ VCFRONT_a308_frunkSecUnderCurrent m5 : 11|1@1+ (1,0) [0|0] "" Vector__XXX
 SG_ VCFRONT_a368_dischargeRoutineExited m6 : 11|1@1+ (1,0) [0|0] "" Vector__XXX
 SG_ VCFRONT_a428_TLVBMS_CacImbalance m7 : 11|1@1+ (1,0) [0|0] "" Vector__XXX
 SG_ VCFRONT_a488_rightHeadlampStepperMotorFault m8 : 11|1@1+ (1,0) [0|0] "" Vector__XXX
 SG_ VCFRONT_a548_HVFaultLoadShed m9 : 11|1@1+ (1,0) [0|0] "" Vector__XXX
 SG_ VCFRONT_a608_TLVBMS_BleedFetFailure m10 : 11|1@1+ (1,0) [0|0] "" Vector__XXX
 SG_ VCFRONT_a668_rightHeadlampRegionOrSideMismatch m11 : 11|1@1+ (1,0) [0|0] "" Vector__XXX
 SG_ VCFRONT_a009_LCCPurgeAttempted m0 : 12|1@1+ (1,0) [0|0] "" Vector__XXX
 SG_ VCFRONT_a129_pcsEFuseTrip m2 : 12|1@1+ (1,0) [0|0] "" Vector__XXX
 SG_ VCFRONT_a189_IBSMIA m3 : 12|1@1+ (1,0) [0|0] "" Vector__XXX
 SG_ VCFRONT_a249_coolantValveBadMode m4 : 12|1@1+ (1,0) [0|0] "" Vector__XXX
 SG_ VCFRONT_a309_frunkEmergencyReleasePressed m5 : 12|1@1+ (1,0) [0|0] "" Vector__XXX
 SG_ VCFRONT_a369_reducedPowerDischarge m6 : 12|1@1+ (1,0) [0|0] "" Vector__XXX
 SG_ VCFRONT_a429_TLVBMS_CapacityTestResults m7 : 12|1@1+ (1,0) [0|0] "" Vector__XXX
 SG_ VCFRONT_a489_ValveStuckFlagged m8 : 12|1@1+ (1,0) [0|0] "" Vector__XXX
 SG_ VCFRONT_a609_autopilotDriveNotAuthed m10 : 12|1@1+ (1,0) [0|0] "" Vector__XXX
 SG_ VCFRONT_a669_thermalHVPowerBudgetActive m11 : 12|1@1+ (1,0) [0|0] "" Vector__XXX
 SG_ VCFRONT_a010_ExtSupplyVoltError m0 : 13|1@1+ (1,0) [0|0] "" Vector__XXX
 SG_ VCFRONT_a130_epas3pEFuseTrip m2 : 13|1@1+ (1,0) [0|0] "" Vector__XXX
 SG_ VCFRONT_a190_linSchedulingInfo m3 : 13|1@1+ (1,0) [0|0] "" Vector__XXX
 SG_ VCFRONT_a250_headlampsNotAimed m4 : 13|1@1+ (1,0) [0|0] "" Vector__XXX
 SG_ VCFRONT_a310_vcleftOvertempSlope m5 : 13|1@1+ (1,0) [0|0] "" Vector__XXX
 SG_ VCFRONT_a370_noLVSupportSocTooLow m6 : 13|1@1+ (1,0) [0|0] "" Vector__XXX
 SG_ VCFRONT_a430_TLVBMS_ChargeCurrentLimitExceeded m7 : 13|1@1+ (1,0) [0|0] "" Vector__XXX
 SG_ VCFRONT_a490_coolantPumpsNotIdentified m8 : 13|1@1+ (1,0) [0|0] "" Vector__XXX
 SG_ VCFRONT_a610_frunkOpenFailureMetricSet m10 : 13|1@1+ (1,0) [0|0] "" Vector__XXX
 SG_ VCFRONT_a131_epas3sEFuseTrip m2 : 14|1@1+ (1,0) [0|0] "" Vector__XXX
 SG_ VCFRONT_a191_exitDriveLowLVBusVoltage m3 : 14|1@1+ (1,0) [0|0] "" Vector__XXX
 SG_ VCFRONT_a251_UIWakeupTrigger m4 : 14|1@1+ (1,0) [0|0] "" Vector__XXX
 SG_ VCFRONT_a311_vcrightOvertempSlope m5 : 14|1@1+ (1,0) [0|0] "" Vector__XXX
 SG_ VCFRONT_a371_failureToPrechargeRisk m6 : 14|1@1+ (1,0) [0|0] "" Vector__XXX
 SG_ VCFRONT_a431_TLVBMS_ChargeOverCurrent m7 : 14|1@1+ (1,0) [0|0] "" Vector__XXX
 SG_ VCFRONT_a491_rightHeadlampLastPositionUpdate m8 : 14|1@1+ (1,0) [0|0] "" Vector__XXX
 SG_ VCFRONT_a551_leftHeadlampSoftShort m9 : 14|1@1+ (1,0) [0|0] "" Vector__XXX
 SG_ VCFRONT_a611_poorRadiatorHeatRejection m10 : 14|1@1+ (1,0) [0|0] "" Vector__XXX
 SG_ VCFRONT_a012_CPUReset m0 : 15|1@1+ (1,0) [0|0] "" Vector__XXX
 SG_ VCFRONT_a132_iBoosterEFuseTrip m2 : 15|1@1+ (1,0) [0|0] "" Vector__XXX
 SG_ VCFRONT_a192_vehicleLoadShed m3 : 15|1@1+ (1,0) [0|0] "" Vector__XXX
 SG_ VCFRONT_a252_controllerWakeup m4 : 15|1@1+ (1,0) [0|0] "" Vector__XXX
 SG_ VCFRONT_a312_pcsOvertempSlope m5 : 15|1@1+ (1,0) [0|0] "" Vector__XXX
 SG_ VCFRONT_a372_TLVBMS_BmbHwOverVoltageFault m6 : 15|1@1+ (1,0) [0|0] "" Vector__XXX
 SG_ VCFRONT_a432_TLVBMS_ChargeRegulationFault m7 : 15|1@1+ (1,0) [0|0] "" Vector__XXX
 SG_ VCFRONT_a492_TLVBMS_SocImbalance m8 : 15|1@1+ (1,0) [0|0] "" Vector__XXX
 SG_ VCFRONT_a552_eFuseSelfTestFailure m9 : 15|1@1+ (1,0) [0|0] "" Vector__XXX
 SG_ VCFRONT_a612_LVUnhealthyLoadShed m10 : 15|1@1+ (1,0) [0|0] "" Vector__XXX
 SG_ VCFRONT_a013_AlertManagerFault m0 : 16|1@1+ (1,0) [0|0] "" Vector__XXX
 SG_ VCFRONT_a133_espEFuseTrip m2 : 16|1@1+ (1,0) [0|0] "" Vector__XXX
 SG_ VCFRONT_a193_mcuAudioRetry m3 : 16|1@1+ (1,0) [0|0] "" Vector__XXX
 SG_ VCFRONT_a253_maxChrgeSssionTmeout m4 : 16|1@1+ (1,0) [0|0] "" Vector__XXX
 SG_ VCFRONT_a313_epas3pOvertempSlope m5 : 16|1@1+ (1,0) [0|0] "" Vector__XXX
 SG_ VCFRONT_a373_chillerControlFlooding m6 : 16|1@1+ (1,0) [0|0] "" Vector__XXX
 SG_ VCFRONT_a433_TLVBMS_ConfigFromBmbModIdFailed m7 : 16|1@1+ (1,0) [0|0] "" Vector__XXX
 SG_ VCFRONT_a493_TLVBMS_SocImbalanceWarning m8 : 16|1@1+ (1,0) [0|0] "" Vector__XXX
 SG_ VCFRONT_a553_rightHeadlampSoftShort m9 : 16|1@1+ (1,0) [0|0] "" Vector__XXX
 SG_ VCFRONT_a613_selfTestsBlockingDrive m10 : 16|1@1+ (1,0) [0|0] "" Vector__XXX
 SG_ VCFRONT_a134_fusedHighEFuseTrip m2 : 17|1@1+ (1,0) [0|0] "" Vector__XXX
 SG_ VCFRONT_a194_iBoosterRetry m3 : 17|1@1+ (1,0) [0|0] "" Vector__XXX
 SG_ VCFRONT_a254_pumpBatStopped m4 : 17|1@1+ (1,0) [0|0] "" Vector__XXX
 SG_ VCFRONT_a314_epas3sOvertempSlope m5 : 17|1@1+ (1,0) [0|0] "" Vector__XXX
 SG_ VCFRONT_a374_lccInletSolenoidFault m6 : 17|1@1+ (1,0) [0|0] "" Vector__XXX
 SG_ VCFRONT_a434_TLVBMS_ConfigInitFailed m7 : 17|1@1+ (1,0) [0|0] "" Vector__XXX
 SG_ VCFRONT_a494_LVBatteryTempBlockingOTA m8 : 17|1@1+ (1,0) [0|0] "" Vector__XXX
 SG_ VCFRONT_a614_coolantSysDriverlessSelfTest m10 : 17|1@1+ (1,0) [0|0] "" Vector__XXX
 SG_ VCFRONT_a015_NVMMError m0 : 18|1@1+ (1,0) [0|0] "" Vector__XXX
 SG_ VCFRONT_a135_coolantLevelLow m2 : 18|1@1+ (1,0) [0|0] "" Vector__XXX
 SG_ VCFRONT_a195_drveBlckdVltgeTooHgh m3 : 18|1@1+ (1,0) [0|0] "" Vector__XXX
 SG_ VCFRONT_a255_pumpPtStopped m4 : 18|1@1+ (1,0) [0|0] "" Vector__XXX
 SG_ VCFRONT_a315_iboosterOvertempSlope m5 : 18|1@1+ (1,0) [0|0] "" Vector__XXX
 SG_ VCFRONT_a375_refVoltageOutOfSpec m6 : 18|1@1+ (1,0) [0|0] "" Vector__XXX
 SG_ VCFRONT_a435_TLVBMS_DchgCurrentLimitExceeded m7 : 18|1@1+ (1,0) [0|0] "" Vector__XXX
 SG_ VCFRONT_a495_LVBatteryRecoveryBlocked m8 : 18|1@1+ (1,0) [0|0] "" Vector__XXX
 SG_ VCFRONT_a555_LVBatteryCellRebalancing m9 : 18|1@1+ (1,0) [0|0] "" Vector__XXX
 SG_ VCFRONT_a615_TLVBMS_BatteryHeaterFault m10 : 18|1@1+ (1,0) [0|0] "" Vector__XXX
 SG_ VCFRONT_a016_NVMMRecordError m0 : 19|1@1+ (1,0) [0|0] "" Vector__XXX
 SG_ VCFRONT_a136_refrigDischTempSns m2 : 19|1@1+ (1,0) [0|0] "" Vector__XXX
 SG_ VCFRONT_a196_discnctdLVBattery m3 : 19|1@1+ (1,0) [0|0] "" Vector__XXX
 SG_ VCFRONT_a256_compTornShaftSeal m4 : 19|1@1+ (1,0) [0|0] "" Vector__XXX
 SG_ VCFRONT_a316_espOvertempSlope m5 : 19|1@1+ (1,0) [0|0] "" Vector__XXX
 SG_ VCFRONT_a376_controllerWakeupDebug m6 : 19|1@1+ (1,0) [0|0] "" Vector__XXX
 SG_ VCFRONT_a436_TLVBMS_DischargeOverCurrent m7 : 19|1@1+ (1,0) [0|0] "" Vector__XXX
 SG_ VCFRONT_a496_LVBatteryExitDriveWarning m8 : 19|1@1+ (1,0) [0|0] "" Vector__XXX
 SG_ VCFRONT_a556_falseTriggerOfDiscnctdBatteryTest m9 : 19|1@1+ (1,0) [0|0] "" Vector__XXX
 SG_ VCFRONT_a017_NVMMStatusDbg m0 : 20|1@1+ (1,0) [0|0] "" Vector__XXX
 SG_ VCFRONT_a137_refrigDischPresSns m2 : 20|1@1+ (1,0) [0|0] "" Vector__XXX
 SG_ VCFRONT_a197_prechargeDCRData3 m3 : 20|1@1+ (1,0) [0|0] "" Vector__XXX
 SG_ VCFRONT_a257_portExpanderVOR m4 : 20|1@1+ (1,0) [0|0] "" Vector__XXX
 SG_ VCFRONT_a317_vbatFusedOvertempSlope m5 : 20|1@1+ (1,0) [0|0] "" Vector__XXX
 SG_ VCFRONT_a377_wiperParkFault m6 : 20|1@1+ (1,0) [0|0] "" Vector__XXX
 SG_ VCFRONT_a437_TLVBMS_NvmRegistrationError m7 : 20|1@1+ (1,0) [0|0] "" Vector__XXX
 SG_ VCFRONT_a497_LVBatteryWarnDisconnect m8 : 20|1@1+ (1,0) [0|0] "" Vector__XXX
 SG_ VCFRONT_a138_refrigSuctTempSns m2 : 21|1@1+ (1,0) [0|0] "" Vector__XXX
 SG_ VCFRONT_a198_PRVCANOverterminate m3 : 21|1@1+ (1,0) [0|0] "" Vector__XXX
 SG_ VCFRONT_a258_resistanceEstimationRun m4 : 21|1@1+ (1,0) [0|0] "" Vector__XXX
 SG_ VCFRONT_a318_vcleftOvertempMax m5 : 21|1@1+ (1,0) [0|0] "" Vector__XXX
 SG_ VCFRONT_a378_wiperECUDebug m6 : 21|1@1+ (1,0) [0|0] "" Vector__XXX
 SG_ VCFRONT_a438_TLVBMS_PackOverTemperatureFault m7 : 21|1@1+ (1,0) [0|0] "" Vector__XXX
 SG_ VCFRONT_a498_TLVBMS_ImpedanceTestResults m8 : 21|1@1+ (1,0) [0|0] "" Vector__XXX
 SG_ VCFRONT_a558_rightHeadlampAimingDebug m9 : 21|1@1+ (1,0) [0|0] "" Vector__XXX
 SG_ VCFRONT_a618_cabinCoolingCapacityLimited m10 : 21|1@1+ (1,0) [0|0] "" Vector__XXX
 SG_ VCFRONT_a139_refrigSuctPresSns m2 : 22|1@1+ (1,0) [0|0] "" Vector__XXX
 SG_ VCFRONT_a199_PRVCANUndertrminate m3 : 22|1@1+ (1,0) [0|0] "" Vector__XXX
 SG_ VCFRONT_a259_LVVoltageDropOnHighLoadCurrent m4 : 22|1@1+ (1,0) [0|0] "" Vector__XXX
 SG_ VCFRONT_a319_vcrightOvertempMax m5 : 22|1@1+ (1,0) [0|0] "" Vector__XXX
 SG_ VCFRONT_a379_shortedCellTestRunDebug m6 : 22|1@1+ (1,0) [0|0] "" Vector__XXX
 SG_ VCFRONT_a439_TLVBMS_PackOverTemperatureWarning m7 : 22|1@1+ (1,0) [0|0] "" Vector__XXX
 SG_ VCFRONT_a499_loadShedPumpFlowRequest m8 : 22|1@1+ (1,0) [0|0] "" Vector__XXX
 SG_ VCFRONT_a559_LVBatteryLowSOC m9 : 22|1@1+ (1,0) [0|0] "" Vector__XXX
 SG_ VCFRONT_a619_frunkSwitchReleaseTimeDBG m10 : 22|1@1+ (1,0) [0|0] "" Vector__XXX
 SG_ VCFRONT_a140_coolantTempPtSns m2 : 23|1@1+ (1,0) [0|0] "" Vector__XXX
 SG_ VCFRONT_a200_vcleftSelfTestFail m3 : 23|1@1+ (1,0) [0|0] "" Vector__XXX
 SG_ VCFRONT_a260_deadLVBattery m4 : 23|1@1+ (1,0) [0|0] "" Vector__XXX
 SG_ VCFRONT_a320_pcsOvertempMax m5 : 23|1@1+ (1,0) [0|0] "" Vector__XXX
 SG_ VCFRONT_a380_chillerExvWarning m6 : 23|1@1+ (1,0) [0|0] "" Vector__XXX
 SG_ VCFRONT_a440_TLVBMS_PackSNInvalidForNvm m7 : 23|1@1+ (1,0) [0|0] "" Vector__XXX
 SG_ VCFRONT_a500_eFuseASICStateMismatch m8 : 23|1@1+ (1,0) [0|0] "" Vector__XXX
 SG_ VCFRONT_a560_compressorHighSuperheat m9 : 23|1@1+ (1,0) [0|0] "" Vector__XXX
 SG_ VCFRONT_a021_TaskSchedulerError m0 : 24|1@1+ (1,0) [0|0] "" Vector__XXX
 SG_ VCFRONT_a141_coolantTempBatSns m2 : 24|1@1+ (1,0) [0|0] "" Vector__XXX
 SG_ VCFRONT_a201_vcrightSelfTestFail m3 : 24|1@1+ (1,0) [0|0] "" Vector__XXX
 SG_ VCFRONT_a261_vcleftVoltageMismatch m4 : 24|1@1+ (1,0) [0|0] "" Vector__XXX
 SG_ VCFRONT_a321_epas3pOvertempMax m5 : 24|1@1+ (1,0) [0|0] "" Vector__XXX
 SG_ VCFRONT_a381_evaporatorExvWarning m6 : 24|1@1+ (1,0) [0|0] "" Vector__XXX
 SG_ VCFRONT_a441_TLVBMS_ResetNeededForNvmPackSwap m7 : 24|1@1+ (1,0) [0|0] "" Vector__XXX
 SG_ VCFRONT_a501_vnf1048ConfigurationMismatch m8 : 24|1@1+ (1,0) [0|0] "" Vector__XXX
 SG_ VCFRONT_a561_LVBMSEFuseOvertemperature m9 : 24|1@1+ (1,0) [0|0] "" Vector__XXX
 SG_ VCFRONT_a022_TaskInitError m0 : 25|1@1+ (1,0) [0|0] "" Vector__XXX
 SG_ VCFRONT_a082_VCRIGHT_IPC_MIA m1 : 25|1@1+ (1,0) [0|0] "" Vector__XXX
 SG_ VCFRONT_a142_exvMotorFault m2 : 25|1@1+ (1,0) [0|0] "" Vector__XXX
 SG_ VCFRONT_a202_pcsSelfTestFail m3 : 25|1@1+ (1,0) [0|0] "" Vector__XXX
 SG_ VCFRONT_a262_vcrightVoltageMismatch m4 : 25|1@1+ (1,0) [0|0] "" Vector__XXX
 SG_ VCFRONT_a322_epas3sOvertempMax m5 : 25|1@1+ (1,0) [0|0] "" Vector__XXX
 SG_ VCFRONT_a382_recircExvWarning m6 : 25|1@1+ (1,0) [0|0] "" Vector__XXX
 SG_ VCFRONT_a442_TLVBMS_SocChange m7 : 25|1@1+ (1,0) [0|0] "" Vector__XXX
 SG_ VCFRONT_a502_TLVBMS_WeakShortImpedance m8 : 25|1@1+ (1,0) [0|0] "" Vector__XXX
 SG_ VCFRONT_a562_LVBMSModuleOvertemperature m9 : 25|1@1+ (1,0) [0|0] "" Vector__XXX
 SG_ VCFRONT_a083_VCLEFT_IPC_MIA m1 : 26|1@1+ (1,0) [0|0] "" Vector__XXX
 SG_ VCFRONT_a143_pumpBatICTransFault m2 : 26|1@1+ (1,0) [0|0] "" Vector__XXX
 SG_ VCFRONT_a203_epas3pSelfTestFail m3 : 26|1@1+ (1,0) [0|0] "" Vector__XXX
 SG_ VCFRONT_a263_pcsVoltageMismatch m4 : 26|1@1+ (1,0) [0|0] "" Vector__XXX
 SG_ VCFRONT_a323_iboosterOvertempMax m5 : 26|1@1+ (1,0) [0|0] "" Vector__XXX
 SG_ VCFRONT_a383_lccExvWarning m6 : 26|1@1+ (1,0) [0|0] "" Vector__XXX
 SG_ VCFRONT_a443_TLVBMS_BmbDieOverTemperature m7 : 26|1@1+ (1,0) [0|0] "" Vector__XXX
 SG_ VCFRONT_a503_TLVBMS_BrickExtendedOvFault m8 : 26|1@1+ (1,0) [0|0] "" Vector__XXX
 SG_ VCFRONT_a563_chargePortDoorOpenBlockedByBrake m9 : 26|1@1+ (1,0) [0|0] "" Vector__XXX
 SG_ VCFRONT_a623_LVUnhealthy m10 : 26|1@1+ (1,0) [0|0] "" Vector__XXX
 SG_ VCFRONT_a084_TPMS_MIA m1 : 27|1@1+ (1,0) [0|0] "" Vector__XXX
 SG_ VCFRONT_a144_pumpPtICTransFault m2 : 27|1@1+ (1,0) [0|0] "" Vector__XXX
 SG_ VCFRONT_a204_epas3sSelfTestFail m3 : 27|1@1+ (1,0) [0|0] "" Vector__XXX
 SG_ VCFRONT_a264_iBoosterVoltageMismatch m4 : 27|1@1+ (1,0) [0|0] "" Vector__XXX
 SG_ VCFRONT_a324_espOvertempMax m5 : 27|1@1+ (1,0) [0|0] "" Vector__XXX
 SG_ VCFRONT_a384_ccLeftExvWarning m6 : 27|1@1+ (1,0) [0|0] "" Vector__XXX
 SG_ VCFRONT_a444_drv8703Fault m7 : 27|1@1+ (1,0) [0|0] "" Vector__XXX
 SG_ VCFRONT_a504_airInRefrigerantDetected m8 : 27|1@1+ (1,0) [0|0] "" Vector__XXX
 SG_ VCFRONT_a564_leftHeadlampAimingDebug m9 : 27|1@1+ (1,0) [0|0] "" Vector__XXX
 SG_ VCFRONT_a085_CCCM_MIA m1 : 28|1@1+ (1,0) [0|0] "" Vector__XXX
 SG_ VCFRONT_a145_thmlFanICTransFault m2 : 28|1@1+ (1,0) [0|0] "" Vector__XXX
 SG_ VCFRONT_a205_iBoosterSelfTestFail m3 : 28|1@1+ (1,0) [0|0] "" Vector__XXX
 SG_ VCFRONT_a265_ESPVoltageMismatch m4 : 28|1@1+ (1,0) [0|0] "" Vector__XXX
 SG_ VCFRONT_a325_vbatFusedOvertempMax m5 : 28|1@1+ (1,0) [0|0] "" Vector__XXX
 SG_ VCFRONT_a385_ccRightExvWarning m6 : 28|1@1+ (1,0) [0|0] "" Vector__XXX
 SG_ VCFRONT_a445_drv8703SpiFaultDBG m7 : 28|1@1+ (1,0) [0|0] "" Vector__XXX
 SG_ VCFRONT_a505_BLEFrontUnderVoltage m8 : 28|1@1+ (1,0) [0|0] "" Vector__XXX
 SG_ VCFRONT_a565_userPresenceDisplayStateMismatch m9 : 28|1@1+ (1,0) [0|0] "" Vector__XXX
 SG_ VCFRONT_a086_VCBATT_MIA m1 : 29|1@1+ (1,0) [0|0] "" Vector__XXX
 SG_ VCFRONT_a146_pumpBatSoftStall m2 : 29|1@1+ (1,0) [0|0] "" Vector__XXX
 SG_ VCFRONT_a206_espSelfTestFail m3 : 29|1@1+ (1,0) [0|0] "" Vector__XXX
 SG_ VCFRONT_a266_EPAS3pVoltageMismatch m4 : 29|1@1+ (1,0) [0|0] "" Vector__XXX
 SG_ VCFRONT_a326_vcleftSlowTripOC m5 : 29|1@1+ (1,0) [0|0] "" Vector__XXX
 SG_ VCFRONT_a386_exvMotorWarning m6 : 29|1@1+ (1,0) [0|0] "" Vector__XXX
 SG_ VCFRONT_a446_cabinHVACUnavailableContext m7 : 29|1@1+ (1,0) [0|0] "" Vector__XXX
 SG_ VCFRONT_a506_invalidRefrigerantSystemConfig m8 : 29|1@1+ (1,0) [0|0] "" Vector__XXX
 SG_ VCFRONT_a566_leftFrontTurnLightFault m9 : 29|1@1+ (1,0) [0|0] "" Vector__XXX
 SG_ VCFRONT_a626_LVBatteryResistanceIncrease m10 : 29|1@1+ (1,0) [0|0] "" Vector__XXX
 SG_ VCFRONT_a087_DIREL_MIA m1 : 30|1@1+ (1,0) [0|0] "" Vector__XXX
 SG_ VCFRONT_a147_pumpPtSoftStall m2 : 30|1@1+ (1,0) [0|0] "" Vector__XXX
 SG_ VCFRONT_a207_vbatFusdSelfTestFail m3 : 30|1@1+ (1,0) [0|0] "" Vector__XXX
 SG_ VCFRONT_a267_EPAS3sVoltageMismatch m4 : 30|1@1+ (1,0) [0|0] "" Vector__XXX
 SG_ VCFRONT_a327_vcrightSlowTripOC m5 : 30|1@1+ (1,0) [0|0] "" Vector__XXX
 SG_ VCFRONT_a387_shortedCellInstc m6 : 30|1@1+ (1,0) [0|0] "" Vector__XXX
 SG_ VCFRONT_a447_cabinHVACUnavailable m7 : 30|1@1+ (1,0) [0|0] "" Vector__XXX
 SG_ VCFRONT_a507_leftHeadlampAimingFault m8 : 30|1@1+ (1,0) [0|0] "" Vector__XXX
 SG_ VCFRONT_a567_rightFrontTurnLightFault m9 : 30|1@1+ (1,0) [0|0] "" Vector__XXX
 SG_ VCFRONT_a627_LVBatteryUnrecoverableByAnyDevice m10 : 30|1@1+ (1,0) [0|0] "" Vector__XXX
 SG_ VCFRONT_a088_DIRER_MIA m1 : 31|1@1+ (1,0) [0|0] "" Vector__XXX
 SG_ VCFRONT_a148_thmlFanSoftStall m2 : 31|1@1+ (1,0) [0|0] "" Vector__XXX
 SG_ VCFRONT_a208_brakeFluidLow m3 : 31|1@1+ (1,0) [0|0] "" Vector__XXX
 SG_ VCFRONT_a268_vbatFusedVoltageMismatch m4 : 31|1@1+ (1,0) [0|0] "" Vector__XXX
 SG_ VCFRONT_a328_pcsSlowTripOC m5 : 31|1@1+ (1,0) [0|0] "" Vector__XXX
 SG_ VCFRONT_a388_shortedCell m6 : 31|1@1+ (1,0) [0|0] "" Vector__XXX
 SG_ VCFRONT_a448_gtwSteeringBtnReset m7 : 31|1@1+ (1,0) [0|0] "" Vector__XXX
 SG_ VCFRONT_a508_TLVBMS_ImpedanceGrowth m8 : 31|1@1+ (1,0) [0|0] "" Vector__XXX
 SG_ VCFRONT_a568_leftDaytimeRunningLightFault m9 : 31|1@1+ (1,0) [0|0] "" Vector__XXX
 SG_ VCFRONT_a628_TLVBMS_BmbThermistorFault m10 : 31|1@1+ (1,0) [0|0] "" Vector__XXX
 SG_ VCFRONT_a029_CoreDump m0 : 32|1@1+ (1,0) [0|0] "" Vector__XXX
 SG_ VCFRONT_a089_IBST_MIA m1 : 32|1@1+ (1,0) [0|0] "" Vector__XXX
 SG_ VCFRONT_a149_BLEFrontPowerCycled m2 : 32|1@1+ (1,0) [0|0] "" Vector__XXX
 SG_ VCFRONT_a209_brakeFluidSNA m3 : 32|1@1+ (1,0) [0|0] "" Vector__XXX
 SG_ VCFRONT_a269_drveBlckdVltgeTooLow2 m4 : 32|1@1+ (1,0) [0|0] "" Vector__XXX
 SG_ VCFRONT_a329_epas3pSlowTripOC m5 : 32|1@1+ (1,0) [0|0] "" Vector__XXX
 SG_ VCFRONT_a389_frunkInhibitingReleaseAtSpeed m6 : 32|1@1+ (1,0) [0|0] "" Vector__XXX
 SG_ VCFRONT_a449_hornSwitchStuckOn m7 : 32|1@1+ (1,0) [0|0] "" Vector__XXX
 SG_ VCFRONT_a509_vcrightEFuseLoadShed m8 : 32|1@1+ (1,0) [0|0] "" Vector__XXX
 SG_ VCFRONT_a569_rightDaytimeRunningLightFault m9 : 32|1@1+ (1,0) [0|0] "" Vector__XXX
 SG_ VCFRONT_a629_TLVBMS_PackTemperatureIrrational m10 : 32|1@1+ (1,0) [0|0] "" Vector__XXX
 SG_ VCFRONT_a030_ECULogUploadRequest m0 : 33|1@1+ (1,0) [0|0] "" Vector__XXX
 SG_ VCFRONT_a090_APS_MIA m1 : 33|1@1+ (1,0) [0|0] "" Vector__XXX
 SG_ VCFRONT_a150_pumpBatLowRPMCBang m2 : 33|1@1+ (1,0) [0|0] "" Vector__XXX
 SG_ VCFRONT_a210_coolantValveCalib m3 : 33|1@1+ (1,0) [0|0] "" Vector__XXX
 SG_ VCFRONT_a330_epas3sSlowTripOC m5 : 33|1@1+ (1,0) [0|0] "" Vector__XXX
 SG_ VCFRONT_a390_heatPumpModeConvergence m6 : 33|1@1+ (1,0) [0|0] "" Vector__XXX
 SG_ VCFRONT_a450_hornSwitchNotPressedFactory m7 : 33|1@1+ (1,0) [0|0] "" Vector__XXX
 SG_ VCFRONT_a510_LVBatteryRecoveryTimeout m8 : 33|1@1+ (1,0) [0|0] "" Vector__XXX
 SG_ VCFRONT_a570_headlampsAdaptedToLeftHandTraffic m9 : 33|1@1+ (1,0) [0|0] "" Vector__XXX
 SG_ VCFRONT_a630_leftHeadlampFactoryFault m10 : 33|1@1+ (1,0) [0|0] "" Vector__XXX
 SG_ VCFRONT_a031_UDSActive m0 : 34|1@1+ (1,0) [0|0] "" Vector__XXX
 SG_ VCFRONT_a091_CMPD_MIA m1 : 34|1@1+ (1,0) [0|0] "" Vector__XXX
 SG_ VCFRONT_a151_pumpPtLowRPMCBang m2 : 34|1@1+ (1,0) [0|0] "" Vector__XXX
 SG_ VCFRONT_a211_I2CFault m3 : 34|1@1+ (1,0) [0|0] "" Vector__XXX
 SG_ VCFRONT_a271_LVBatteryPermSupported m4 : 34|1@1+ (1,0) [0|0] "" Vector__XXX
 SG_ VCFRONT_a331_iboosterSlowTripOC m5 : 34|1@1+ (1,0) [0|0] "" Vector__XXX
 SG_ VCFRONT_a391_frunkLatchSwitchFault m6 : 34|1@1+ (1,0) [0|0] "" Vector__XXX
 SG_ VCFRONT_a451_refrigerantNotCommissioned m7 : 34|1@1+ (1,0) [0|0] "" Vector__XXX
 SG_ VCFRONT_a511_DCDCSaturationLoadShed m8 : 34|1@1+ (1,0) [0|0] "" Vector__XXX
 SG_ VCFRONT_a571_headlampsAdaptedToRightHandTraffic m9 : 34|1@1+ (1,0) [0|0] "" Vector__XXX
 SG_ VCFRONT_a631_rightHeadlampFactoryFault m10 : 34|1@1+ (1,0) [0|0] "" Vector__XXX
 SG_ VCFRONT_a032_ipcWatchdogExpired m0 : 35|1@1+ (1,0) [0|0] "" Vector__XXX
 SG_ VCFRONT_a092_VCSEATD_MIA m1 : 35|1@1+ (1,0) [0|0] "" Vector__XXX
 SG_ VCFRONT_a152_thmlFanLowRPMCBang m2 : 35|1@1+ (1,0) [0|0] "" Vector__XXX
 SG_ VCFRONT_a212_IBSOverTemp m3 : 35|1@1+ (1,0) [0|0] "" Vector__XXX
 SG_ VCFRONT_a332_espSlowTripOC m5 : 35|1@1+ (1,0) [0|0] "" Vector__XXX
 SG_ VCFRONT_a392_TLVBMS_BmbHwUnderVoltageFault m6 : 35|1@1+ (1,0) [0|0] "" Vector__XXX
 SG_ VCFRONT_a452_dischargePresSensIntermittent m7 : 35|1@1+ (1,0) [0|0] "" Vector__XXX
 SG_ VCFRONT_a512_LVBMSFault_MOS_Open_hardwareOC m8 : 35|1@1+ (1,0) [0|0] "" Vector__XXX
 SG_ VCFRONT_a572_hvacCompressorEFuseTrip m9 : 35|1@1+ (1,0) [0|0] "" Vector__XXX
 SG_ VCFRONT_a033_eccNonCorrectableError m0 : 36|1@1+ (1,0) [0|0] "" Vector__XXX
 SG_ VCFRONT_a093_VCSEATP_MIA m1 : 36|1@1+ (1,0) [0|0] "" Vector__XXX
 SG_ VCFRONT_a153_userPresenceDisplayMismatchClrd m2 : 36|1@1+ (1,0) [0|0] "" Vector__XXX
 SG_ VCFRONT_a213_LVOvercharge m3 : 36|1@1+ (1,0) [0|0] "" Vector__XXX
 SG_ VCFRONT_a273_wiperFrictionModelFault m4 : 36|1@1+ (1,0) [0|0] "" Vector__XXX
 SG_ VCFRONT_a333_vbatFusedSlowTripOC m5 : 36|1@1+ (1,0) [0|0] "" Vector__XXX
 SG_ VCFRONT_a393_ambientTempNetworkSna m6 : 36|1@1+ (1,0) [0|0] "" Vector__XXX
 SG_ VCFRONT_a453_dischargeTempSensIntermittent m7 : 36|1@1+ (1,0) [0|0] "" Vector__XXX
 SG_ VCFRONT_a513_LVBMSFault_MOS_Open_chgOC m8 : 36|1@1+ (1,0) [0|0] "" Vector__XXX
 SG_ VCFRONT_a573_radarEFuseTrip m9 : 36|1@1+ (1,0) [0|0] "" Vector__XXX
 SG_ VCFRONT_a094_EPAS3P_MIA m1 : 37|1@1+ (1,0) [0|0] "" Vector__XXX
 SG_ VCFRONT_a154_prechargeDCRData1 m2 : 37|1@1+ (1,0) [0|0] "" Vector__XXX
 SG_ VCFRONT_a274_failureToPrechargeRisk2 m4 : 37|1@1+ (1,0) [0|0] "" Vector__XXX
 SG_ VCFRONT_a334_vcleftFastTripOCMax m5 : 37|1@1+ (1,0) [0|0] "" Vector__XXX
 SG_ VCFRONT_a394_pressureSensorCheckFault m6 : 37|1@1+ (1,0) [0|0] "" Vector__XXX
 SG_ VCFRONT_a454_suctionPresSensIntermittent m7 : 37|1@1+ (1,0) [0|0] "" Vector__XXX
 SG_ VCFRONT_a514_LVBMSFault_MOS_Open_cellUV m8 : 37|1@1+ (1,0) [0|0] "" Vector__XXX
 SG_ VCFRONT_a574_frontDriveInverterEFuseTrip m9 : 37|1@1+ (1,0) [0|0] "" Vector__XXX
 SG_ VCFRONT_a634_indeterminateSwitchTransitionDetectedDbg m10 : 37|1@1+ (1,0) [0|0] "" Vector__XXX
 SG_ VCFRONT_a095_CHG_MIA m1 : 38|1@1+ (1,0) [0|0] "" Vector__XXX
 SG_ VCFRONT_a155_prechargeDCRData2 m2 : 38|1@1+ (1,0) [0|0] "" Vector__XXX
 SG_ VCFRONT_a275_TLVBMS_BmbCommunication m4 : 38|1@1+ (1,0) [0|0] "" Vector__XXX
 SG_ VCFRONT_a335_vcrightFastTripOCMax m5 : 38|1@1+ (1,0) [0|0] "" Vector__XXX
 SG_ VCFRONT_a395_pressureSensorCheckInconclusive m6 : 38|1@1+ (1,0) [0|0] "" Vector__XXX
 SG_ VCFRONT_a455_suctionTempSensIntermittent m7 : 38|1@1+ (1,0) [0|0] "" Vector__XXX
 SG_ VCFRONT_a515_LVBMSFault_MOS_Open_cellOV m8 : 38|1@1+ (1,0) [0|0] "" Vector__XXX
 SG_ VCFRONT_a575_frontOilPumpEFuseTrip m9 : 38|1@1+ (1,0) [0|0] "" Vector__XXX
 SG_ VCFRONT_a635_rtosSleepFailed m10 : 38|1@1+ (1,0) [0|0] "" Vector__XXX
 SG_ VCFRONT_a096_OCS1P_MIA m1 : 39|1@1+ (1,0) [0|0] "" Vector__XXX
 SG_ VCFRONT_a156_louverBlockage m2 : 39|1@1+ (1,0) [0|0] "" Vector__XXX
 SG_ VCFRONT_a216_powerCutoffImminent m3 : 39|1@1+ (1,0) [0|0] "" Vector__XXX
 SG_ VCFRONT_a276_TLVBMS_BmbDataIntegrityLoss m4 : 39|1@1+ (1,0) [0|0] "" Vector__XXX
 SG_ VCFRONT_a336_pcsFastTripOCMax m5 : 39|1@1+ (1,0) [0|0] "" Vector__XXX
 SG_ VCFRONT_a396_coolantLevelLowUserFacing m6 : 39|1@1+ (1,0) [0|0] "" Vector__XXX
 SG_ VCFRONT_a456_liquidPresSensIntermittent m7 : 39|1@1+ (1,0) [0|0] "" Vector__XXX
 SG_ VCFRONT_a516_hibernationActive m8 : 39|1@1+ (1,0) [0|0] "" Vector__XXX
 SG_ VCFRONT_a576_mcuLogicEFuseTrip m9 : 39|1@1+ (1,0) [0|0] "" Vector__XXX
 SG_ VCFRONT_d636_ptCoolantPumpDetectsAirInSystem m10 : 39|1@1+ (1,0) [0|0] "" Vector__XXX
 SG_ VCFRONT_a097_CMP_MIA m1 : 40|1@1+ (1,0) [0|0] "" Vector__XXX
 SG_ VCFRONT_a157_louverBreakage m2 : 40|1@1+ (1,0) [0|0] "" Vector__XXX
 SG_ VCFRONT_a277_TLVBMS_BmbStatusRegError m4 : 40|1@1+ (1,0) [0|0] "" Vector__XXX
 SG_ VCFRONT_a337_epas3pFastTripOCMax m5 : 40|1@1+ (1,0) [0|0] "" Vector__XXX
 SG_ VCFRONT_a397_temperatureSensorCheckFault m6 : 40|1@1+ (1,0) [0|0] "" Vector__XXX
 SG_ VCFRONT_a457_liquidTempSensIntermittent m7 : 40|1@1+ (1,0) [0|0] "" Vector__XXX
 SG_ VCFRONT_a517_hibernationRecovery m8 : 40|1@1+ (1,0) [0|0] "" Vector__XXX
 SG_ VCFRONT_a577_tasEFuseTrip m9 : 40|1@1+ (1,0) [0|0] "" Vector__XXX
 SG_ VCFRONT_a697_leftHeadlampNotAimed m11 : 40|1@1+ (1,0) [0|0] "" Vector__XXX
 SG_ VCFRONT_d637_battCoolantPumpDetectsAirInSystem m10 : 40|1@1+ (1,0) [0|0] "" Vector__XXX
 SG_ VCFRONT_a038_ProtFaultInfo m0 : 41|1@1+ (1,0) [0|0] "" Vector__XXX
 SG_ VCFRONT_a098_DIR_MIA m1 : 41|1@1+ (1,0) [0|0] "" Vector__XXX
 SG_ VCFRONT_a158_louverDisconnected m2 : 41|1@1+ (1,0) [0|0] "" Vector__XXX
 SG_ VCFRONT_a218_socMonitorDetectedThresholdSoc m3 : 41|1@1+ (1,0) [0|0] "" Vector__XXX
 SG_ VCFRONT_a278_TLVBMS_BmbHwOverCurrentFault m4 : 41|1@1+ (1,0) [0|0] "" Vector__XXX
 SG_ VCFRONT_a338_epas3sFastTripOCMax m5 : 41|1@1+ (1,0) [0|0] "" Vector__XXX
 SG_ VCFRONT_a398_tempSensorCheckInconclusive m6 : 41|1@1+ (1,0) [0|0] "" Vector__XXX
 SG_ VCFRONT_a458_grosslyLowRefrigerant m7 : 41|1@1+ (1,0) [0|0] "" Vector__XXX
 SG_ VCFRONT_a518_LVBMSFault_MOS_Open_packOV m8 : 41|1@1+ (1,0) [0|0] "" Vector__XXX
 SG_ VCFRONT_a578_vbatFusedLowCurrentFeedEFuseTrip m9 : 41|1@1+ (1,0) [0|0] "" Vector__XXX
 SG_ VCFRONT_a698_rightHeadlampNotAimed m11 : 41|1@1+ (1,0) [0|0] "" Vector__XXX
 SG_ VCFRONT_d638_ptCoolantTempSensorIssue m10 : 41|1@1+ (1,0) [0|0] "" Vector__XXX
 SG_ VCFRONT_a039_ProtFaultAddress m0 : 42|1@1+ (1,0) [0|0] "" Vector__XXX
 SG_ VCFRONT_a099_PARK_MIA m1 : 42|1@1+ (1,0) [0|0] "" Vector__XXX
 SG_ VCFRONT_a159_coolantValveFault m2 : 42|1@1+ (1,0) [0|0] "" Vector__XXX
 SG_ VCFRONT_a219_LVVoltFloorRchd m3 : 42|1@1+ (1,0) [0|0] "" Vector__XXX
 SG_ VCFRONT_a279_refrigLiquidTempSns m4 : 42|1@1+ (1,0) [0|0] "" Vector__XXX
 SG_ VCFRONT_a339_iboosterFastTripOCMax m5 : 42|1@1+ (1,0) [0|0] "" Vector__XXX
 SG_ VCFRONT_a399_frunkNeverReportedOpen m6 : 42|1@1+ (1,0) [0|0] "" Vector__XXX
 SG_ VCFRONT_a459_thermalFillAndDrive m7 : 42|1@1+ (1,0) [0|0] "" Vector__XXX
 SG_ VCFRONT_a579_leftHeadlightEFuseTrip m9 : 42|1@1+ (1,0) [0|0] "" Vector__XXX
 SG_ VCFRONT_d639_batteryCoolantTempSensorIssue m10 : 42|1@1+ (1,0) [0|0] "" Vector__XXX
 SG_ VCFRONT_a040_Backtrace m0 : 43|1@1+ (1,0) [0|0] "" Vector__XXX
 SG_ VCFRONT_a100_CANbus_MIA m1 : 43|1@1+ (1,0) [0|0] "" Vector__XXX
 SG_ VCFRONT_a160_compressorInhibited m2 : 43|1@1+ (1,0) [0|0] "" Vector__XXX
 SG_ VCFRONT_a220_reverseBatteryFault m3 : 43|1@1+ (1,0) [0|0] "" Vector__XXX
 SG_ VCFRONT_a280_refrigLiquidPresSns m4 : 43|1@1+ (1,0) [0|0] "" Vector__XXX
 SG_ VCFRONT_a340_espFastTripOCMax m5 : 43|1@1+ (1,0) [0|0] "" Vector__XXX
 SG_ VCFRONT_a400_TLVBMS_BmbVrefBad m6 : 43|1@1+ (1,0) [0|0] "" Vector__XXX
 SG_ VCFRONT_a460_hardIsentropicTdFailed m7 : 43|1@1+ (1,0) [0|0] "" Vector__XXX
 SG_ VCFRONT_a580_rightHeadlightEFuseTrip m9 : 43|1@1+ (1,0) [0|0] "" Vector__XXX
 SG_ VCFRONT_d640_firmwareConfigMismatch m10 : 43|1@1+ (1,0) [0|0] "" Vector__XXX
 SG_ VCFRONT_a041_HighCPULoad m0 : 44|1@1+ (1,0) [0|0] "" Vector__XXX
 SG_ VCFRONT_a101_PM_MIA m1 : 44|1@1+ (1,0) [0|0] "" Vector__XXX
 SG_ VCFRONT_a161_compressorSelfFault m2 : 44|1@1+ (1,0) [0|0] "" Vector__XXX
 SG_ VCFRONT_a221_leftTurnLightFault m3 : 44|1@1+ (1,0) [0|0] "" Vector__XXX
 SG_ VCFRONT_a281_alcoholInterlockBlockingDrive m4 : 44|1@1+ (1,0) [0|0] "" Vector__XXX
 SG_ VCFRONT_a341_vbatFusedFastTripOCMax m5 : 44|1@1+ (1,0) [0|0] "" Vector__XXX
 SG_ VCFRONT_a401_deadLVMinimalAhDischarged m6 : 44|1@1+ (1,0) [0|0] "" Vector__XXX
 SG_ VCFRONT_a461_TLVBMS_SocHighAhError m7 : 44|1@1+ (1,0) [0|0] "" Vector__XXX
 SG_ VCFRONT_a521_vcleftEFuseLoadShed m8 : 44|1@1+ (1,0) [0|0] "" Vector__XXX
 SG_ VCFRONT_a581_windshieldWiperEFuseTrip m9 : 44|1@1+ (1,0) [0|0] "" Vector__XXX
 SG_ VCFRONT_d641_ptCoolantPumpCircuitOpen m10 : 44|1@1+ (1,0) [0|0] "" Vector__XXX
 SG_ VCFRONT_a042_HighStackUsage m0 : 45|1@1+ (1,0) [0|0] "" Vector__XXX
 SG_ VCFRONT_a102_PTC_MIA m1 : 45|1@1+ (1,0) [0|0] "" Vector__XXX
 SG_ VCFRONT_a162_compressorInhibitedContext m2 : 45|1@1+ (1,0) [0|0] "" Vector__XXX
 SG_ VCFRONT_a222_rightTurnLightFault m3 : 45|1@1+ (1,0) [0|0] "" Vector__XXX
 SG_ VCFRONT_a282_coolantLevelSensorFault m4 : 45|1@1+ (1,0) [0|0] "" Vector__XXX
 SG_ VCFRONT_a342_vcleftFastTripSlope m5 : 45|1@1+ (1,0) [0|0] "" Vector__XXX
 SG_ VCFRONT_a402_LVBatteryCannotSupportVehicle m6 : 45|1@1+ (1,0) [0|0] "" Vector__XXX
 SG_ VCFRONT_a462_LVBMSFault m7 : 45|1@1+ (1,0) [0|0] "" Vector__XXX
 SG_ VCFRONT_a522_hibernationActiveLogCapture m8 : 45|1@1+ (1,0) [0|0] "" Vector__XXX
 SG_ VCFRONT_a582_goodForPCSPowerCycle m9 : 45|1@1+ (1,0) [0|0] "" Vector__XXX
 SG_ VCFRONT_d642_batteryCoolantPumpCircuitOpen m10 : 45|1@1+ (1,0) [0|0] "" Vector__XXX
 SG_ VCFRONT_a043_Task1msError m0 : 46|1@1+ (1,0) [0|0] "" Vector__XXX
 SG_ VCFRONT_a103_CP_MIA m1 : 46|1@1+ (1,0) [0|0] "" Vector__XXX
 SG_ VCFRONT_a163_compressorDisabledFSR m2 : 46|1@1+ (1,0) [0|0] "" Vector__XXX
 SG_ VCFRONT_a223_12VTempSensDiscnect m3 : 46|1@1+ (1,0) [0|0] "" Vector__XXX
 SG_ VCFRONT_a283_thmlFanLimitedByCurrent m4 : 46|1@1+ (1,0) [0|0] "" Vector__XXX
 SG_ VCFRONT_a343_vcrightFastTripSlope m5 : 46|1@1+ (1,0) [0|0] "" Vector__XXX
 SG_ VCFRONT_a403_chargeExitHardCurrentLimit m6 : 46|1@1+ (1,0) [0|0] "" Vector__XXX
 SG_ VCFRONT_a463_frunkSensorService m7 : 46|1@1+ (1,0) [0|0] "" Vector__XXX
 SG_ VCFRONT_a523_eFuseThresholdsIncorrect m8 : 46|1@1+ (1,0) [0|0] "" Vector__XXX
 SG_ VCFRONT_a583_frunkSwitchGroupDisagreementDebug m9 : 46|1@1+ (1,0) [0|0] "" Vector__XXX
 SG_ VCFRONT_a643_rightHeadlampUartCondition m10 : 46|1@1+ (1,0) [0|0] "" Vector__XXX
 SG_ VCFRONT_a044_Task10msError m0 : 47|1@1+ (1,0) [0|0] "" Vector__XXX
 SG_ VCFRONT_a104_DAS_MIA m1 : 47|1@1+ (1,0) [0|0] "" Vector__XXX
 SG_ VCFRONT_a164_eFuseLckoutMissing m2 : 47|1@1+ (1,0) [0|0] "" Vector__XXX
 SG_ VCFRONT_a224_revBatChrgPmpFault m3 : 47|1@1+ (1,0) [0|0] "" Vector__XXX
 SG_ VCFRONT_a284_chillerExvFault m4 : 47|1@1+ (1,0) [0|0] "" Vector__XXX
 SG_ VCFRONT_a344_pcsFastTripSlope m5 : 47|1@1+ (1,0) [0|0] "" Vector__XXX
 SG_ VCFRONT_a404_resistanceEstimationHardFailure m6 : 47|1@1+ (1,0) [0|0] "" Vector__XXX
 SG_ VCFRONT_a464_highFlowIndexHighSubcoolFlagged m7 : 47|1@1+ (1,0) [0|0] "" Vector__XXX
 SG_ VCFRONT_a524_rightHeadlampAimingFault m8 : 47|1@1+ (1,0) [0|0] "" Vector__XXX
 SG_ VCFRONT_a584_frunkSwitchGroupDebug m9 : 47|1@1+ (1,0) [0|0] "" Vector__XXX
 SG_ VCFRONT_a644_washPumpHealthCalculationDbg0 m10 : 47|1@1+ (1,0) [0|0] "" Vector__XXX
 SG_ VCFRONT_a045_Task100msError m0 : 48|1@1+ (1,0) [0|0] "" Vector__XXX
 SG_ VCFRONT_a105_TAS_MIA m1 : 48|1@1+ (1,0) [0|0] "" Vector__XXX
 SG_ VCFRONT_a165_unxpctdEFuseLckout m2 : 48|1@1+ (1,0) [0|0] "" Vector__XXX
 SG_ VCFRONT_a225_driveBlckdByShowroom m3 : 48|1@1+ (1,0) [0|0] "" Vector__XXX
 SG_ VCFRONT_a285_evaporatorExvFault m4 : 48|1@1+ (1,0) [0|0] "" Vector__XXX
 SG_ VCFRONT_a345_epas3pFastTripSlope m5 : 48|1@1+ (1,0) [0|0] "" Vector__XXX
 SG_ VCFRONT_a405_dcrData1 m6 : 48|1@1+ (1,0) [0|0] "" Vector__XXX
 SG_ VCFRONT_a465_lowFlowIndexHighSubcoolFlagged m7 : 48|1@1+ (1,0) [0|0] "" Vector__XXX
 SG_ VCFRONT_a525_LVBatterySWMisconfiguration m8 : 48|1@1+ (1,0) [0|0] "" Vector__XXX
 SG_ VCFRONT_a585_bothHeadlampsInternalError m9 : 48|1@1+ (1,0) [0|0] "" Vector__XXX
 SG_ VCFRONT_a645_washPumpHealthCalculationDbg1 m10 : 48|1@1+ (1,0) [0|0] "" Vector__XXX
 SG_ VCFRONT_a046_Task1000msError m0 : 49|1@1+ (1,0) [0|0] "" Vector__XXX
 SG_ VCFRONT_a106_PCS_MIA m1 : 49|1@1+ (1,0) [0|0] "" Vector__XXX
 SG_ VCFRONT_a166_rightHCMMIA m2 : 49|1@1+ (1,0) [0|0] "" Vector__XXX
 SG_ VCFRONT_a286_recircExvFault m4 : 49|1@1+ (1,0) [0|0] "" Vector__XXX
 SG_ VCFRONT_a346_epas3sFastTripSlope m5 : 49|1@1+ (1,0) [0|0] "" Vector__XXX
 SG_ VCFRONT_a406_dcrData2 m6 : 49|1@1+ (1,0) [0|0] "" Vector__XXX
 SG_ VCFRONT_a466_highFlowIndexLowSubcoolFlagged m7 : 49|1@1+ (1,0) [0|0] "" Vector__XXX
 SG_ VCFRONT_a586_rightLowOrHighBeamLightCondition m9 : 49|1@1+ (1,0) [0|0] "" Vector__XXX
 SG_ VCFRONT_a646_washPumpHealthCalculationDbg2 m10 : 49|1@1+ (1,0) [0|0] "" Vector__XXX
 SG_ VCFRONT_a047_resetReason m0 : 50|1@1+ (1,0) [0|0] "" Vector__XXX
 SG_ VCFRONT_a107_BMS_MIA m1 : 50|1@1+ (1,0) [0|0] "" Vector__XXX
 SG_ VCFRONT_a167_leftHCMMIA m2 : 50|1@1+ (1,0) [0|0] "" Vector__XXX
 SG_ VCFRONT_a287_lccExvFault m4 : 50|1@1+ (1,0) [0|0] "" Vector__XXX
 SG_ VCFRONT_a347_iboosterFastTripSlope m5 : 50|1@1+ (1,0) [0|0] "" Vector__XXX
 SG_ VCFRONT_a407_dcrMilliOhmsAboveThreshold m6 : 50|1@1+ (1,0) [0|0] "" Vector__XXX
 SG_ VCFRONT_a467_lowPowerIndexFlagged m7 : 50|1@1+ (1,0) [0|0] "" Vector__XXX
 SG_ VCFRONT_a527_LVBatteryCellImbalance m8 : 50|1@1+ (1,0) [0|0] "" Vector__XXX
 SG_ VCFRONT_a587_externalLVPowerSupply m9 : 50|1@1+ (1,0) [0|0] "" Vector__XXX
 SG_ VCFRONT_d647_louverCommLost m10 : 50|1@1+ (1,0) [0|0] "" Vector__XXX
 SG_ VCFRONT_a108_DIF_MIA m1 : 51|1@1+ (1,0) [0|0] "" Vector__XXX
 SG_ VCFRONT_a168_hcmShortToVBAT m2 : 51|1@1+ (1,0) [0|0] "" Vector__XXX
 SG_ VCFRONT_a228_pumpBatFbkSanity m3 : 51|1@1+ (1,0) [0|0] "" Vector__XXX
 SG_ VCFRONT_a288_ccLeftExvFault m4 : 51|1@1+ (1,0) [0|0] "" Vector__XXX
 SG_ VCFRONT_a348_espFastTripSlope m5 : 51|1@1+ (1,0) [0|0] "" Vector__XXX
 SG_ VCFRONT_a408_standbyChargeProfileHardExit m6 : 51|1@1+ (1,0) [0|0] "" Vector__XXX
 SG_ VCFRONT_a468_highPowerIndexFlagged m7 : 51|1@1+ (1,0) [0|0] "" Vector__XXX
 SG_ VCFRONT_a528_LVBatteryCommsDiscnctd m8 : 51|1@1+ (1,0) [0|0] "" Vector__XXX
 SG_ VCFRONT_a588_vcleftPwrRationalityCurve m9 : 51|1@1+ (1,0) [0|0] "" Vector__XXX
 SG_ VCFRONT_d648_louverBlocked m10 : 51|1@1+ (1,0) [0|0] "" Vector__XXX
 SG_ VCFRONT_a109_RCM_MIA m1 : 52|1@1+ (1,0) [0|0] "" Vector__XXX
 SG_ VCFRONT_a169_hcmPhaseEnableFail m2 : 52|1@1+ (1,0) [0|0] "" Vector__XXX
 SG_ VCFRONT_a229_pumpPtFbkSanity m3 : 52|1@1+ (1,0) [0|0] "" Vector__XXX
 SG_ VCFRONT_a289_ccRightExvFault m4 : 52|1@1+ (1,0) [0|0] "" Vector__XXX
 SG_ VCFRONT_a349_vbatFusedFastTripSlope m5 : 52|1@1+ (1,0) [0|0] "" Vector__XXX
 SG_ VCFRONT_a409_invalidConfiguration m6 : 52|1@1+ (1,0) [0|0] "" Vector__XXX
 SG_ VCFRONT_a469_prvPopDetected m7 : 52|1@1+ (1,0) [0|0] "" Vector__XXX
 SG_ VCFRONT_a529_discnctdBatteryStateUnknown m8 : 52|1@1+ (1,0) [0|0] "" Vector__XXX
 SG_ VCFRONT_a589_vcleftFastBlowDetection m9 : 52|1@1+ (1,0) [0|0] "" Vector__XXX
 SG_ VCFRONT_a649_persistAccPortPowerReqOverridden m10 : 52|1@1+ (1,0) [0|0] "" Vector__XXX
 SG_ VCFRONT_a110_GTW_MIA m1 : 53|1@1+ (1,0) [0|0] "" Vector__XXX
 SG_ VCFRONT_a170_hcmUnderVoltage m2 : 53|1@1+ (1,0) [0|0] "" Vector__XXX
 SG_ VCFRONT_a230_thmlFanFbkSanity m3 : 53|1@1+ (1,0) [0|0] "" Vector__XXX
 SG_ VCFRONT_a290_leftFogLightFault m4 : 53|1@1+ (1,0) [0|0] "" Vector__XXX
 SG_ VCFRONT_a350_espValveCurrentSenseSaturated m5 : 53|1@1+ (1,0) [0|0] "" Vector__XXX
 SG_ VCFRONT_a410_LVBatteryDataCollection1 m6 : 53|1@1+ (1,0) [0|0] "" Vector__XXX
 SG_ VCFRONT_a470_implausiblePdPlDetected m7 : 53|1@1+ (1,0) [0|0] "" Vector__XXX
 SG_ VCFRONT_a530_sharpCurrentRise m8 : 53|1@1+ (1,0) [0|0] "" Vector__XXX
 SG_ VCFRONT_a590_vcrightPwrRationalityCurve m9 : 53|1@1+ (1,0) [0|0] "" Vector__XXX
 SG_ VCFRONT_d650_lowCoolantLevel m10 : 53|1@1+ (1,0) [0|0] "" Vector__XXX
 SG_ VCFRONT_a111_EPBR_MIA m1 : 54|1@1+ (1,0) [0|0] "" Vector__XXX
 SG_ VCFRONT_a171_driveBlckdByMsmtch m2 : 54|1@1+ (1,0) [0|0] "" Vector__XXX
 SG_ VCFRONT_a231_12VTempSensShort m3 : 54|1@1+ (1,0) [0|0] "" Vector__XXX
 SG_ VCFRONT_a291_rightFogLightFault m4 : 54|1@1+ (1,0) [0|0] "" Vector__XXX
 SG_ VCFRONT_a351_emergencyFrunkButtonPressIgnored m5 : 54|1@1+ (1,0) [0|0] "" Vector__XXX
 SG_ VCFRONT_a411_LVBatteryDataCollection2 m6 : 54|1@1+ (1,0) [0|0] "" Vector__XXX
 SG_ VCFRONT_a531_lowPowerIndexFlaggedUserFacing m8 : 54|1@1+ (1,0) [0|0] "" Vector__XXX
 SG_ VCFRONT_a591_vcrightFastBlowDetection m9 : 54|1@1+ (1,0) [0|0] "" Vector__XXX
 SG_ VCFRONT_d651_ptCoolantPumpStall m10 : 54|1@1+ (1,0) [0|0] "" Vector__XXX
 SG_ VCFRONT_a112_EPBL_MIA m1 : 55|1@1+ (1,0) [0|0] "" Vector__XXX
 SG_ VCFRONT_a172_wsteHtBlckdByMsmtch m2 : 55|1@1+ (1,0) [0|0] "" Vector__XXX
 SG_ VCFRONT_a232_lowSideControllerHighFdbk m3 : 55|1@1+ (1,0) [0|0] "" Vector__XXX
 SG_ VCFRONT_a292_sideMarkerLightPipeFault m4 : 55|1@1+ (1,0) [0|0] "" Vector__XXX
 SG_ VCFRONT_a352_audioCurrentSpikeData m5 : 55|1@1+ (1,0) [0|0] "" Vector__XXX
 SG_ VCFRONT_a412_dcrData3 m6 : 55|1@1+ (1,0) [0|0] "" Vector__XXX
 SG_ VCFRONT_a472_leftHeadlampRangeUpdate m7 : 55|1@1+ (1,0) [0|0] "" Vector__XXX
 SG_ VCFRONT_a532_gtwMIAInDrive m8 : 55|1@1+ (1,0) [0|0] "" Vector__XXX
 SG_ VCFRONT_a592_vcleftCurvePowerCutoff m9 : 55|1@1+ (1,0) [0|0] "" Vector__XXX
 SG_ VCFRONT_d652_ptCoolantPumpCircuitIssue m10 : 55|1@1+ (1,0) [0|0] "" Vector__XXX
 SG_ VCFRONT_a053_wiperCommErrorUser m0 : 56|1@1+ (1,0) [0|0] "" Vector__XXX
 SG_ VCFRONT_a113_UI_MIA m1 : 56|1@1+ (1,0) [0|0] "" Vector__XXX
 SG_ VCFRONT_a173_HVBlckdByMsmtch m2 : 56|1@1+ (1,0) [0|0] "" Vector__XXX
 SG_ VCFRONT_a233_autopilot1EFuseFault m3 : 56|1@1+ (1,0) [0|0] "" Vector__XXX
 SG_ VCFRONT_a293_interiorFrunkLightFault m4 : 56|1@1+ (1,0) [0|0] "" Vector__XXX
 SG_ VCFRONT_a353_wiperHeaterUndercurrent m5 : 56|1@1+ (1,0) [0|0] "" Vector__XXX
 SG_ VCFRONT_a413_TLVBMS_BmbVrefWarning m6 : 56|1@1+ (1,0) [0|0] "" Vector__XXX
 SG_ VCFRONT_a473_rightHeadlampRangeUpdate m7 : 56|1@1+ (1,0) [0|0] "" Vector__XXX
 SG_ VCFRONT_a533_TLVBMS_MosfetOverTemperatureFault m8 : 56|1@1+ (1,0) [0|0] "" Vector__XXX
 SG_ VCFRONT_a593_vcleftFastBlowPowerCutoff m9 : 56|1@1+ (1,0) [0|0] "" Vector__XXX
 SG_ VCFRONT_d653_ptCoolantPumpCommLost m10 : 56|1@1+ (1,0) [0|0] "" Vector__XXX
 SG_ VCFRONT_a054_compressorLowFlowUserFacing m0 : 57|1@1+ (1,0) [0|0] "" Vector__XXX
 SG_ VCFRONT_a114_ESP_MIA m1 : 57|1@1+ (1,0) [0|0] "" Vector__XXX
 SG_ VCFRONT_a174_driveNotAuthed m2 : 57|1@1+ (1,0) [0|0] "" Vector__XXX
 SG_ VCFRONT_a234_autopilot2EFuseFault m3 : 57|1@1+ (1,0) [0|0] "" Vector__XXX
 SG_ VCFRONT_a294_leftSideRepeaterLightFault m4 : 57|1@1+ (1,0) [0|0] "" Vector__XXX
 SG_ VCFRONT_a354_windshieldCameraHeaterUndercurrent m5 : 57|1@1+ (1,0) [0|0] "" Vector__XXX
 SG_ VCFRONT_a414_prechargeLVLoadReduction m6 : 57|1@1+ (1,0) [0|0] "" Vector__XXX
 SG_ VCFRONT_a474_leftHeadlampInternalError m7 : 57|1@1+ (1,0) [0|0] "" Vector__XXX
 SG_ VCFRONT_a534_chillerExvCalibInitDebug m8 : 57|1@1+ (1,0) [0|0] "" Vector__XXX
 SG_ VCFRONT_a594_virtualPitchConversionDebug m9 : 57|1@1+ (1,0) [0|0] "" Vector__XXX
 SG_ VCFRONT_d654_batteryCoolantPumpStall m10 : 57|1@1+ (1,0) [0|0] "" Vector__XXX
 SG_ VCFRONT_a115_VCSEC_MIA m1 : 58|1@1+ (1,0) [0|0] "" Vector__XXX
 SG_ VCFRONT_a175_ambientTempSns m2 : 58|1@1+ (1,0) [0|0] "" Vector__XXX
 SG_ VCFRONT_a235_ptTempSnsIrrational m3 : 58|1@1+ (1,0) [0|0] "" Vector__XXX
 SG_ VCFRONT_a295_rightSideRepeaterLightFault m4 : 58|1@1+ (1,0) [0|0] "" Vector__XXX
 SG_ VCFRONT_a355_coolantSysLockout m5 : 58|1@1+ (1,0) [0|0] "" Vector__XXX
 SG_ VCFRONT_a415_prechargeLVLoadReduction2 m6 : 58|1@1+ (1,0) [0|0] "" Vector__XXX
 SG_ VCFRONT_a475_rightHeadlampInternalError m7 : 58|1@1+ (1,0) [0|0] "" Vector__XXX
 SG_ VCFRONT_a535_evapExvCalibInitDebug m8 : 58|1@1+ (1,0) [0|0] "" Vector__XXX
 SG_ VCFRONT_a595_voltageSensorMismatch m9 : 58|1@1+ (1,0) [0|0] "" Vector__XXX
 SG_ VCFRONT_d655_batteryCoolantPumpCircuitIssue m10 : 58|1@1+ (1,0) [0|0] "" Vector__XXX
 SG_ VCFRONT_a116_VCRIGHT_MIA m1 : 59|1@1+ (1,0) [0|0] "" Vector__XXX
 SG_ VCFRONT_a176_vehicleInSelfTest m2 : 59|1@1+ (1,0) [0|0] "" Vector__XXX
 SG_ VCFRONT_a236_batTempSnsIrrational m3 : 59|1@1+ (1,0) [0|0] "" Vector__XXX
 SG_ VCFRONT_a296_turnSignalIssue m4 : 59|1@1+ (1,0) [0|0] "" Vector__XXX
 SG_ VCFRONT_a356_refrigSysLockout m5 : 59|1@1+ (1,0) [0|0] "" Vector__XXX
 SG_ VCFRONT_a416_TLVBMS_BrickOverDischarged m6 : 59|1@1+ (1,0) [0|0] "" Vector__XXX
 SG_ VCFRONT_a476_LVBMSMIA m7 : 59|1@1+ (1,0) [0|0] "" Vector__XXX
 SG_ VCFRONT_a536_recircExvCalibInitDebug m8 : 59|1@1+ (1,0) [0|0] "" Vector__XXX
 SG_ VCFRONT_a596_vcrightCurvePowerCutoff m9 : 59|1@1+ (1,0) [0|0] "" Vector__XXX
 SG_ VCFRONT_d656_batteryCoolantPumpCommLost m10 : 59|1@1+ (1,0) [0|0] "" Vector__XXX
 SG_ VCFRONT_a057_HVP_MIA m0 : 60|1@1+ (1,0) [0|0] "" Vector__XXX
 SG_ VCFRONT_a117_VCLEFT_MIA m1 : 60|1@1+ (1,0) [0|0] "" Vector__XXX
 SG_ VCFRONT_a177_mcuAudioEFuseFault m2 : 60|1@1+ (1,0) [0|0] "" Vector__XXX
 SG_ VCFRONT_a237_pumpBatChipComms m3 : 60|1@1+ (1,0) [0|0] "" Vector__XXX
 SG_ VCFRONT_a297_TLVBMS_BmbHwOverTemperatureFault m4 : 60|1@1+ (1,0) [0|0] "" Vector__XXX
 SG_ VCFRONT_a357_hornUndercurrent m5 : 60|1@1+ (1,0) [0|0] "" Vector__XXX
 SG_ VCFRONT_a417_TLVBMS_BrickOverVoltageFault m6 : 60|1@1+ (1,0) [0|0] "" Vector__XXX
 SG_ VCFRONT_a477_LVBatteryUnrecoverableByVehicle m7 : 60|1@1+ (1,0) [0|0] "" Vector__XXX
 SG_ VCFRONT_a537_lccExvCalibInitDebug m8 : 60|1@1+ (1,0) [0|0] "" Vector__XXX
 SG_ VCFRONT_a597_vcrightFastBlowPowerCutoff m9 : 60|1@1+ (1,0) [0|0] "" Vector__XXX
 SG_ VCFRONT_d657_radiatorFanOperationIssue m10 : 60|1@1+ (1,0) [0|0] "" Vector__XXX
 SG_ VCFRONT_a058_inputRHighSyncDebug m0 : 61|1@1+ (1,0) [0|0] "" Vector__XXX
 SG_ VCFRONT_a118_VCFRONT_MIA m1 : 61|1@1+ (1,0) [0|0] "" Vector__XXX
 SG_ VCFRONT_a178_compLiquidPumpOut m2 : 61|1@1+ (1,0) [0|0] "" Vector__XXX
 SG_ VCFRONT_a238_pumpPtChipComms m3 : 61|1@1+ (1,0) [0|0] "" Vector__XXX
 SG_ VCFRONT_a298_radiatorLowAirFlowDetected m4 : 61|1@1+ (1,0) [0|0] "" Vector__XXX
 SG_ VCFRONT_a358_hornOvercurrent m5 : 61|1@1+ (1,0) [0|0] "" Vector__XXX
 SG_ VCFRONT_a418_TLVBMS_BrickOverVoltageWarning m6 : 61|1@1+ (1,0) [0|0] "" Vector__XXX
 SG_ VCFRONT_a478_LVBMS_MOSFET_Open m7 : 61|1@1+ (1,0) [0|0] "" Vector__XXX
 SG_ VCFRONT_a538_cclExvCalibInitDebug m8 : 61|1@1+ (1,0) [0|0] "" Vector__XXX
 SG_ VCFRONT_a598_eFuseSelfTestFailureService m9 : 61|1@1+ (1,0) [0|0] "" Vector__XXX
 SG_ VCFRONT_d658_radiatorFanCircuitIssue m10 : 61|1@1+ (1,0) [0|0] "" Vector__XXX
 SG_ VCFRONT_a059_inputResistanceHigh m0 : 62|1@1+ (1,0) [0|0] "" Vector__XXX
 SG_ VCFRONT_a119_SCCM_MIA m1 : 62|1@1+ (1,0) [0|0] "" Vector__XXX
 SG_ VCFRONT_a179_highLVAmpsIntoPCS m2 : 62|1@1+ (1,0) [0|0] "" Vector__XXX
 SG_ VCFRONT_a239_thmlFanChipComms m3 : 62|1@1+ (1,0) [0|0] "" Vector__XXX
 SG_ VCFRONT_a299_homelinkConfigurationFailed m4 : 62|1@1+ (1,0) [0|0] "" Vector__XXX
 SG_ VCFRONT_a359_postPORExcessiveAh m5 : 62|1@1+ (1,0) [0|0] "" Vector__XXX
 SG_ VCFRONT_a419_TLVBMS_BrickSocLow m6 : 62|1@1+ (1,0) [0|0] "" Vector__XXX
 SG_ VCFRONT_a479_LVBMS_ECPA_NotClosed m7 : 62|1@1+ (1,0) [0|0] "" Vector__XXX
 SG_ VCFRONT_a539_ccrExvCalibInitDebug m8 : 62|1@1+ (1,0) [0|0] "" Vector__XXX
 SG_ VCFRONT_a599_LVBatteryTypeUnsupported m9 : 62|1@1+ (1,0) [0|0] "" Vector__XXX
 SG_ VCFRONT_d659_radiatorFanCommLost m10 : 62|1@1+ (1,0) [0|0] "" Vector__XXX
 SG_ VCFRONT_a060_engineeringBuild m0 : 63|1@1+ (1,0) [0|0] "" Vector__XXX
 SG_ VCFRONT_a120_DI_DRIVE_MIA m1 : 63|1@1+ (1,0) [0|0] "" Vector__XXX
 SG_ VCFRONT_a180_DCDCNotSupportingLVBus m2 : 63|1@1+ (1,0) [0|0] "" Vector__XXX
 SG_ VCFRONT_a240_lowSideCompromised m3 : 63|1@1+ (1,0) [0|0] "" Vector__XXX
 SG_ VCFRONT_a300_louverActuatorSwapDetected m4 : 63|1@1+ (1,0) [0|0] "" Vector__XXX
 SG_ VCFRONT_a360_ungracefulAccPlusExit m5 : 63|1@1+ (1,0) [0|0] "" Vector__XXX
 SG_ VCFRONT_a420_holidayParty m6 : 63|1@1+ (1,0) [0|0] "" Vector__XXX
 SG_ VCFRONT_a480_vnf1048Fault m7 : 63|1@1+ (1,0) [0|0] "" Vector__XXX
 SG_ VCFRONT_a540_radiatorSteamDetected m8 : 63|1@1+ (1,0) [0|0] "" Vector__XXX
 SG_ VCFRONT_a600_currentSensorMismatch m9 : 63|1@1+ (1,0) [0|0] "" Vector__XXX
 SG_ VCFRONT_d660_coolantValveCircuitIssue m10 : 63|1@1+ (1,0) [0|0] "" Vector__XXX

BO_ 838 GTW_autopilotOverride: 8 Vector__XXX
 SG_ GTW_autopilotOverrideState : 0|4@1+ (1,0) [0|0] "" Vector__XXX
 SG_ GTW_autopilotConfig : 4|3@1+ (1,0) [0|0] "" Vector__XXX
 SG_ GTW_autopilotOverrideConfig : 8|3@1+ (1,0) [0|0] "" Vector__XXX
 SG_ GTW_autopilotConfigSource : 11|2@1+ (1,0) [0|0] "" Vector__XXX
 SG_ GTW_autopilotOverrideExpireTime : 32|32@1+ (1,0) [0|0] "" Vector__XXX

BO_ 840 GTW_status: 8 Vector__XXX
 SG_ GTW_vehicleVersionMatchStatus : 0|2@1+ (1,0) [0|0] "" Vector__XXX
 SG_ GTW_hwtype : 2|2@1+ (1,0) [0|0] "" Vector__XXX
 SG_ GTW_jcanProductName : 4|4@1+ (1,0) [0|0] "" Vector__XXX
 SG_ GTW_uptimeSeconds : 15|32@0+ (1,0) [0|0] "" Vector__XXX
 SG_ GTW_boardRevision : 40|8@1+ (1,0) [0|0] "" Vector__XXX
 SG_ GTW_touchcoreOsType : 48|1@1+ (1,0) [0|0] "" Vector__XXX
 SG_ GTW_sentryModeState : 49|3@1+ (1,0) [0|0] "" Vector__XXX
 SG_ GTW_secureBootEnabled : 52|1@1+ (1,0) [0|0] "" Vector__XXX
 SG_ GTW_socSleepType : 56|2@1+ (1,0) [0|0] "" Vector__XXX
 SG_ GTW_resetType : 58|3@1+ (1,0) [0|0] "" Vector__XXX

BO_ 841 DAS_warningMatrix2: 8 Vector__XXX
 SG_ DAS_w129_mainCamExtNotCal : 0|1@1+ (1,0) [0|0] "" Vector__XXX
 SG_ DAS_w130_narrowCamExtNotCal : 1|1@1+ (1,0) [0|0] "" Vector__XXX
 SG_ DAS_w131_mainCamCalSaved : 2|1@1+ (1,0) [0|0] "" Vector__XXX
 SG_ DAS_w132_narrowCamCalSaved : 3|1@1+ (1,0) [0|0] "" Vector__XXX
 SG_ DAS_w133_mainCamInitFault : 4|1@1+ (1,0) [0|0] "" Vector__XXX
 SG_ DAS_w134_narrowCamInitFault : 5|1@1+ (1,0) [0|0] "" Vector__XXX
 SG_ DAS_w135_fisheyeCamInitFault : 6|1@1+ (1,0) [0|0] "" Vector__XXX
 SG_ DAS_w136_lPillarCamInitFault : 7|1@1+ (1,0) [0|0] "" Vector__XXX
 SG_ DAS_w137_rPillarCamInitFault : 8|1@1+ (1,0) [0|0] "" Vector__XXX
 SG_ DAS_w138_lRepeatCamInitFault : 9|1@1+ (1,0) [0|0] "" Vector__XXX
 SG_ DAS_w139_rRepeatCamInitFault : 10|1@1+ (1,0) [0|0] "" Vector__XXX
 SG_ DAS_w140_backupCamInitFault : 11|1@1+ (1,0) [0|0] "" Vector__XXX
 SG_ DAS_w141_ECU_Thermal_Issue : 12|1@1+ (1,0) [0|0] "" Vector__XXX
 SG_ DAS_w142_fwdCamPitchProblem : 13|1@1+ (1,0) [0|0] "" Vector__XXX
 SG_ DAS_w143_IDF_event : 14|1@1+ (1,0) [0|0] "" Vector__XXX
 SG_ DAS_w144_selfieCamInitFault : 15|1@1+ (1,0) [0|0] "" Vector__XXX
 SG_ DAS_w171_fisheyeCamExtNotCal : 42|1@1+ (1,0) [0|0] "" Vector__XXX
 SG_ DAS_w172_lPillarCamExtNotCal : 43|1@1+ (1,0) [0|0] "" Vector__XXX
 SG_ DAS_w173_rPillarCamExtNotCal : 44|1@1+ (1,0) [0|0] "" Vector__XXX
 SG_ DAS_w174_lRepeatCamExtNotCal : 45|1@1+ (1,0) [0|0] "" Vector__XXX
 SG_ DAS_w175_rRepeatCamExtNotCal : 46|1@1+ (1,0) [0|0] "" Vector__XXX
 SG_ DAS_w177_fisheyeCamCalSaved : 48|1@1+ (1,0) [0|0] "" Vector__XXX
 SG_ DAS_w178_lPillarCamCalSaved : 49|1@1+ (1,0) [0|0] "" Vector__XXX
 SG_ DAS_w179_rPillarCamCalSaved : 50|1@1+ (1,0) [0|0] "" Vector__XXX
 SG_ DAS_w180_lRepeatCamCalSaved : 51|1@1+ (1,0) [0|0] "" Vector__XXX
 SG_ DAS_w181_rRepeatCamCalSaved : 52|1@1+ (1,0) [0|0] "" Vector__XXX

BO_ 843 APP_frontParkAssistData: 8 Vector__XXX
 SG_ APP_frontLeftParkAssist : 0|8@1+ (1,0) [0|0] "" Vector__XXX
 SG_ APP_frontLeftMiddleParkAssist : 8|8@1+ (1,0) [0|0] "" Vector__XXX
 SG_ APP_frontMiddleParkAssist : 16|8@1+ (1,0) [0|0] "" Vector__XXX
 SG_ APP_frontRightMiddleParkAssist : 24|8@1+ (1,0) [0|0] "" Vector__XXX
 SG_ APP_frontRightParkAssist : 32|8@1+ (1,0) [0|0] "" Vector__XXX
 SG_ APP_parkAssistStatus : 40|2@1+ (1,0) [0|0] "" Vector__XXX
 SG_ APP_useParkDistancesFromAP : 42|1@1+ (1,0) [0|0] "" Vector__XXX

BO_ 846 PARK_pasFrontMiddle: 8 Vector__XXX
 SG_ PARK_frontLeftMiddleRawDistData : 0|8@1+ (1,0) [0|0] "" Vector__XXX
 SG_ PARK_frontMiddleRawDistData : 8|8@1+ (1,0) [0|0] "" Vector__XXX
 SG_ PARK_frontRightMiddleRawDistData : 16|8@1+ (1,0) [0|0] "" Vector__XXX
 SG_ PARK_pasFrontMiddleCounter : 24|4@1+ (1,0) [0|0] "" Vector__XXX
 SG_ PARK_pasFrontMiddleChecksum : 32|8@1+ (1,0) [0|0] "" Vector__XXX

BO_ 847 OCS1P_debugCushionSelfCNTComp: 8 Vector__XXX
 SG_ OCS1P_cushionSelfCNTFreqComp : 0|16@1+ (1,0) [0|0] "" Vector__XXX
 SG_ OCS1P_cushionSelfCNTCap : 16|16@1+ (0.005,0) [0|0] "" Vector__XXX
 SG_ OCS1P_deltaFreqCushionSelf : 32|16@1- (1,0) [0|0] "" Vector__XXX
 SG_ OCS1P_deltaCapCushionSelf : 48|16@1- (0.0025,0) [0|0] "" Vector__XXX

BO_ 848 APS_warningMatrix3: 8 Vector__XXX
 SG_ APS_w193_camWindshieldUnclean : 0|1@1+ (1,0) [0|0] "" Vector__XXX
 SG_ APS_w194_accDriverResumeRqrd : 1|1@1+ (1,0) [0|0] "" Vector__XXX
 SG_ APS_w195_scwUnavailable : 2|1@1+ (1,0) [0|0] "" Vector__XXX
 SG_ APS_w196_stopSignWarning : 3|1@1+ (1,0) [0|0] "" Vector__XXX
 SG_ APS_w197_redLightWarning : 4|1@1+ (1,0) [0|0] "" Vector__XXX
 SG_ APS_w198_tsrUnavailable : 5|1@1+ (1,0) [0|0] "" Vector__XXX
 SG_ APS_w199_apcAbort : 6|1@1+ (1,0) [0|0] "" Vector__XXX
 SG_ APS_w200_lcSlowdown : 7|1@1+ (1,0) [0|0] "" Vector__XXX
 SG_ APS_w201_lcAborting : 8|1@1+ (1,0) [0|0] "" Vector__XXX
 SG_ APS_w202_scwNoisyEnvironment : 9|1@1+ (1,0) [0|0] "" Vector__XXX
 SG_ APS_w203_apcActivation : 10|1@1+ (1,0) [0|0] "" Vector__XXX
 SG_ APS_w204_apcFinalFront : 11|1@1+ (1,0) [0|0] "" Vector__XXX
 SG_ APS_w205_apcFinalRear : 12|1@1+ (1,0) [0|0] "" Vector__XXX
 SG_ APS_w206_autosteerNotEnabled : 13|1@1+ (1,0) [0|0] "" Vector__XXX
 SG_ APS_w207_autosteerUnavailable : 14|1@1+ (1,0) [0|0] "" Vector__XXX
 SG_ APS_w208_rackDetected : 15|1@1+ (1,0) [0|0] "" Vector__XXX
 SG_ APS_w209_autoSummonRequest : 16|1@1+ (1,0) [0|0] "" Vector__XXX
 SG_ APS_w210_camObstrcted : 17|1@1+ (1,0) [0|0] "" Vector__XXX
 SG_ APS_w211_accNoSeatBelt : 18|1@1+ (1,0) [0|0] "" Vector__XXX
 SG_ APS_w212_lcUnavailableStrikeOut : 19|1@1+ (1,0) [0|0] "" Vector__XXX
 SG_ APS_w213_autosteerStruckOut : 20|1@1+ (1,0) [0|0] "" Vector__XXX
 SG_ APS_w214_driverNotIntracting : 21|1@1+ (1,0) [0|0] "" Vector__XXX
 SG_ APS_w215_contDriverNotIntracting : 22|1@1+ (1,0) [0|0] "" Vector__XXX
 SG_ APS_w216_driverOverriding : 23|1@1+ (1,0) [0|0] "" Vector__XXX
 SG_ APS_w217_lcUnavailableSpeeding : 24|1@1+ (1,0) [0|0] "" Vector__XXX
 SG_ APS_w218_lcSpeedExceededLimit : 25|1@1+ (1,0) [0|0] "" Vector__XXX
 SG_ APS_w219_lcTempUnavailableSpeed : 26|1@1+ (1,0) [0|0] "" Vector__XXX
 SG_ APS_w220_lcTempUnavailableRoad : 27|1@1+ (1,0) [0|0] "" Vector__XXX
 SG_ APS_w221_accRadarBlind : 28|1@1+ (1,0) [0|0] "" Vector__XXX
 SG_ APS_w222_accCameraBlind : 29|1@1+ (1,0) [0|0] "" Vector__XXX
 SG_ APS_w223_accObjectInPath : 30|1@1+ (1,0) [0|0] "" Vector__XXX
 SG_ APS_w224_accCameraCalibration : 31|1@1+ (1,0) [0|0] "" Vector__XXX
 SG_ APS_w225_lcDegradedVisSpeedLmt : 32|1@1+ (1,0) [0|0] "" Vector__XXX
 SG_ APS_w226_lcCamCalNeededSpeedLmt : 33|1@1+ (1,0) [0|0] "" Vector__XXX
 SG_ APS_w227_virtualWallBlocked : 34|1@1+ (1,0) [0|0] "" Vector__XXX
 SG_ APS_w228_DEPRECATED : 35|1@1+ (1,0) [0|0] "" Vector__XXX
 SG_ APS_w229_alcUltrasoundDamaged : 36|1@1+ (1,0) [0|0] "" Vector__XXX
 SG_ APS_w230_alcUltrasoundBlocked : 37|1@1+ (1,0) [0|0] "" Vector__XXX
 SG_ APS_w231_idfEvent : 38|1@1+ (1,0) [0|0] "" Vector__XXX
 SG_ APS_w232_laneChangeRequested : 39|1@1+ (1,0) [0|0] "" Vector__XXX
 SG_ APS_w235_a72LoopDetected : 42|1@1+ (1,0) [0|0] "" Vector__XXX
 SG_ APS_w236_canSharedMemError : 43|1@1+ (1,0) [0|0] "" Vector__XXX
 SG_ APS_w237_faultMgrEventDetected : 44|1@1+ (1,0) [0|0] "" Vector__XXX
 SG_ APS_w238_resetReason : 45|1@1+ (1,0) [0|0] "" Vector__XXX
 SG_ APS_w241_ddrInitFailures : 48|1@1+ (1,0) [0|0] "" Vector__XXX
 SG_ APS_w242_tripMBISTFailure : 49|1@1+ (1,0) [0|0] "" Vector__XXX
 SG_ APS_w243_tripHWErrorStatus : 50|1@1+ (1,0) [0|0] "" Vector__XXX
 SG_ APS_w244_gpuHWFaultStatus : 51|1@1+ (1,0) [0|0] "" Vector__XXX
 SG_ APS_w245_eloopRxFromUnexpectedSourceMAC : 52|1@1+ (1,0) [0|0] "" Vector__XXX
 SG_ APS_w246_ethloopSwitchPortLinkDown : 53|1@1+ (1,0) [0|0] "" Vector__XXX
 SG_ APS_w247_ethernetFrameError : 54|1@1+ (1,0) [0|0] "" Vector__XXX
 SG_ APS_w248_ethloopSwitchPoorSqi : 55|1@1+ (1,0) [0|0] "" Vector__XXX
 SG_ APS_w249_ufsFailures : 56|1@1+ (1,0) [0|0] "" Vector__XXX
 SG_ APS_w250_ethloopSwitchMemUsageTooHighPort2 : 57|1@1+ (1,0) [0|0] "" Vector__XXX
 SG_ APS_w251_ethloopSwitchMemUsageTooHighPort3 : 58|1@1+ (1,0) [0|0] "" Vector__XXX
 SG_ APS_w252_ethSwitchPortLinkDown : 59|1@1+ (1,0) [0|0] "" Vector__XXX
 SG_ APS_w253_powerStateTimeout : 60|1@1+ (1,0) [0|0] "" Vector__XXX
 SG_ APS_w254_sleepStateTimeout : 61|1@1+ (1,0) [0|0] "" Vector__XXX
 SG_ APS_w255_bootHealth : 62|1@1+ (1,0) [0|0] "" Vector__XXX

BO_ 849 RCM_info: 8 Vector__XXX
 SG_ RCM_infoIndex M : 0|8@1+ (1,0) [0|0] "" Vector__XXX
 SG_ RCM_infoAlgoCalID m22 : 8|8@1+ (1,0) [0|0] "" Vector__XXX
 SG_ RCM_infoBootUdsProtoVersion m20 : 8|8@1+ (1,0) [0|0] "" Vector__XXX
 SG_ RCM_infoBuildType m10 : 8|8@1+ (1,0) [0|0] "" Vector__XXX
 SG_ RCM_infoPcbaID m11 : 16|8@1+ (1,0) [0|0] "" Vector__XXX
 SG_ RCM_infoAssemblyID m11 : 24|8@1+ (1,0) [0|0] "" Vector__XXX
 SG_ RCM_infoApplicationCRC m13 : 32|32@1+ (1,0) [0|0] "" Vector__XXX
 SG_ RCM_infoBootloaderCRC m20 : 32|32@1+ (1,0) [0|0] "" Vector__XXX
 SG_ RCM_infoUsageID m11 : 32|16@1+ (1,0) [0|0] "" Vector__XXX
 SG_ RCM_infoVariantCRC m22 : 32|32@1+ (1,0) [0|0] "" Vector__XXX
 SG_ RCM_infoComponentID m10 : 48|16@1+ (1,0) [0|0] "" Vector__XXX

BO_ 850 TRCM_info: 8 Vector__XXX
 SG_ TRCM_infoIndex M : 0|8@1+ (1,0) [0|0] "" Vector__XXX
 SG_ TRCM_infoAppCrc m13 : 8|32@1+ (1,0) [0|0] "" Vector__XXX
 SG_ TRCM_infoAppGitHash m17 : 8|56@1+ (1,0) [0|0] "" Vector__XXX
 SG_ TRCM_infoBootGitHash m18 : 8|56@1+ (1,0) [0|0] "" Vector__XXX
 SG_ TRCM_infoBootUdsProtoVersion m20 : 8|8@1+ (1,0) [0|0] "" Vector__XXX
 SG_ TRCM_infoBuildType m10 : 8|8@1+ (1,0) [0|0] "" Vector__XXX
 SG_ TRCM_infoPcbaId m11 : 8|8@1+ (1,0) [0|0] "" Vector__XXX
 SG_ TRCM_infoPlatformType m19 : 8|8@1+ (1,0) [0|0] "" Vector__XXX
 SG_ TRCM_infoAssemblyId m11 : 16|8@1+ (1,0) [0|0] "" Vector__XXX
 SG_ TRCM_infoBuildConfigId m10 : 16|16@1+ (1,0) [0|0] "" Vector__XXX
 SG_ TRCM_infoBootCrc m20 : 24|32@1+ (1,0) [0|0] "" Vector__XXX
 SG_ TRCM_infoUsageId m11 : 24|16@1+ (1,0) [0|0] "" Vector__XXX
 SG_ TRCM_infoHardwareId m10 : 32|16@1+ (1,0) [0|0] "" Vector__XXX
 SG_ TRCM_infoSubUsageId m11 : 40|16@1+ (1,0) [0|0] "" Vector__XXX
 SG_ TRCM_infoComponentId m10 : 48|16@1+ (1,0) [0|0] "" Vector__XXX

BO_ 851 UI_status: 8 Vector__XXX
 SG_ UI_touchActive : 0|1@1+ (1,0) [0|0] "" Vector__XXX
 SG_ UI_audioActive : 1|1@1+ (1,0) [0|0] "" Vector__XXX
 SG_ UI_bluetoothActive : 2|1@1+ (1,0) [0|0] "" Vector__XXX
 SG_ UI_cellActive : 3|1@1+ (1,0) [0|0] "" Vector__XXX
 SG_ UI_displayReady : 4|1@1+ (1,0) [0|0] "" Vector__XXX
 SG_ UI_displayOn : 5|1@1+ (1,0) [0|0] "" Vector__XXX
 SG_ UI_wifiActive : 6|1@1+ (1,0) [0|0] "" Vector__XXX
 SG_ UI_wifiConnected : 7|1@1+ (1,0) [0|0] "" Vector__XXX
 SG_ UI_systemActive : 8|1@1+ (1,0) [0|0] "" Vector__XXX
 SG_ UI_readyForDrive : 9|1@1+ (1,0) [0|0] "" Vector__XXX
 SG_ UI_cellConnected : 10|1@1+ (1,0) [0|0] "" Vector__XXX
 SG_ UI_vpnActive : 11|1@1+ (1,0) [0|0] "" Vector__XXX
 SG_ UI_autopilotTrial : 12|2@1+ (1,0) [0|0] "" Vector__XXX
 SG_ UI_factoryReset : 14|2@1+ (1,0) [0|0] "" Vector__XXX
 SG_ UI_gpsActive : 16|1@1+ (1,0) [0|0] "" Vector__XXX
 SG_ UI_screenshotActive : 17|1@1+ (1,0) [0|0] "" Vector__XXX
 SG_ UI_radioActive : 18|1@1+ (1,0) [0|0] "" Vector__XXX
 SG_ UI_cellNetworkTechnology : 19|4@1+ (1,0) [0|0] "" Vector__XXX
 SG_ UI_cellReceiverPower : 24|8@1+ (1,-128) [0|0] "" Vector__XXX
 SG_ UI_falseTouchCounter : 32|8@1+ (1,0) [0|0] "" Vector__XXX
 SG_ UI_developmentCar : 40|1@1+ (1,0) [0|0] "" Vector__XXX
 SG_ UI_cameraActive : 41|1@1+ (1,0) [0|0] "" Vector__XXX
 SG_ UI_cellSignalBars : 42|3@1+ (1,0) [0|0] "" Vector__XXX
 SG_ UI_trailerModeTelltale : 45|2@1+ (1,0) [0|0] "" Vector__XXX
 SG_ UI_pcbTemperature : 48|8@1- (1,40) [0|0] "" Vector__XXX
 SG_ UI_cpuTemperature : 56|8@1- (1,40) [0|0] "" Vector__XXX

BO_ 856 UI_tpmsMode: 8 Vector__XXX
 SG_ UI_TPMSMode : 0|2@1+ (1,0) [0|0] "" Vector__XXX
 SG_ UI_TPMSLearnIDMode : 8|3@1+ (1,0) [0|0] "" Vector__XXX
 SG_ UI_sizeOfWheelSelect : 16|2@1+ (1,0) [0|0] "" Vector__XXX
 SG_ UI_sizeOfReqCANAutoLearn : 24|1@1+ (1,0) [0|0] "" Vector__XXX

BO_ 859 APP_visionOcsStatus: 8 Vector__XXX
 SG_ APP_visionOcsStatusChecksum : 0|8@1+ (1,0) [0|0] "" Vector__XXX
 SG_ APP_visionOcsStateRaw : 8|2@1+ (1,0) [0|0] "" Vector__XXX
 SG_ APP_visionOcsEmptyProbRaw : 10|8@1+ (0.004,0) [0|0] "" Vector__XXX
 SG_ APP_visionOcsChildProbRaw : 18|8@1+ (0.004,0) [0|0] "" Vector__XXX
 SG_ APP_visionOcsAdultProbRaw : 26|8@1+ (0.004,0) [0|0] "" Vector__XXX
 SG_ APP_visionOcsFrontPasClsVisionStateFlt : 34|2@1+ (1,0) [0|0] "" Vector__XXX
 SG_ APP_visionOcsStatusCounter : 36|4@1+ (1,0) [0|0] "" Vector__XXX
